VERSION "HNNBNNNYNNNNNNNNNNNNNNNNNNNNNNNNNNNNNNNNNN/4/%%%/4/'%**4NNN///"

NS_ :

BS_:

BU_: BAP_Tester BCM1 Gateway Klima_MSB Lift_VA VAS_L VAS_R

BO_ 1432 BCM_Taster_02: 8 BCM1
 SG_ BCM_BFS_Fernsteuerung_aktiv : 28|1@1+ (1.0,0.0) [0.0|1] ""  Gateway
 SG_ BCM_Soundklappe_Taster : 29|1@1+ (1.0,0.0) [0.0|1] ""  Gateway
 SG_ E_Sound_LED_Status : 30|2@1+ (1.0,0.0) [0.0|3] ""  Gateway
 SG_ Pilot_Taster : 32|2@1+ (1.0,0.0) [0.0|3] ""  Gateway
 SG_ BCM1_eSound_Taster : 34|2@1+ (1.0,0.0) [0.0|3] ""  Gateway
 SG_ BCM_FS_Programmwippe : 37|1@1+ (1.0,0.0) [0.0|1] ""  Gateway
 SG_ BCM_BFS_Programmwippe : 38|1@1+ (1.0,0.0) [0.0|1] ""  Gateway
 SG_ BCM_FS_Multif_Taster : 39|1@1+ (1.0,0.0) [0.0|1] ""  Gateway
 SG_ BCM_BFS_Multif_Taster : 40|1@1+ (1.0,0.0) [0.0|1] ""  Gateway
 SG_ BCM_FS_Massage_Taster : 41|1@1+ (1.0,0.0) [0.0|1] ""  Gateway
 SG_ BCM_BFS_Massage_Taster : 42|1@1+ (1.0,0.0) [0.0|1] ""  Gateway
 SG_ BCM_FS_Pneumatik_Verstellung : 43|1@1+ (1.0,0.0) [0.0|1] ""  Gateway
 SG_ BCM_BFS_Pneumatik_Verstellung : 44|1@1+ (1.0,0.0) [0.0|1] ""  Gateway
 SG_ LIM_Rear_Mode : 45|1@1+ (1.0,0.0) [0.0|1] ""  Gateway
 SG_ BCM1_NR_Ride_Height_Up_Taster : 46|2@1+ (1.0,0.0) [0.0|3] ""  Gateway
 SG_ BCM1_NR_Ride_Height_Down_Taster : 48|2@1+ (1.0,0.0) [0.0|3] ""  Gateway
 SG_ LIM_S_Rollo_vo : 50|3@1+ (1.0,0.0) [0.0|7] ""  Gateway
 SG_ LIM_S_Rollo_hi : 53|3@1+ (1.0,0.0) [0.0|7] ""  Gateway
 SG_ LIM_S_SAD_Vo : 56|4@1+ (1.0,0.0) [0.0|15] ""  Gateway
 SG_ LIM_S_SAD_hi : 60|4@1+ (1.0,0.0) [0.0|15] ""  Gateway

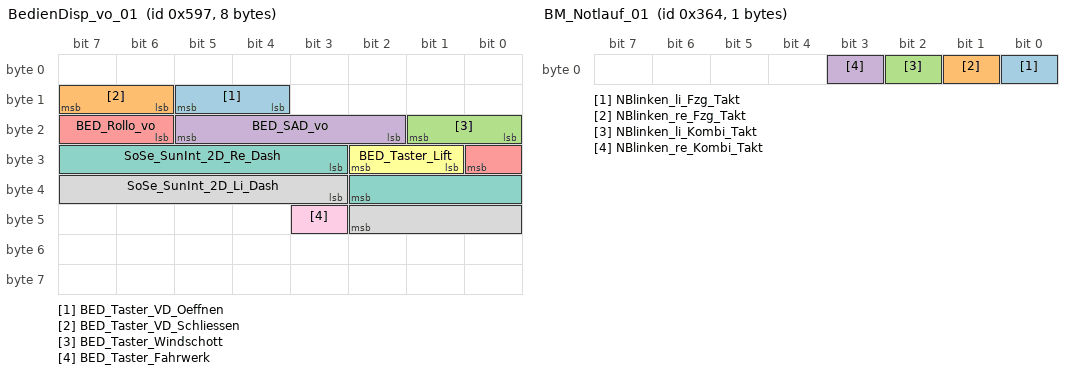
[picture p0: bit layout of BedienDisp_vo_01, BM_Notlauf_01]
BO_ 1431 BedienDisp_vo_01: 8 Gateway
 SG_ BED_Taster_VD_Oeffnen : 12|2@1+ (1.0,0.0) [0.0|3] ""  Vector__XXX
 SG_ BED_Taster_VD_Schliessen : 14|2@1+ (1.0,0.0) [0.0|3] ""  Vector__XXX
 SG_ BED_Taster_Windschott : 16|2@1+ (1.0,0.0) [0.0|3] ""  Vector__XXX
 SG_ BED_SAD_vo : 18|4@1+ (1.0,0.0) [0.0|15] ""  Vector__XXX
 SG_ BED_Rollo_vo : 22|3@1+ (1.0,0.0) [0.0|7] ""  Vector__XXX
 SG_ BED_Taster_Lift : 25|2@1+ (1.0,0.0) [0.0|3] ""  Lift_VA
 SG_ SoSe_SunInt_2D_Re_Dash : 27|8@1+ (5,0) [0|1200] "Unit_WattPerMeterSquar"  BCM1
 SG_ SoSe_SunInt_2D_Li_Dash : 35|8@1+ (5,0) [0|1200] "Unit_WattPerMeterSquar"  BCM1
 SG_ BED_Taster_Fahrwerk : 43|1@1+ (1.0,0.0) [0.0|1] ""  Vector__XXX

BO_ 870 Blinkmodi_02: 8 Gateway
 SG_ BM_ZV_auf : 12|1@1+ (1.0,0.0) [0.0|1] ""  BCM1
 SG_ BM_ZV_zu : 13|1@1+ (1.0,0.0) [0.0|1] ""  BCM1
 SG_ BM_DWA_ein : 14|1@1+ (1.0,0.0) [0.0|1] ""  BCM1
 SG_ BM_DWA_Alarm : 15|1@1+ (1.0,0.0) [0.0|1] ""  BCM1
 SG_ BM_Crash : 16|1@1+ (1.0,0.0) [0.0|1] ""  BCM1
 SG_ BM_Panik : 17|1@1+ (1.0,0.0) [0.0|1] ""  BCM1
 SG_ BM_Not_Bremsung : 18|1@1+ (1.0,0.0) [0.0|1] ""  BCM1
 SG_ BM_GDO : 19|1@1+ (1.0,0.0) [0.0|1] ""  BCM1
 SG_ BM_Warnblinken : 20|1@1+ (1.0,0.0) [0.0|1] ""  BCM1
 SG_ BM_Taxi_Notalarm : 21|1@1+ (1.0,0.0) [0.0|1] ""  BCM1
 SG_ BM_Telematik : 22|1@1+ (1.0,0.0) [0.0|1] ""  BCM1
 SG_ BM_links : 23|1@1+ (1.0,0.0) [0.0|1] ""  BCM1
 SG_ BM_rechts : 24|1@1+ (1.0,0.0) [0.0|1] ""  BCM1
 SG_ Blinken_li_Fzg_Takt : 25|1@1+ (1.0,0.0) [0.0|1] ""  BCM1,VAS_L
 SG_ Blinken_re_Fzg_Takt : 26|1@1+ (1.0,0.0) [0.0|1] ""  BCM1,VAS_R
 SG_ Blinken_li_Kombi_Takt : 27|1@1+ (1.0,0.0) [0.0|1] ""  Vector__XXX
 SG_ Blinken_re_Kombi_Takt : 28|1@1+ (1.0,0.0) [0.0|1] ""  Vector__XXX
 SG_ BM_NBA_n_codiert_n_aktiv : 29|1@1+ (1.0,0.0) [0.0|1] ""  Vector__XXX
 SG_ BM_NBA_Status : 30|2@1+ (1.0,0.0) [0.0|3] ""  Vector__XXX
 SG_ BM_WBT_Beleuchtung : 32|1@1+ (1.0,0.0) [0.0|1] ""  BCM1
 SG_ BM_HD_Oeffnung_angelernt : 33|1@1+ (1.0,0.0) [0.0|1] ""  BCM1
 SG_ BM_Autobahn : 34|1@1+ (1.0,0.0) [0.0|1] ""  BCM1
 SG_ BM_Rollenmodus_Blinken : 35|1@1+ (1.0,0.0) [0.0|1] ""  BCM1
 SG_ BM_Recas : 36|1@1+ (1.0,0.0) [0.0|1] ""  BCM1
 SG_ BM_Wischblinken : 37|1@1+ (1.0,0.0) [0.0|1] ""  BCM1
 SG_ BM_Telematik_Abbruchgrund : 38|6@1+ (1.0,0.0) [0.0|63] ""  Vector__XXX
 SG_ BM_PiloPa : 44|1@1+ (1.0,0.0) [0.0|1] ""  BCM1
 SG_ DWA_Alarmquelle : 59|5@1+ (1.0,0.0) [0.0|31] ""  Vector__XXX

BO_ 868 BM_Notlauf_01: 1 BCM1
 SG_ NBlinken_li_Fzg_Takt : 0|1@1+ (1.0,0.0) [0.0|1] ""  Gateway
 SG_ NBlinken_re_Fzg_Takt : 1|1@1+ (1.0,0.0) [0.0|1] ""  Gateway
 SG_ NBlinken_li_Kombi_Takt : 2|1@1+ (1.0,0.0) [0.0|1] ""  Gateway
 SG_ NBlinken_re_Kombi_Takt : 3|1@1+ (1.0,0.0) [0.0|1] ""  Gateway

BO_ 2617128448 CCP_Klima_CRO_01: 8 Vector__XXX
 SG_ CCP_Klima_CRO_01_Data : 0|64@1+ (1,0) [0|1] ""  BCM1,Klima_MSB

BO_ 2617128449 CCP_Klima_DTO_01: 8 BCM1
 SG_ CCP_Klima_DTO_01_Data : 0|64@1+ (1,0) [0|1] ""  Vector__XXX

BO_ 2617167360 CCP_Lift_VA_CRO_01: 8 Vector__XXX
 SG_ CCP_Lift_VA_CRO_01_Data : 0|64@1+ (1.0,0.0) [0.0|18446744073709551615] ""  Lift_VA

BO_ 2617167361 CCP_Lift_VA_DTO_01: 8 Lift_VA
 SG_ CCP_Lift_VA_DTO_01_Data : 0|64@1+ (1.0,0.0) [0.0|18446744073709551615] ""  Vector__XXX

BO_ 901 Charisma_01: 8 Gateway
 SG_ CHA_Ziel_FahrPr_AGA : 0|4@1+ (1.0,0.0) [0.0|15] ""  Vector__XXX
 SG_ CHA_Ziel_FahrPr_ESP : 4|4@1+ (1.0,0.0) [0.0|15] ""  Vector__XXX
 SG_ CHA_Ziel_FahrPr_Freilauf : 8|4@1+ (1.0,0.0) [0.0|15] ""  Vector__XXX
 SG_ CHA_Fahrer_Umschaltung : 14|1@1+ (1.0,0.0) [0.0|1] ""  Vector__XXX
 SG_ CHA_Fahrer_Umschaltung_BMA : 15|1@1+ (1.0,0.0) [0.0|1] ""  Vector__XXX
 SG_ CHA_Ziel_FahrPr_MO : 16|4@1+ (1.0,0.0) [0.0|15] ""  Vector__XXX
 SG_ CHA_Ziel_FahrPr_GE : 20|4@1+ (1.0,0.0) [0.0|15] ""  Vector__XXX
 SG_ CHA_Ziel_FahrPr_ALR : 24|4@1+ (1.0,0.0) [0.0|15] ""  Vector__XXX
 SG_ CHA_Ziel_FahrPr_MO_BZS : 28|4@1+ (1.0,0.0) [0.0|15] ""  BCM1
 SG_ CHA_Ziel_FahrPr_DR : 32|4@1+ (1.0,0.0) [0.0|15] ""  Vector__XXX
 SG_ CHA_Ziel_FahrPr_VAQ : 36|4@1+ (1.0,0.0) [0.0|15] ""  Vector__XXX
 SG_ CHA_Ziel_FahrPr_AFS : 40|4@1+ (1.0,0.0) [0.0|15] ""  BCM1
 SG_ CHA_Ziel_FahrPr_PreCrash : 44|4@1+ (1.0,0.0) [0.0|15] ""  Vector__XXX
 SG_ CHA_Ziel_FahrPr_EPS : 48|4@1+ (1.0,0.0) [0.0|15] ""  Vector__XXX
 SG_ CHA_Ziel_FahrPr_ACC : 52|4@1+ (1.0,0.0) [0.0|15] ""  Vector__XXX
 SG_ CHA_Ziel_FahrPr_SAK : 56|4@1+ (1.0,0.0) [0.0|15] ""  Vector__XXX
 SG_ CHA_Ziel_FahrPr_MO_StSt : 60|4@1+ (1.0,0.0) [0.0|15] ""  Vector__XXX

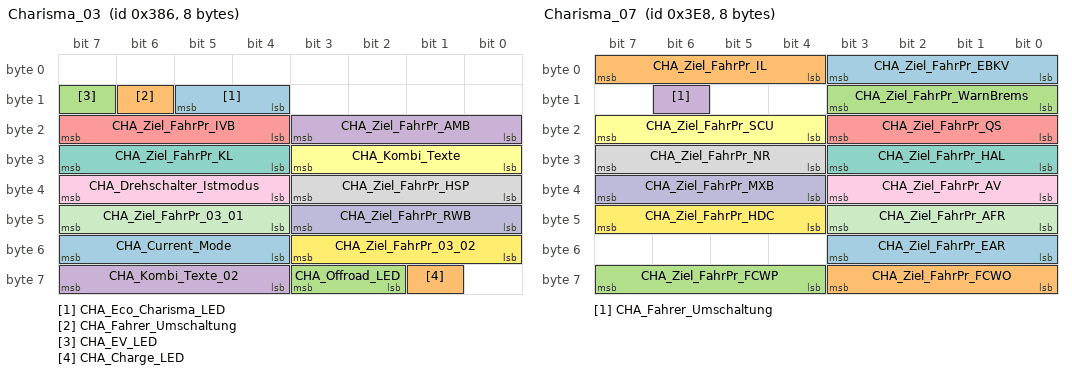
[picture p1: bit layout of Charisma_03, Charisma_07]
BO_ 902 Charisma_03: 8 Gateway
 SG_ CHA_Eco_Charisma_LED : 12|2@1+ (1.0,0.0) [0.0|3] ""  BCM1
 SG_ CHA_Fahrer_Umschaltung : 14|1@1+ (1.0,0.0) [0.0|1] ""  BCM1,Klima_MSB
 SG_ CHA_EV_LED : 15|1@1+ (1.0,0.0) [0.0|1] ""  BCM1
 SG_ CHA_Ziel_FahrPr_AMB : 16|4@1+ (1.0,0.0) [0.0|15] ""  BCM1
 SG_ CHA_Ziel_FahrPr_IVB : 20|4@1+ (1.0,0.0) [0.0|15] ""  Vector__XXX
 SG_ CHA_Kombi_Texte : 24|4@1+ (1.0,0.0) [0.0|15] ""  Vector__XXX
 SG_ CHA_Ziel_FahrPr_KL : 28|4@1+ (1.0,0.0) [0.0|15] ""  BCM1,Klima_MSB
 SG_ CHA_Ziel_FahrPr_HSP : 32|4@1+ (1.0,0.0) [0.0|15] ""  Vector__XXX
 SG_ CHA_Drehschalter_Istmodus : 36|4@1+ (1.0,0.0) [0.0|15] ""  BCM1
 SG_ CHA_Ziel_FahrPr_RWB : 40|4@1+ (1.0,0.0) [0.0|15] ""  Vector__XXX
 SG_ CHA_Ziel_FahrPr_03_01 : 44|4@1+ (1.0,0.0) [0.0|15] ""  Vector__XXX
 SG_ CHA_Ziel_FahrPr_03_02 : 48|4@1+ (1.0,0.0) [0.0|15] ""  Vector__XXX
 SG_ CHA_Current_Mode : 52|4@1+ (1.0,0.0) [0.0|15] ""  Vector__XXX
 SG_ CHA_Charge_LED : 57|1@1+ (1.0,0.0) [0.0|1] ""  Vector__XXX
 SG_ CHA_Offroad_LED : 58|2@1+ (1.0,0.0) [0.0|3] ""  Vector__XXX
 SG_ CHA_Kombi_Texte_02 : 60|4@1+ (1.0,0.0) [0.0|15] ""  Vector__XXX

BO_ 1000 Charisma_07: 8 Gateway
 SG_ CHA_Ziel_FahrPr_EBKV : 0|4@1+ (1.0,0.0) [0.0|15] ""  Vector__XXX
 SG_ CHA_Ziel_FahrPr_IL : 4|4@1+ (1.0,0.0) [0.0|15] ""  Vector__XXX
 SG_ CHA_Ziel_FahrPr_WarnBrems : 8|4@1+ (1.0,0.0) [0.0|15] ""  Vector__XXX
 SG_ CHA_Fahrer_Umschaltung : 14|1@1+ (1.0,0.0) [0.0|1] ""  Vector__XXX
 SG_ CHA_Ziel_FahrPr_QS : 16|4@1+ (1.0,0.0) [0.0|15] ""  Vector__XXX
 SG_ CHA_Ziel_FahrPr_SCU : 20|4@1+ (1.0,0.0) [0.0|15] ""  Vector__XXX
 SG_ CHA_Ziel_FahrPr_HAL : 24|4@1+ (1.0,0.0) [0.0|15] ""  Vector__XXX
 SG_ CHA_Ziel_FahrPr_NR : 28|4@1+ (1.0,0.0) [0.0|15] ""  Vector__XXX
 SG_ CHA_Ziel_FahrPr_AV : 32|4@1+ (1.0,0.0) [0.0|15] ""  BCM1
 SG_ CHA_Ziel_FahrPr_MXB : 36|4@1+ (1.0,0.0) [0.0|15] ""  Vector__XXX
 SG_ CHA_Ziel_FahrPr_AFR : 40|4@1+ (1.0,0.0) [0.0|15] ""  Vector__XXX
 SG_ CHA_Ziel_FahrPr_HDC : 44|4@1+ (1.0,0.0) [0.0|15] ""  Vector__XXX
 SG_ CHA_Ziel_FahrPr_EAR : 48|4@1+ (1.0,0.0) [0.0|15] ""  Vector__XXX
 SG_ CHA_Ziel_FahrPr_FCWO : 56|4@1+ (1.0,0.0) [0.0|15] ""  Vector__XXX
 SG_ CHA_Ziel_FahrPr_FCWP : 60|4@1+ (1.0,0.0) [0.0|15] ""  Vector__XXX

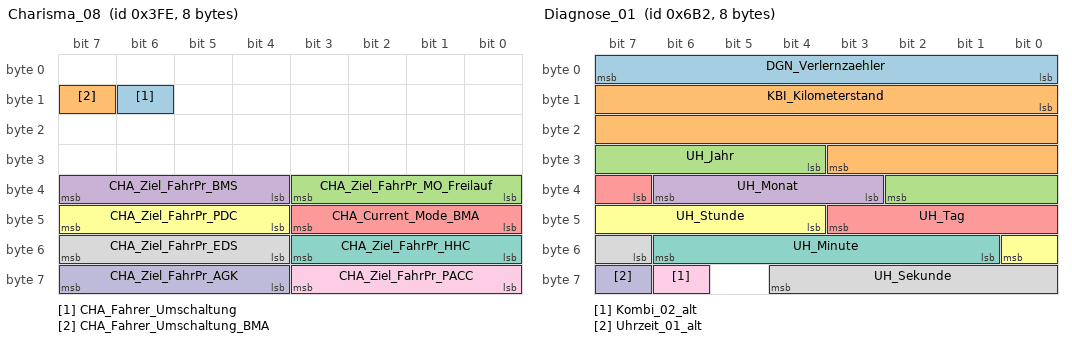
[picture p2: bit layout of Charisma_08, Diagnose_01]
BO_ 1022 Charisma_08: 8 Gateway
 SG_ CHA_Fahrer_Umschaltung : 14|1@1+ (1.0,0.0) [0.0|1] ""  Vector__XXX
 SG_ CHA_Fahrer_Umschaltung_BMA : 15|1@1+ (1.0,0.0) [0.0|1] ""  Vector__XXX
 SG_ CHA_Ziel_FahrPr_MO_Freilauf : 32|4@1+ (1.0,0.0) [0.0|15] ""  Vector__XXX
 SG_ CHA_Ziel_FahrPr_BMS : 36|4@1+ (1.0,0.0) [0.0|15] ""  Vector__XXX
 SG_ CHA_Current_Mode_BMA : 40|4@1+ (1.0,0.0) [0.0|15] ""  Vector__XXX
 SG_ CHA_Ziel_FahrPr_PDC : 44|4@1+ (1.0,0.0) [0.0|15] ""  BCM1
 SG_ CHA_Ziel_FahrPr_HHC : 48|4@1+ (1.0,0.0) [0.0|15] ""  Vector__XXX
 SG_ CHA_Ziel_FahrPr_EDS : 52|4@1+ (1.0,0.0) [0.0|15] ""  Vector__XXX
 SG_ CHA_Ziel_FahrPr_PACC : 56|4@1+ (1.0,0.0) [0.0|15] ""  Vector__XXX
 SG_ CHA_Ziel_FahrPr_AGK : 60|4@1+ (1.0,0.0) [0.0|15] ""  Vector__XXX

BO_ 2617012736 DEV_BCM1_Resp_00: 8 BCM1
 SG_ DEV_BCM1_Resp_00_Data : 0|64@1+ (1.0,0.0) [0.0|18446744073709551615] ""  Vector__XXX

BO_ 2617012991 DEV_BCM1_Resp_FF: 8 BCM1
 SG_ DEV_BCM1_Resp_FF_Data : 0|64@1+ (1.0,0.0) [0.0|18446744073709551615] ""  Vector__XXX

BO_ 2617037312 DEV_Klima_Fond_Tx_00: 8 BCM1
 SG_ DEV_Klima_Fond_Tx_00_Data : 0|64@1+ (1.0,0.0) [0.0|18446744073709551615] ""  Vector__XXX

BO_ 2617037567 DEV_Klima_Fond_Tx_FF: 8 BCM1
 SG_ DEV_Klima_Fond_Tx_FF_Data : 0|64@1+ (1.0,0.0) [0.0|18446744073709551615] ""  Vector__XXX

BO_ 2617127424 DEV_Klima_Tx_00: 8 BCM1
 SG_ DEV_Klima_Tx_00_Data : 0|64@1+ (1.0,0.0) [0.0|18446744073709551615] ""  Vector__XXX

BO_ 2617127679 DEV_Klima_Tx_FF: 8 BCM1
 SG_ DEV_Klima_Tx_FF_Data : 0|64@1+ (1.0,0.0) [0.0|18446744073709551615] ""  Vector__XXX

BO_ 2617166336 DEV_Lift_VA_Req_01: 8 Vector__XXX
 SG_ DEV_Lift_VA_Req_01_Data : 0|64@1+ (1.0,0.0) [0.0|18446744073709551615] ""  Lift_VA

BO_ 2617166337 DEV_Lift_VA_Resp_01: 8 Lift_VA
 SG_ DEV_Lift_VA_Resp_01_Data : 0|64@1+ (1.0,0.0) [0.0|18446744073709551615] ""  Vector__XXX

BO_ 2617166591 DEV_Lift_VA_Resp_FF: 8 Lift_VA
 SG_ DEV_Lift_VA_Resp_FF_Data : 0|64@1+ (1.0,0.0) [0.0|18446744073709551615] ""  Vector__XXX

BO_ 2617123584 DEV_VAS_L_Resp_00: 8 VAS_L
 SG_ DEV_VAS_L_Resp_00_Data : 0|64@1+ (1.0,0.0) [0.0|18446744073709551615] ""  Vector__XXX

BO_ 2617123839 DEV_VAS_L_Resp_FF: 8 VAS_L
 SG_ DEV_VAS_L_Resp_FF_Data : 0|64@1+ (1.0,0.0) [0.0|18446744073709551615] ""  Vector__XXX

BO_ 2617125632 DEV_VAS_R_Resp_00: 8 VAS_R
 SG_ DEV_VAS_R_Resp_00_Data : 0|64@1+ (1.0,0.0) [0.0|18446744073709551615] ""  Vector__XXX

BO_ 2617125887 DEV_VAS_R_Resp_FF: 8 VAS_R
 SG_ DEV_VAS_R_Resp_FF_Data : 0|64@1+ (1.0,0.0) [0.0|18446744073709551615] ""  Vector__XXX

BO_ 2549880614 DIA_AAU_Req: 8 Gateway
 SG_ DIA_AAU_Req_Data : 0|64@1+ (1.0,0.0) [0.0|18446744073709551615] ""  BCM1,Klima_MSB

BO_ 2550011686 DIA_AAU_Resp: 8 BCM1
 SG_ DIA_AAU_Resp_Data : 0|64@1+ (1.0,0.0) [0.0|18446744073709551615] ""  Gateway

BO_ 2549880393 DIA_EVLS_Req: 8 Gateway
 SG_ DIA_EVLS_Req_Data : 0|64@1+ (1.0,0.0) [0.0|18446744073709551615] ""  BCM1

BO_ 2550011465 DIA_EVLS_Resp: 8 BCM1
 SG_ DIA_EVLS_Resp_Data : 0|64@1+ (1.0,0.0) [0.0|18446744073709551615] ""  Gateway

BO_ 2549880347 DIA_Geblaese_Req: 8 Gateway
 SG_ DIA_Geblaese_Req_Data : 0|64@1+ (1.0,0.0) [0.0|18446744073709551615] ""  BCM1,Klima_MSB

BO_ 2550011419 DIA_Geblaese_Resp: 8 BCM1
 SG_ DIA_Geblaese_Resp_Data : 0|64@1+ (1.0,0.0) [0.0|18446744073709551615] ""  Gateway

BO_ 2549880340 DIA_gLW_LM_L_Req: 8 Gateway
 SG_ DIA_gLW_LM_L_Req_Data : 0|64@1+ (1.0,0.0) [0.0|18446744073709551615] ""  BCM1

BO_ 2550011412 DIA_gLW_LM_L_Resp: 8 BCM1
 SG_ DIA_gLW_LM_L_Resp_Data : 0|64@1+ (1.0,0.0) [0.0|18446744073709551615] ""  Gateway

BO_ 2549880341 DIA_gLW_LM_R_Req: 8 Gateway
 SG_ DIA_gLW_LM_R_Req_Data : 0|64@1+ (1.0,0.0) [0.0|18446744073709551615] ""  BCM1

BO_ 2550011413 DIA_gLW_LM_R_Resp: 8 BCM1
 SG_ DIA_gLW_LM_R_Resp_Data : 0|64@1+ (1.0,0.0) [0.0|18446744073709551615] ""  Gateway

BO_ 2549880577 DIA_KBF_Req: 8 Gateway
 SG_ DIA_KBF_Req_Data : 0|64@1+ (1.0,0.0) [0.0|18446744073709551615] ""  BCM1,Klima_MSB

BO_ 2550011649 DIA_KBF_Resp: 8 BCM1
 SG_ DIA_KBF_Resp_Data : 0|64@1+ (1.0,0.0) [0.0|18446744073709551615] ""  Gateway

BO_ 2549880639 DIA_KPV_Req: 8 Gateway
 SG_ DIA_KPV_Req_Data : 0|64@1+ (1.0,0.0) [0.0|18446744073709551615] ""  BCM1

BO_ 2550011711 DIA_KPV_Resp: 8 BCM1
 SG_ DIA_KPV_Resp_Data : 0|64@1+ (1.0,0.0) [0.0|18446744073709551615] ""  Gateway

BO_ 2549880330 DIA_LED_LM_L_Req: 8 Gateway
 SG_ DIA_LED_LM_L_Req_Data : 0|64@1+ (1.0,0.0) [0.0|18446744073709551615] ""  BCM1

BO_ 2550011402 DIA_LED_LM_L_Resp: 8 BCM1
 SG_ DIA_LED_LM_L_Resp_Data : 0|64@1+ (1.0,0.0) [0.0|18446744073709551615] ""  Gateway

BO_ 2549880331 DIA_LED_LM_R_Req: 8 Gateway
 SG_ DIA_LED_LM_R_Req_Data : 0|64@1+ (1.0,0.0) [0.0|18446744073709551615] ""  BCM1

BO_ 2550011403 DIA_LED_LM_R_Resp: 8 BCM1
 SG_ DIA_LED_LM_R_Resp_Data : 0|64@1+ (1.0,0.0) [0.0|18446744073709551615] ""  Gateway

BO_ 2549880633 DIA_LIM2_Req: 8 Gateway
 SG_ DIA_LIM2_Req_Data : 0|64@1+ (1.0,0.0) [0.0|18446744073709551615] ""  BCM1

BO_ 2550011705 DIA_LIM2_Resp: 8 BCM1
 SG_ DIA_LIM2_Resp_Data : 0|64@1+ (1.0,0.0) [0.0|18446744073709551615] ""  Gateway

BO_ 2549880350 DIA_LIM_Req: 8 Gateway
 SG_ DIA_LIM_Req_Data : 0|64@1+ (1.0,0.0) [0.0|18446744073709551615] ""  BCM1

BO_ 2550011422 DIA_LIM_Resp: 8 BCM1
 SG_ DIA_LIM_Resp_Data : 0|64@1+ (1.0,0.0) [0.0|18446744073709551615] ""  Gateway

BO_ 2549880427 DIA_MXB_LM_L_Req: 8 Gateway
 SG_ DIA_MXB_LM_L_Req_Data : 0|64@1+ (1.0,0.0) [0.0|18446744073709551615] ""  BCM1

BO_ 2550011499 DIA_MXB_LM_L_Resp: 8 BCM1
 SG_ DIA_MXB_LM_L_Resp_Data : 0|64@1+ (1.0,0.0) [0.0|18446744073709551615] ""  Gateway

BO_ 2549880428 DIA_MXB_LM_R_Req: 8 Gateway
 SG_ DIA_MXB_LM_R_Req_Data : 0|64@1+ (1.0,0.0) [0.0|18446744073709551615] ""  BCM1

BO_ 2550011500 DIA_MXB_LM_R_Resp: 8 BCM1
 SG_ DIA_MXB_LM_R_Resp_Data : 0|64@1+ (1.0,0.0) [0.0|18446744073709551615] ""  Gateway

BO_ 2549880612 DIA_SWP_Req: 8 Gateway
 SG_ DIA_SWP_Req_Data : 0|64@1+ (1.0,0.0) [0.0|18446744073709551615] ""  BCM1

BO_ 2550011684 DIA_SWP_Resp: 8 BCM1
 SG_ DIA_SWP_Resp_Data : 0|64@1+ (1.0,0.0) [0.0|18446744073709551615] ""  Gateway

BO_ 2549880324 DIA_UGDO_S_Req: 8 Gateway
 SG_ DIA_UGDO_S_Req_Data : 0|64@1+ (1.0,0.0) [0.0|18446744073709551615] ""  BCM1

BO_ 2550011396 DIA_UGDO_S_Resp: 8 BCM1
 SG_ DIA_UGDO_S_Resp_Data : 0|64@1+ (1.0,0.0) [0.0|18446744073709551615] ""  Gateway

BO_ 2549880321 DIA_WWS_Req: 8 Gateway
 SG_ DIA_WWS_Req_Data : 0|64@1+ (1.0,0.0) [0.0|18446744073709551615] ""  BCM1

BO_ 2550011393 DIA_WWS_Resp: 8 BCM1
 SG_ DIA_WWS_Resp_Data : 0|64@1+ (1.0,0.0) [0.0|18446744073709551615] ""  Gateway

BO_ 1714 Diagnose_01: 8 Gateway
 SG_ DGN_Verlernzaehler : 0|8@1+ (1,0) [0|254] ""  BCM1,Klima_MSB,Lift_VA,VAS_L,VAS_R
 SG_ KBI_Kilometerstand : 8|20@1+ (1,0) [0|1048573] "Unit_KiloMeter"  BCM1,Klima_MSB,Lift_VA,VAS_L
 SG_ UH_Jahr : 28|7@1+ (1,2000) [2000|2127] "Unit_Year"  BCM1,Klima_MSB,Lift_VA,VAS_L,VAS_R
 SG_ UH_Monat : 35|4@1+ (1,0) [1|12] "Unit_Month"  BCM1,Klima_MSB,Lift_VA,VAS_L,VAS_R
 SG_ UH_Tag : 39|5@1+ (1,0) [1|31] "Unit_Day"  BCM1,Klima_MSB,Lift_VA,VAS_L,VAS_R
 SG_ UH_Stunde : 44|5@1+ (1,0) [0|23] "Unit_Hours"  BCM1,Klima_MSB,Lift_VA,VAS_L,VAS_R
 SG_ UH_Minute : 49|6@1+ (1,0) [0|59] "Unit_Minut"  BCM1,Klima_MSB,Lift_VA,VAS_L,VAS_R
 SG_ UH_Sekunde : 55|6@1+ (1,0) [0|59] "Unit_Secon"  BCM1,Klima_MSB,Lift_VA,VAS_L,VAS_R
 SG_ Kombi_02_alt : 62|1@1+ (1.0,0.0) [0.0|1] ""  Vector__XXX
 SG_ Uhrzeit_01_alt : 63|1@1+ (1.0,0.0) [0.0|1] ""  BCM1,VAS_L,VAS_R

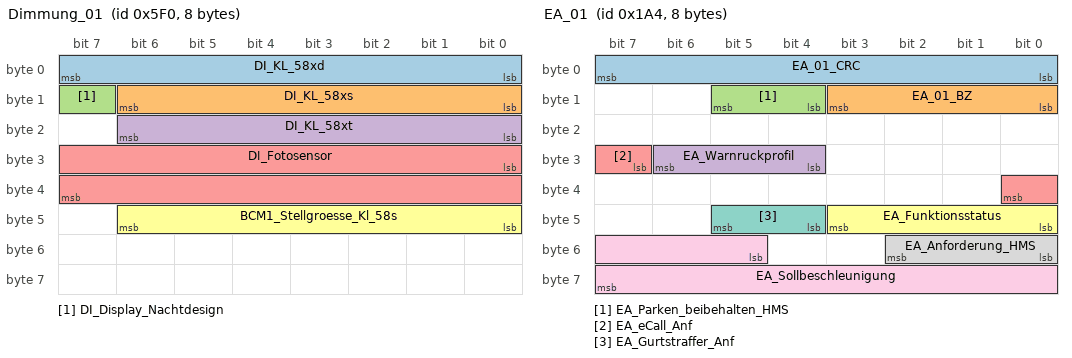
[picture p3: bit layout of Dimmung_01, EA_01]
BO_ 1520 Dimmung_01: 8 BCM1
 SG_ DI_KL_58xd : 0|8@1+ (1,0) [0|253] ""  Gateway,Klima_MSB,VAS_L,VAS_R
 SG_ DI_KL_58xs : 8|7@1+ (1,0) [0|100] "Unit_PerCent"  Gateway,Klima_MSB,VAS_L,VAS_R
 SG_ DI_Display_Nachtdesign : 15|1@1+ (1.0,0.0) [0.0|1] ""  Gateway,VAS_L,VAS_R
 SG_ DI_KL_58xt : 16|7@1+ (1,0) [0|100] "Unit_PerCent"  Gateway,VAS_L,VAS_R
 SG_ DI_Fotosensor : 24|16@1+ (1,0) [0|65535] ""  Gateway,VAS_L,VAS_R
 SG_ BCM1_Stellgroesse_Kl_58s : 40|7@1+ (1,0) [0|100] ""  Gateway

BO_ 420 EA_01: 8 Gateway
 SG_ EA_01_CRC : 0|8@1+ (1,0) [0|255] ""  Vector__XXX
 SG_ EA_01_BZ : 8|4@1+ (1,0) [0|15] ""  Vector__XXX
 SG_ EA_Parken_beibehalten_HMS : 12|2@1+ (1.0,0.0) [0.0|3] ""  Vector__XXX
 SG_ EA_Warnruckprofil : 28|3@1+ (1.0,0.0) [0.0|7] ""  Vector__XXX
 SG_ EA_eCall_Anf : 31|2@1+ (1.0,0.0) [0.0|3] ""  Vector__XXX
 SG_ EA_Funktionsstatus : 40|4@1+ (1.0,0.0) [0.0|15] ""  BCM1
 SG_ EA_Gurtstraffer_Anf : 44|2@1+ (1.0,0.0) [0.0|3] ""  Vector__XXX
 SG_ EA_Anforderung_HMS : 48|3@1+ (1.0,0.0) [0.0|7] ""  Vector__XXX
 SG_ EA_Sollbeschleunigung : 53|11@1+ (0.005,-7.22) [-7.220|3.005] "Unit_MeterPerSeconSquar"  Vector__XXX

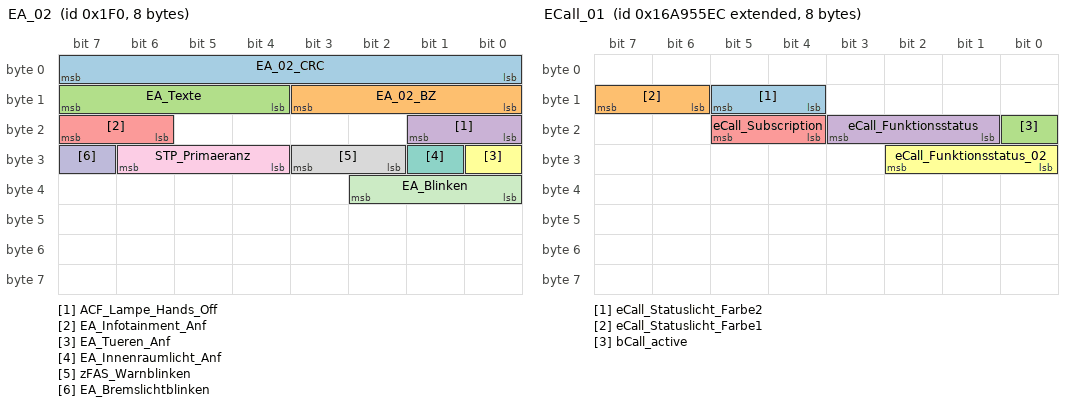
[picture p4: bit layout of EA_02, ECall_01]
BO_ 496 EA_02: 8 Gateway
 SG_ EA_02_CRC : 0|8@1+ (1,0) [0|255] ""  Vector__XXX
 SG_ EA_02_BZ : 8|4@1+ (1,0) [0|15] ""  Vector__XXX
 SG_ EA_Texte : 12|4@1+ (1.0,0.0) [0.0|15] ""  Vector__XXX
 SG_ ACF_Lampe_Hands_Off : 16|2@1+ (1.0,0.0) [0.0|3] ""  Vector__XXX
 SG_ EA_Infotainment_Anf : 22|2@1+ (1.0,0.0) [0.0|3] ""  Vector__XXX
 SG_ EA_Tueren_Anf : 24|1@1+ (1.0,0.0) [0.0|1] ""  Vector__XXX
 SG_ EA_Innenraumlicht_Anf : 25|1@1+ (1.0,0.0) [0.0|1] ""  BCM1
 SG_ zFAS_Warnblinken : 26|2@1+ (1.0,0.0) [0.0|3] ""  Vector__XXX
 SG_ STP_Primaeranz : 28|3@1+ (1.0,0.0) [0.0|7] ""  Vector__XXX
 SG_ EA_Bremslichtblinken : 31|1@1+ (1.0,0.0) [0.0|1] ""  Vector__XXX
 SG_ EA_Blinken : 32|3@1+ (1.0,0.0) [0.0|7] ""  Vector__XXX

BO_ 2527679980 ECall_01: 8 Gateway
 SG_ eCall_Statuslicht_Farbe2 : 12|2@1+ (1.0,0.0) [0.0|3] ""  BCM1
 SG_ eCall_Statuslicht_Farbe1 : 14|2@1+ (1.0,0.0) [0.0|3] ""  BCM1
 SG_ bCall_active : 16|1@1+ (1.0,0.0) [0.0|1] ""  BCM1
 SG_ eCall_Funktionsstatus : 17|3@1+ (1.0,0.0) [0.0|7] ""  Vector__XXX
 SG_ eCall_Subscription : 20|2@1+ (1.0,0.0) [0.0|3] ""  Vector__XXX
 SG_ eCall_Funktionsstatus_02 : 24|3@1+ (1.0,0.0) [0.0|7] ""  Vector__XXX

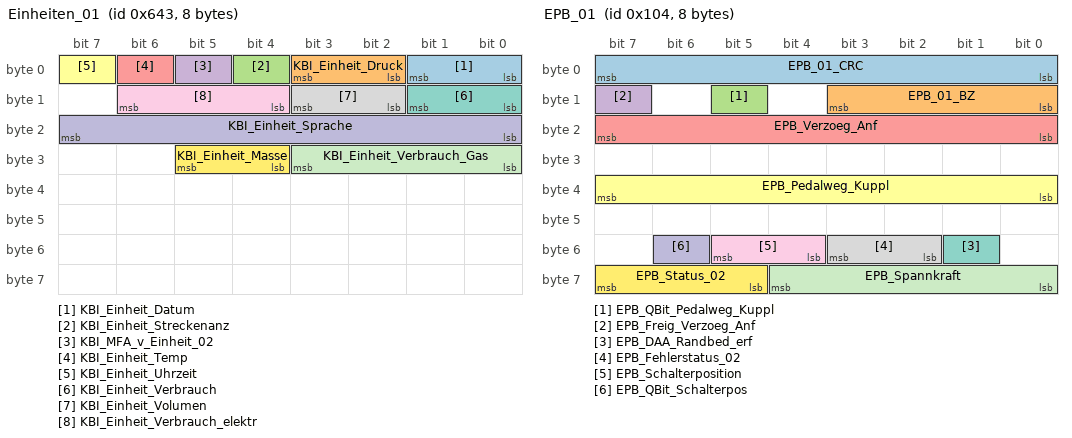
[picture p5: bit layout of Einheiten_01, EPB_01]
BO_ 1603 Einheiten_01: 8 Gateway
 SG_ KBI_Einheit_Datum : 0|2@1+ (1.0,0.0) [0.0|3] ""  Vector__XXX
 SG_ KBI_Einheit_Druck : 2|2@1+ (1.0,0.0) [0.0|3] ""  Vector__XXX
 SG_ KBI_Einheit_Streckenanz : 4|1@1+ (1.0,0.0) [0.0|1] ""  Vector__XXX
 SG_ KBI_MFA_v_Einheit_02 : 5|1@1+ (1.0,0.0) [0.0|1] ""  Vector__XXX
 SG_ KBI_Einheit_Temp : 6|1@1+ (1.0,0.0) [0.0|1] ""  BCM1,Klima_MSB
 SG_ KBI_Einheit_Uhrzeit : 7|1@1+ (1.0,0.0) [0.0|1] ""  Vector__XXX
 SG_ KBI_Einheit_Verbrauch : 8|2@1+ (1.0,0.0) [0.0|3] ""  Vector__XXX
 SG_ KBI_Einheit_Volumen : 10|2@1+ (1.0,0.0) [0.0|3] ""  Vector__XXX
 SG_ KBI_Einheit_Verbrauch_elektr : 12|3@1+ (1.0,0.0) [0.0|7] ""  Vector__XXX
 SG_ KBI_Einheit_Sprache : 16|8@1+ (1,0) [0|255] ""  Vector__XXX
 SG_ KBI_Einheit_Verbrauch_Gas : 24|4@1+ (1.0,0.0) [0.0|15] ""  Vector__XXX
 SG_ KBI_Einheit_Masse : 28|2@1+ (1.0,0.0) [0.0|3] ""  Vector__XXX

BO_ 260 EPB_01: 8 Gateway
 SG_ EPB_01_CRC : 0|8@1+ (1,0) [0|255] ""  Vector__XXX
 SG_ EPB_01_BZ : 8|4@1+ (1,0) [0|15] ""  Vector__XXX
 SG_ EPB_QBit_Pedalweg_Kuppl : 13|1@1+ (1.0,0.0) [0.0|1] ""  Vector__XXX
 SG_ EPB_Freig_Verzoeg_Anf : 15|1@1+ (1.0,0.0) [0.0|1] ""  Vector__XXX
 SG_ EPB_Verzoeg_Anf : 16|8@1+ (0.048,-7.968) [-7.968|4.224] "Unit_MeterPerSeconSquar"  Vector__XXX
 SG_ EPB_Pedalweg_Kuppl : 32|8@1+ (0.4,0) [8.0|92.0] "Unit_PerCent"  Vector__XXX
 SG_ EPB_DAA_Randbed_erf : 49|1@1+ (1.0,0.0) [0.0|1] ""  Vector__XXX
 SG_ EPB_Fehlerstatus_02 : 50|2@1+ (1.0,0.0) [0.0|3] ""  BCM1
 SG_ EPB_Schalterposition : 52|2@1+ (1.0,0.0) [0.0|3] ""  Vector__XXX
 SG_ EPB_QBit_Schalterpos : 54|1@1+ (1.0,0.0) [0.0|1] ""  Vector__XXX
 SG_ EPB_Spannkraft : 56|5@1+ (1,0) [0|29] "Unit_KiloNewto"  Vector__XXX
 SG_ EPB_Status_02 : 61|3@1+ (1.0,0.0) [0.0|7] ""  BCM1

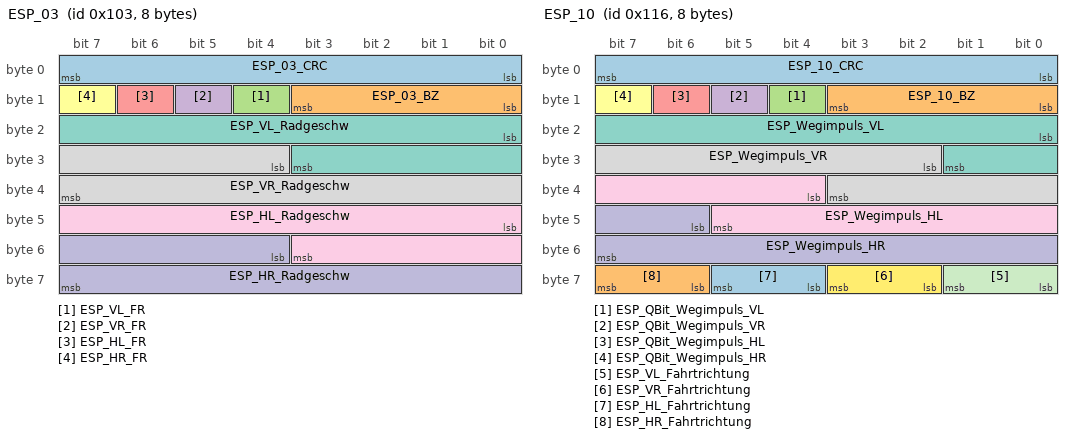
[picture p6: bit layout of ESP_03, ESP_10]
BO_ 259 ESP_03: 8 Gateway
 SG_ ESP_03_CRC : 0|8@1+ (1,0) [0|255] ""  Vector__XXX
 SG_ ESP_03_BZ : 8|4@1+ (1,0) [0|15] ""  Vector__XXX
 SG_ ESP_VL_FR : 12|1@1+ (1.0,0.0) [0.0|1] ""  BCM1,VAS_L,VAS_R
 SG_ ESP_VR_FR : 13|1@1+ (1.0,0.0) [0.0|1] ""  BCM1,VAS_L,VAS_R
 SG_ ESP_HL_FR : 14|1@1+ (1.0,0.0) [0.0|1] ""  BCM1,VAS_L,VAS_R
 SG_ ESP_HR_FR : 15|1@1+ (1.0,0.0) [0.0|1] ""  BCM1,VAS_L,VAS_R
 SG_ ESP_VL_Radgeschw : 16|12@1+ (0.1,0) [0.0|409.2] "Unit_KiloMeterPerHour"  BCM1,VAS_L,VAS_R
 SG_ ESP_VR_Radgeschw : 28|12@1+ (0.1,0) [0.0|409.2] "Unit_KiloMeterPerHour"  BCM1,VAS_L,VAS_R
 SG_ ESP_HL_Radgeschw : 40|12@1+ (0.1,0) [0.0|409.2] "Unit_KiloMeterPerHour"  BCM1,VAS_L,VAS_R
 SG_ ESP_HR_Radgeschw : 52|12@1+ (0.1,0) [0.0|409.2] "Unit_KiloMeterPerHour"  BCM1,VAS_L,VAS_R

BO_ 914 ESP_07: 8 Gateway
 SG_ ESP_07_CRC : 0|8@1+ (1,0) [0|255] ""  Vector__XXX
 SG_ ESP_07_BZ : 8|4@1+ (1,0) [0|15] ""  Vector__XXX
 SG_ ESP_Allrad_Antrieb : 13|1@1+ (1.0,0.0) [0.0|1] ""  Vector__XXX
 SG_ ESP_Codierung_ADS : 14|2@1+ (1.0,0.0) [0.0|3] ""  BCM1
 SG_ ESP_RTA_HL : 16|8@1+ (0.048828125,-6.20117) [-6.201170000|6.152345625] "Unit_PerCent"  Vector__XXX
 SG_ ESP_RTA_HR : 24|8@1+ (0.048828125,-6.20117) [-6.201170000|6.152345625] "Unit_PerCent"  Vector__XXX
 SG_ ESP_RTA_VR : 32|8@1+ (0.048828125,-6.20117) [-6.201170000|6.152345625] "Unit_PerCent"  Vector__XXX
 SG_ OBD_Fehler_Radsensor_HL : 40|4@1+ (1.0,0.0) [0.0|15] ""  Vector__XXX
 SG_ OBD_Fehler_Radsensor_HR : 44|4@1+ (1.0,0.0) [0.0|15] ""  Vector__XXX
 SG_ OBD_Fehler_Radsensor_VL : 48|4@1+ (1.0,0.0) [0.0|15] ""  Vector__XXX
 SG_ OBD_Fehler_Radsensor_VR : 52|4@1+ (1.0,0.0) [0.0|15] ""  Vector__XXX
 SG_ ESP_Qualifizierung_Antriebsart : 56|1@1+ (1.0,0.0) [0.0|1] ""  Vector__XXX
 SG_ ESP_Offroad_Modus : 57|1@1+ (1.0,0.0) [0.0|1] ""  Vector__XXX
 SG_ ESP_MKB_ausloesbar : 58|1@1+ (1.0,0.0) [0.0|1] ""  Vector__XXX
 SG_ ESP_Stat_FallBack_eBKV : 59|1@1+ (1.0,0.0) [0.0|1] ""  Vector__XXX
 SG_ ESC_cAQP_Trigger : 60|1@1+ (1.0,0.0) [0.0|1] ""  Vector__XXX
 SG_ ESP_OBD_Status : 61|1@1+ (1.0,0.0) [0.0|1] ""  Vector__XXX
 SG_ ESP_Rollenmodus_Deaktivieren : 62|1@1+ (1.0,0.0) [0.0|1] ""  BCM1,Klima_MSB
 SG_ ESP_nachtr_Stopp_Anf : 63|1@1+ (1.0,0.0) [0.0|1] ""  Vector__XXX

BO_ 278 ESP_10: 8 Gateway
 SG_ ESP_10_CRC : 0|8@1+ (1,0) [0|255] ""  BCM1
 SG_ ESP_10_BZ : 8|4@1+ (1,0) [0|15] ""  BCM1
 SG_ ESP_QBit_Wegimpuls_VL : 12|1@1+ (1.0,0.0) [0.0|1] ""  BCM1
 SG_ ESP_QBit_Wegimpuls_VR : 13|1@1+ (1.0,0.0) [0.0|1] ""  BCM1
 SG_ ESP_QBit_Wegimpuls_HL : 14|1@1+ (1.0,0.0) [0.0|1] ""  BCM1
 SG_ ESP_QBit_Wegimpuls_HR : 15|1@1+ (1.0,0.0) [0.0|1] ""  BCM1
 SG_ ESP_Wegimpuls_VL : 16|10@1+ (1,0) [0|1000] ""  BCM1
 SG_ ESP_Wegimpuls_VR : 26|10@1+ (1,0) [0|1000] ""  BCM1
 SG_ ESP_Wegimpuls_HL : 36|10@1+ (1,0) [0|1000] ""  BCM1
 SG_ ESP_Wegimpuls_HR : 46|10@1+ (1,0) [0|1000] ""  BCM1
 SG_ ESP_VL_Fahrtrichtung : 56|2@1+ (1.0,0.0) [0.0|3] ""  BCM1
 SG_ ESP_VR_Fahrtrichtung : 58|2@1+ (1.0,0.0) [0.0|3] ""  BCM1
 SG_ ESP_HL_Fahrtrichtung : 60|2@1+ (1.0,0.0) [0.0|3] ""  BCM1
 SG_ ESP_HR_Fahrtrichtung : 62|2@1+ (1.0,0.0) [0.0|3] ""  BCM1

BO_ 418 ESP_15: 8 Gateway
 SG_ ESP_15_CRC : 0|8@1+ (1,0) [0|255] ""  Vector__XXX
 SG_ ESP_15_BZ : 8|4@1+ (1,0) [0|15] ""  Vector__XXX
 SG_ HMS_P_beibehalten_GE : 12|2@1+ (1.0,0.0) [0.0|3] ""  Vector__XXX
 SG_ HMS_Konsistenz_GE : 14|1@1+ (1.0,0.0) [0.0|1] ""  Vector__XXX
 SG_ HMS_Konsistenz_IPA : 15|1@1+ (1.0,0.0) [0.0|1] ""  BCM1
 SG_ HMS_Konsistenz_STA : 18|1@1+ (1.0,0.0) [0.0|1] ""  Vector__XXX
 SG_ HMS_Konsistenz_MO : 19|1@1+ (1.0,0.0) [0.0|1] ""  Vector__XXX
 SG_ HMS_halten_nicht_verfuegbar : 20|1@1+ (1.0,0.0) [0.0|1] ""  Vector__XXX
 SG_ NL_PRIM_STP_01_Status : 21|3@1+ (1.0,0.0) [0.0|7] ""  Vector__XXX
 SG_ VMM_Warnblinken : 24|1@1+ (1.0,0.0) [0.0|1] ""  Vector__XXX
 SG_ VZM_Status : 26|3@1+ (1.0,0.0) [0.0|7] ""  BCM1
 SG_ HMS_Notstopp_Status : 29|3@1+ (1.0,0.0) [0.0|7] ""  Vector__XXX
 SG_ HMS_parken_nicht_verfuegbar : 32|1@1+ (1.0,0.0) [0.0|1] ""  Vector__XXX
 SG_ HMS_Anforderung_GE : 33|3@1+ (1.0,0.0) [0.0|7] ""  Vector__XXX
 SG_ HMS_Systemstatus : 36|4@1+ (1.0,0.0) [0.0|15] ""  BCM1
 SG_ HMS_Stillstand : 40|3@1+ (1.0,0.0) [0.0|7] ""  BCM1
 SG_ HMS_aktives_System : 43|5@1+ (1.0,0.0) [0.0|31] ""  BCM1
 SG_ HMS_Konsistenz_HVLM : 48|1@1+ (1.0,0.0) [0.0|1] ""  Vector__XXX
 SG_ HMS_Konsistenz_ACC : 49|1@1+ (1.0,0.0) [0.0|1] ""  Vector__XXX
 SG_ HMS_Fehlerstatus : 50|3@1+ (1.0,0.0) [0.0|7] ""  BCM1
 SG_ ESP_Index_Haltemoment : 53|1@1+ (1.0,0.0) [0.0|1] ""  Vector__XXX
 SG_ ESP_Haltemoment : 54|10@1+ (10,0) [0|10210] "Unit_NewtoMeter"  Vector__XXX

BO_ 253 ESP_21: 8 Gateway
 SG_ ESP_21_CRC : 0|8@1+ (1,0) [0|255] ""  BCM1
 SG_ ESP_21_BZ : 8|4@1+ (1,0) [0|15] ""  BCM1
 SG_ BR_Eingriffsmoment : 12|10@1+ (1,-509) [-509|509] ""  BCM1
 SG_ ESP_Diagnose : 23|1@1+ (1.0,0.0) [0.0|1] ""  BCM1
 SG_ ESC_v_Signal_Qualifier_High_Low : 24|3@1+ (1.0,0.0) [0.0|7] ""  BCM1
 SG_ ESP_Vorsteuerung : 28|1@1+ (1.0,0.0) [0.0|1] ""  BCM1
 SG_ OBD_Schlechtweg : 30|1@1+ (1.0,0.0) [0.0|1] ""  BCM1
 SG_ OBD_QBit_Schlechtweg : 31|1@1+ (1.0,0.0) [0.0|1] ""  BCM1
 SG_ ESP_v_Signal : 32|16@1+ (0.01,0) [0.00|655.32] "Unit_KiloMeterPerHour"  BCM1,Klima_MSB,Lift_VA,VAS_L,VAS_R
 SG_ ASR_Tastung_passiv : 48|1@1+ (1.0,0.0) [0.0|1] ""  BCM1
 SG_ ESP_Tastung_passiv : 49|1@1+ (1.0,0.0) [0.0|1] ""  BCM1
 SG_ ESP_Systemstatus : 50|1@1+ (1.0,0.0) [0.0|1] ""  BCM1
 SG_ ASR_Schalteingriff : 51|2@1+ (1.0,0.0) [0.0|3] ""  BCM1
 SG_ ESP_QBit_v_Signal : 55|1@1+ (1.0,0.0) [0.0|1] ""  BCM1,Klima_MSB,VAS_L,VAS_R
 SG_ ABS_Bremsung : 56|1@1+ (1.0,0.0) [0.0|1] ""  BCM1
 SG_ ASR_Anf : 57|1@1+ (1.0,0.0) [0.0|1] ""  BCM1
 SG_ MSR_Anf : 58|1@1+ (1.0,0.0) [0.0|1] ""  BCM1
 SG_ EBV_Eingriff : 59|1@1+ (1.0,0.0) [0.0|1] ""  BCM1
 SG_ EDS_Eingriff : 60|1@1+ (1.0,0.0) [0.0|1] ""  BCM1
 SG_ ESP_Eingriff : 61|1@1+ (1.0,0.0) [0.0|1] ""  BCM1
 SG_ ESP_ASP : 62|1@1+ (1.0,0.0) [0.0|1] ""  BCM1
 SG_ ESC_Neutralschaltung : 63|1@1+ (1.0,0.0) [0.0|1] ""  Vector__XXX

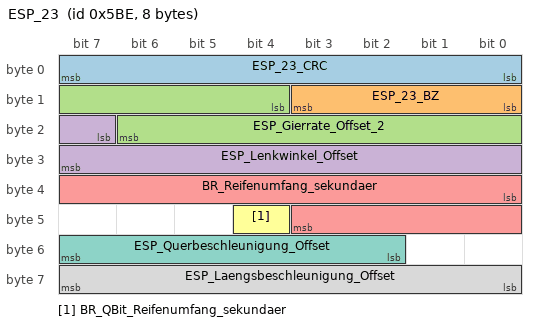
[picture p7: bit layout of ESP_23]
BO_ 1470 ESP_23: 8 Gateway
 SG_ ESP_23_CRC : 0|8@1+ (1,0) [0|255] ""  Vector__XXX
 SG_ ESP_23_BZ : 8|4@1+ (1,0) [0|15] ""  Vector__XXX
 SG_ ESP_Gierrate_Offset_2 : 12|11@1+ (0.01,-10.23) [-10.23|10.22] "Unit_DegreOfArcPerSecon"  VAS_L,VAS_R
 SG_ ESP_Lenkwinkel_Offset : 23|9@1+ (0.1,-25.5) [-25.5|25.4] "Unit_DegreOfArc"  Vector__XXX
 SG_ BR_Reifenumfang_sekundaer : 32|12@1+ (1,0) [0|4095] "Unit_MilliMeter"  Vector__XXX
 SG_ BR_QBit_Reifenumfang_sekundaer : 44|1@1+ (1.0,0.0) [0.0|1] ""  Vector__XXX
 SG_ ESP_Querbeschleunigung_Offset : 50|6@1+ (0.01,-0.3) [-0.30|0.31] "Unit_ForceOfGravi"  Vector__XXX
 SG_ ESP_Laengsbeschleunigung_Offset : 56|8@1+ (0.03125,-3.9375) [-3.93750|3.93750] "Unit_MeterPerSeconSquar"  Vector__XXX

BO_ 508 ESP_32: 8 Gateway
 SG_ ESP_32_CRC : 0|8@1+ (1,0) [0|255] ""  Vector__XXX
 SG_ ESP_32_BZ : 8|4@1+ (1,0) [0|15] ""  Vector__XXX
 SG_ ESP_Status_Bremsentemp_02 : 12|2@1+ (1.0,0.0) [0.0|3] ""  Vector__XXX
 SG_ ESP_Aggregataktivitaet : 14|1@1+ (1.0,0.0) [0.0|1] ""  Vector__XXX
 SG_ ESP_Stillstandsflag : 15|1@1+ (1.0,0.0) [0.0|1] ""  BCM1
 SG_ ESC_MBK_Meldungen : 16|2@1+ (1.0,0.0) [0.0|3] ""  Vector__XXX
 SG_ ESP_EDS_Anzeige : 32|3@1+ (1.0,0.0) [0.0|7] ""  Vector__XXX
 SG_ RLE_Anzeigen : 35|3@1+ (1.0,0.0) [0.0|7] ""  Vector__XXX
 SG_ ESP_Wiederstart_Anz_Std : 38|1@1+ (1.0,0.0) [0.0|1] ""  Vector__XXX
 SG_ ESC_Anforderung_Airbrake : 39|1@1+ (1.0,0.0) [0.0|1] ""  Vector__XXX
 SG_ ESC_FBA_Meldungen : 40|2@1+ (1.0,0.0) [0.0|3] ""  Vector__XXX
 SG_ ESP_Rollover_Status_dyn : 42|2@1+ (1.0,0.0) [0.0|3] ""  Vector__XXX
 SG_ ESP_Rollover_Status_stat : 44|2@1+ (1.0,0.0) [0.0|3] ""  Vector__XXX
 SG_ ESP_AVH_LED : 46|3@1+ (1.0,0.0) [0.0|7] ""  BCM1
 SG_ ESP_HDC_LED : 49|3@1+ (1.0,0.0) [0.0|7] ""  BCM1
 SG_ ESP_Off_LED : 52|3@1+ (1.0,0.0) [0.0|7] ""  BCM1
 SG_ ESP_Notbremsanzeige : 55|1@1+ (1.0,0.0) [0.0|1] ""  Vector__XXX
 SG_ ESC_Motorstartverzoegerung : 56|1@1+ (1.0,0.0) [0.0|1] ""  Vector__XXX
 SG_ ESP_Offroad_Lampe : 57|1@1+ (1.0,0.0) [0.0|1] ""  Vector__XXX
 SG_ ESP_HDC_Textanzeigen : 58|5@1+ (1.0,0.0) [0.0|31] ""  Vector__XXX
 SG_ ESP_HOLD_verf : 63|1@1+ (1.0,0.0) [0.0|1] ""  Vector__XXX

BO_TX_BU_ 2617128449 :BCM1,Klima_MSB;
BO_TX_BU_ 2617127424 :BCM1,Klima_MSB;
BO_TX_BU_ 2617127679 :BCM1,Klima_MSB;
BO_TX_BU_ 2550011686 :BCM1,Klima_MSB;
BO_TX_BU_ 2550011419 :BCM1,Klima_MSB;
BO_TX_BU_ 2550011649 :BCM1,Klima_MSB;
CM_ BO_ 870 "Nur die Kombination des statischen und toggelnden Signals ergibt den Blinktakt für die Hell & Dunkelphase";
CM_ BO_ 868 "Botschaft wird vom BCM1 gesendet, wenn BCM2 ausfällt (Fail-Safe) und die Funktion 'Blinken' aktiv ist
";
CM_ BO_ 901 "ab MQB ohne CHK und mit geänderter Sendeart";
CM_ BO_ 902 "ab MQB 7.2.1";
CM_ BO_ 2549880614 "LIN Flashen AAU (DK2F)";
CM_ BO_ 2550011686 "LIN Flashen AAU (DK2F)";
CM_ BO_ 2549880393 "LIN Flashen EVLS (DK2F)";
CM_ BO_ 2550011465 "LIN Flashen EVLS (DK2F)";
CM_ BO_ 2549880347 "LIN Flashen Blower (DK2F)";
CM_ BO_ 2550011419 "LIN Flashen Blower (DK2F)";
CM_ BO_ 2549880340 "Diagnosezugriff & Flashen Leistungsmodul gleitende Leuchtweite";
CM_ BO_ 2549880341 "Diagnosezugriff Leistungsmodul gleitende Leuchtweite";
CM_ BO_ 2549880577 "LIN Flashen KBF (DK2F)";
CM_ BO_ 2550011649 "LIN Flashen KBF (DK2F)";
CM_ BO_ 2549880639 "LIN Flashen KPV (DK2F)";
CM_ BO_ 2550011711 "LIN Flashen KBF (DK2F)";
CM_ BO_ 2549880330 "Diagnosezugriff Leistungsmodul LED";
CM_ BO_ 2549880331 "Diagnosezugriff Leistungsmodul LED";
CM_ BO_ 2549880633 "LIN Flashen LIM2 (DK2F)";
CM_ BO_ 2550011705 "LIN Flashen LIM2 (DK2F)";
CM_ BO_ 2549880350 "LIN Flashen LIM (DK2F)";
CM_ BO_ 2550011422 "LIN Flashen LIM (DK2F)";
CM_ BO_ 2549880427 "Diagnosezugriff Leistungsmodul Matrix Beam";
CM_ BO_ 2549880428 "Diagnosezugriff Leistungsmodul Matrix Beam";
CM_ BO_ 2549880321 "LIN Flashen WWS (DK2F)";
CM_ BO_ 2550011393 "LIN Flashen WWS (DK2F)";
CM_ BO_ 1520 "ab MQB nach abgestimmten FLH Dimmung";
CM_ BO_ 1603 "ab MQB mit 8 Byte";
CM_ BO_ 260 "ab MQB mit CRC-8";
CM_ BO_ 259 "MLBevo - CRC-Absicherung";
CM_ BO_ 418 "MLBevo verlangsamte 100ms-Botschaft";
CM_ BO_ 253 "Neue Momente im MQB
Struktur ab MQB mit CRC8 entstanden aus ESP_01";
CM_ BO_ 1470 "MSS (AU724/5, LBxxx) Botschaft zur Offsetkompentation";
CM_ BO_ 508 "CAN-Botschaft";

CM_ SG_ 1432 BCM1_eSound_Taster "Das Signal beschreibt den Zustand der eSound Taste, die im MLBevo vom BCM1 eingelesen wird
0 = Taste nicht betätigt
1 = Taste entprellt betätigt
2 = Init oder Taste nicht verbaut
3 = Fehler";
CM_ SG_ 1432 BCM1_NR_Ride_Height_Down_Taster "Tastersignal zum Absenken des Fahrzeugs bei höhenverstellbaren Fahrzeugen (Taster/Bedieneinheit an Schalterleiste 2  BCM1)
";
CM_ SG_ 1432 BCM1_NR_Ride_Height_Up_Taster "Tastersignal zum Anheben des Fahrzeugs bei höhenverstellbaren Fahrzeugen (Taster/Bedieneinheit an Schalterleiste 2  BCM1";
CM_ SG_ 1432 BCM_BFS_Fernsteuerung_aktiv "Fernsteuerung BFS aktiv";
CM_ SG_ 1432 BCM_BFS_Massage_Taster "Ansteuerungs-Signalisierung der Pneumatik-Funktionen";
CM_ SG_ 1432 BCM_BFS_Multif_Taster "Ansteuerungs-Signalisierung der Pneumatik-Funktionen";
CM_ SG_ 1432 BCM_BFS_Pneumatik_Verstellung "Ansteuerungs-Signalisierung der Pneumatik-Funktionen";
CM_ SG_ 1432 BCM_BFS_Programmwippe "Ansteuerungs-Signalisierung der Pneumatik-Funktionen";
CM_ SG_ 1432 BCM_FS_Massage_Taster "Ansteuerungs-Signalisierung der Pneumatik-Funktionen";
CM_ SG_ 1432 BCM_FS_Multif_Taster "Ansteuerungs-Signalisierung der Pneumatik-Funktionen";
CM_ SG_ 1432 BCM_FS_Pneumatik_Verstellung "Ansteuerungs-Signalisierung der Pneumatik-Funktionen";
CM_ SG_ 1432 BCM_FS_Programmwippe "Ansteuerungs-Signalisierung der Pneumatik-Funktionen";
CM_ SG_ 1432 BCM_Soundklappe_Taster "Status Soundklappe Taste";
CM_ SG_ 1432 E_Sound_LED_Status "Das Signal beschreibt den Zustand der eSound LED, die im MLBevo vom BCM1 oder LIN Schalterleiste (BCM1 Slave) angesteuert wird.";
CM_ SG_ 1432 LIM_S_Rollo_hi "Schalterfeld LIM für Sonnenrolle Schiebedach hinten";
CM_ SG_ 1432 LIM_S_Rollo_vo "Schalterfeld LIM für Sonnenrolle Schiebedach vorne";
CM_ SG_ 1432 LIM_S_SAD_hi "Schalterfeld LIM für SAD hinten";
CM_ SG_ 1432 LIM_S_SAD_Vo "Schalterfeld LIM für SAD vorne";
CM_ SG_ 1432 Pilot_Taster "Das Signal beschreibt den Zustand der Pilot Taste, die im MLBevo vom BCM1 eingelesen wird
0 = Taste nicht betätigt
1 = Taste entprellt betätigt
2 = Init oder Taste nicht verbaut
3 = Fehler";

CM_ SG_ 1431 BED_Rollo_vo "Schalterfeld MIKO für Sonnenrollo Schiebedach vorne";
CM_ SG_ 1431 BED_SAD_vo "Bedienschalter für Schiebe / Ausstelldach vorne";
CM_ SG_ 1431 BED_Taster_Fahrwerk "Beschreibt den Fahrwerkstaster";
CM_ SG_ 1431 BED_Taster_Lift "Betätigungsstatus der Lift - Taste";
CM_ SG_ 1431 BED_Taster_VD_Oeffnen "Signal des Verdecktasters zum Oeffnen des Verdecks";
CM_ SG_ 1431 BED_Taster_VD_Schliessen "Signal des Verdecktasters zum Schliessen des Verdecks";
CM_ SG_ 1431 BED_Taster_Windschott "Bedientaster zum Aufstellen und Ablegen des Windschott";
CM_ SG_ 1431 SoSe_SunInt_2D_Li_Dash "Sonnenintensität links (2D Sensor) Dashboard";
CM_ SG_ 1431 SoSe_SunInt_2D_Re_Dash "Sonnenintensität rechts (2D Sensor) Dashboard";

CM_ SG_ 870 Blinken_li_Fzg_Takt "Fzg-Takt Blinker links

";
CM_ SG_ 870 Blinken_li_Kombi_Takt "Kombi-Takt Blinker links

";
CM_ SG_ 870 Blinken_re_Fzg_Takt "Fzg-Takt Blinker rechts

";
CM_ SG_ 870 Blinken_re_Kombi_Takt "Kombi-Takt Blinker rechts

";
CM_ SG_ 870 BM_Autobahn "Status Autobahnblinken
";
CM_ SG_ 870 BM_Crash "Status Crashblinken
";
CM_ SG_ 870 BM_DWA_Alarm "Status DWA-Alarmblinken
";
CM_ SG_ 870 BM_DWA_ein "Status Quittierungsblinken DWA";
CM_ SG_ 870 BM_GDO "Blinken bei UGDO anlernen

";
CM_ SG_ 870 BM_HD_Oeffnung_angelernt "Das HDSG fordert über das CAN Signal HDSG_01.HD_Rueckmeld_prog eine Blinkerquittierung beim BCM2 an.
Wenn die Geschwindigkeit kleiner einer vorgegebenen Schwelle (default 2km/h) ist wird das Signal BM_HD_Öffnung_angelernt versendet und die Blinkerquittie";
CM_ SG_ 870 BM_links "Richtungsblinken links

";
CM_ SG_ 870 BM_NBA_n_codiert_n_aktiv "Notbremsanzeige nicht codiert/nicht aktiv (Fehler)";
CM_ SG_ 870 BM_NBA_Status "Notbremsanzeige Status nicht aktiv / BRL Dunkelphase / BRL Hellphase";
CM_ SG_ 870 BM_Not_Bremsung "Notbremsblinken

";
CM_ SG_ 870 BM_Panik "Panikblinken
";
CM_ SG_ 870 BM_PiloPa "Quittierungsblinken bei pilotierten Parkvorgängen";
CM_ SG_ 870 BM_Recas "Blinkermodus RECAS  (RearEndCollisionAlertSignal)";
CM_ SG_ 870 BM_rechts "Richtungsblinken rechts

";
CM_ SG_ 870 BM_Rollenmodus_Blinken "Das Signal wird statisch gesetzt, wenn die Blinkerart Rollenmodus_Blinken aktiv ist.";
CM_ SG_ 870 BM_Taxi_Notalarm "Blinken bei Taxi-Not-Alarm

";
CM_ SG_ 870 BM_Telematik "Telematikblinken
";
CM_ SG_ 870 BM_Telematik_Abbruchgrund "Gibt bei erwaretem aber ausbleibendem Flankenanstieg der BM_Telematik an wieso die Ausführung verhindert wurde. Bei Flankenabfall der BM_Telematik wird angegeben wieso die Ausführung beendet wurde.

Bei nicht bereitem Sender soll 'init' gesendet werden,";
CM_ SG_ 870 BM_Warnblinken "Warnblinken

";
CM_ SG_ 870 BM_WBT_Beleuchtung "Aktivierung Warnblinktasterfunktionsbeleuchtung
Warnblinktasterfunktionsbeleuchtung soll aktiviert werden (statisch auf 1)";
CM_ SG_ 870 BM_Wischblinken "Blinkermodus Wisch_Blinken";
CM_ SG_ 870 BM_ZV_auf "Blinken bei ZV auf

";
CM_ SG_ 870 BM_ZV_zu "Blinken bei ZV zu

";
CM_ SG_ 870 DWA_Alarmquelle "Signalisiert den Auslösegrund der DWA";

CM_ SG_ 868 NBlinken_li_Fzg_Takt "Notlaufblinken, Fhzg-Takt links

";
CM_ SG_ 868 NBlinken_li_Kombi_Takt "Notlaufblinken, Blinkerkontrolllampe links

";
CM_ SG_ 868 NBlinken_re_Fzg_Takt "Notlaufblinken, Fhzg-Takt rechts
";
CM_ SG_ 868 NBlinken_re_Kombi_Takt "Notlaufblinken, Blinkerkontrolllampe rechts

";

CM_ SG_ 901 CHA_Fahrer_Umschaltung "Die manuelle Umschaltung durch den Fahrer soll signalisiert werden, um zu automatischen Umschaltungen (z.B. Retries) differenzieren zu können.";
CM_ SG_ 901 CHA_Fahrer_Umschaltung_BMA "Die manuelle Umschaltung der Betriebsmodusauswahl durch den Fahrer soll signalisiert werden, um zu automatischen Umschaltungen (z.B. Retries) differenzieren zu können.";
CM_ SG_ 901 CHA_Ziel_FahrPr_ACC "MQB
Anforderung Ziel-Fahrprogramm ACC";
CM_ SG_ 901 CHA_Ziel_FahrPr_AFS "Anforderung Ziel-Fahrprogramm AFS";
CM_ SG_ 901 CHA_Ziel_FahrPr_AGA "Anforderung Ziel-Fahrprogramm AGA/SAK2 (Aussensound)";
CM_ SG_ 901 CHA_Ziel_FahrPr_ALR "Anforderung Ziel-Fahrprogramm Allrad";
CM_ SG_ 901 CHA_Ziel_FahrPr_DR "Anforderung Ziel-Fahrprogramm Dämpfer";
CM_ SG_ 901 CHA_Ziel_FahrPr_EPS "Anforderung Ziel-Fahrprogramm Elektrische Lenkhilfe";
CM_ SG_ 901 CHA_Ziel_FahrPr_ESP "Anforderung Ziel-Fahrprogramm ESP";
CM_ SG_ 901 CHA_Ziel_FahrPr_Freilauf "Anforderung Ziel-Fahrprogramm Funktion Freilauf";
CM_ SG_ 901 CHA_Ziel_FahrPr_GE "Anforderung Ziel-Fahrprogramm Getriebe";
CM_ SG_ 901 CHA_Ziel_FahrPr_MO "Anforderung Ziel-Fahrprogramm Motor";
CM_ SG_ 901 CHA_Ziel_FahrPr_MO_BZS "Anforderung Zielfahrprogramm Motor-Betriebszusände";
CM_ SG_ 901 CHA_Ziel_FahrPr_MO_StSt "Anforderung Ziel-Fahrprogramm Funktion Motor Start-Stopp";
CM_ SG_ 901 CHA_Ziel_FahrPr_PreCrash "Anforderung Ziel-Fahrprogramm VAQ";
CM_ SG_ 901 CHA_Ziel_FahrPr_SAK "Anforderung Ziel-Fahrprogramm Soundaktuator";
CM_ SG_ 901 CHA_Ziel_FahrPr_VAQ "Anforderung Ziel-Fahrprogramm VAQ";

CM_ SG_ 902 CHA_Charge_LED "Ansteuerung der LED am Charge-Taster durch Charisma im PHEV";
CM_ SG_ 902 CHA_Current_Mode "Aktuell eingestelltes Charisma Fahrprogramm";
CM_ SG_ 902 CHA_Drehschalter_Istmodus "Aktuell eingestellte Vorgabe für Schalterposition des CHA-Drehschalters";
CM_ SG_ 902 CHA_Eco_Charisma_LED "Ansteuerung der Funktions-LED der ECO alias Bluekey Taste bzw. Charisma-Taste.
Der Master der Fahrmodus-Funktion soll die Funktionsleuchte ansteuern, in der MQB Architektur ist der Master im Gateway untergebracht.";
CM_ SG_ 902 CHA_EV_LED "Ansteuerung der LED am EV-Taster durch Charisma im PHEV";
CM_ SG_ 902 CHA_Fahrer_Umschaltung "Die manuelle Umschaltung durch den Fahrer soll signalisiert werden, um zu automatischen Umschaltungen (z.B. Retries) differenzieren zu können.";
CM_ SG_ 902 CHA_Kombi_Texte "Anzeige des aktuellen Charisma-Fahrprofiles im Kombi.
Die Texte werden HUT-Spezifisch in einem Schnittstellen-LAH definiert.";
CM_ SG_ 902 CHA_Kombi_Texte_02 "Anzeige von Hinweistexten bzgl. Charismaumschaltungen im Kombi.
Die Texte werden HUT-Spezifisch in einem Schnittstellen-LAH definiert.";
CM_ SG_ 902 CHA_Offroad_LED "Ansteuerung der Offroad-LED";
CM_ SG_ 902 CHA_Ziel_FahrPr_03_01 "reserviert für Anforderung Ziel-Fahrprogramm";
CM_ SG_ 902 CHA_Ziel_FahrPr_03_02 "reserviert für Anforderung Ziel-Fahrprogramm";
CM_ SG_ 902 CHA_Ziel_FahrPr_AMB "Anforderung Ziel-Fahrprogramm Ambientelichtmodul";
CM_ SG_ 902 CHA_Ziel_FahrPr_HSP "Anforderung Ziel-Fahrprogramm Heckspoiler";
CM_ SG_ 902 CHA_Ziel_FahrPr_IVB "Anforderung Ziel-Fahrprogramm IVB";
CM_ SG_ 902 CHA_Ziel_FahrPr_KL "Anforderung Ziel-Fahrprogramm Klima";
CM_ SG_ 902 CHA_Ziel_FahrPr_RWB "Anforderung Zielfahrprogramm Reichweitenberechnung (RWB)";

CM_ SG_ 1000 CHA_Fahrer_Umschaltung "Die manuelle Umschaltung durch den Fahrer soll signalisiert werden, um zu automatischen Umschaltungen (z.B. Retries) differenzieren zu können.";
CM_ SG_ 1000 CHA_Ziel_FahrPr_AFR "Anforderung Ziel-Fahrprogramm Aktive Fahrwerk Regelung (eAWS und eABC)";
CM_ SG_ 1000 CHA_Ziel_FahrPr_AV "Anforderung Ziel-Fahrprogramm AreaView2";
CM_ SG_ 1000 CHA_Ziel_FahrPr_EAR "Anforderung Zielfahrprogramm EAR (EFP Allrad Regelsysteme)";
CM_ SG_ 1000 CHA_Ziel_FahrPr_EBKV "Signal zur Ansteuerung des EBKV durch den Charisma-Koordinator";
CM_ SG_ 1000 CHA_Ziel_FahrPr_FCWO "Anforderung Ziel-Fahrprogramm FCWO (Objektwarnung)";
CM_ SG_ 1000 CHA_Ziel_FahrPr_FCWP "Anforderung Ziel-Fahrprogramm FCWP (Personenwarnung)";
CM_ SG_ 1000 CHA_Ziel_FahrPr_HAL "Anforderung Zielfahrprogramm Hinterachslenkung (HAL)";
CM_ SG_ 1000 CHA_Ziel_FahrPr_HDC "Anforderung Ziel-Fahrprogramm Hill Descent Control";
CM_ SG_ 1000 CHA_Ziel_FahrPr_IL "Anforderung Ziel-Fahrprogramm Integrallenkung";
CM_ SG_ 1000 CHA_Ziel_FahrPr_MXB "Anforderung Ziel-Fahrprogramm MXB";
CM_ SG_ 1000 CHA_Ziel_FahrPr_NR "Anforderung Ziel-Fahrprogramm Niveaureglierung";
CM_ SG_ 1000 CHA_Ziel_FahrPr_QS "Anforderung Ziel-Fahrprogramm geregelte Hinterachsquersperre";
CM_ SG_ 1000 CHA_Ziel_FahrPr_SCU "Anforderung Ziel-Fahrprogramm SCU";
CM_ SG_ 1000 CHA_Ziel_FahrPr_WarnBrems "Anforderung Ziel-Fahrprogramm für Funktion Warn- und/oder Notbremsfunktion";

CM_ SG_ 1022 CHA_Current_Mode_BMA "Aktuell eingestellter Charisma Betriebsmodus";
CM_ SG_ 1022 CHA_Fahrer_Umschaltung "Die manuelle Umschaltung durch den Fahrer soll signalisiert werden, um zu automatischen Umschaltungen (z.B. Retries) differenzieren zu können.";
CM_ SG_ 1022 CHA_Fahrer_Umschaltung_BMA "Die manuelle Umschaltung der Betriebsmodusauswahl durch den Fahrer soll signalisiert werden, um zu automatischen Umschaltungen (z.B. Retries) differenzieren zu können.";
CM_ SG_ 1022 CHA_Ziel_FahrPr_AGK "Signal zur Ansteuerung des Teilnehmers Abgasklappen durch den Charisma-Koordinator über das Motor-SG";
CM_ SG_ 1022 CHA_Ziel_FahrPr_BMS "Anforderung Ziel-Fahrprogramm BMS (nähere Spezifikation siehe Charisma-LH PAG)";
CM_ SG_ 1022 CHA_Ziel_FahrPr_EDS "Anforderung Ziel-Fahrprogramm Elektronische Differentialsperre";
CM_ SG_ 1022 CHA_Ziel_FahrPr_HHC "Anforderung Ziel-Fahrprogramm Hill Hold Control";
CM_ SG_ 1022 CHA_Ziel_FahrPr_MO_Freilauf "Anforderung Ziel-Fahrprogramm Funktion Freilauf Motor aus";
CM_ SG_ 1022 CHA_Ziel_FahrPr_PACC "Anforderung Ziel-Fahrprogramm InnoDrive (PACCh)";
CM_ SG_ 1022 CHA_Ziel_FahrPr_PDC "Signal zur Ansteuerung des PDC/PLA durch den Charisma-Koordinator";

CM_ SG_ 2549880614 DIA_AAU_Req_Data "Diagnosezugriff & Flashen ActiveAromaUnit AAU";

CM_ SG_ 2550011686 DIA_AAU_Resp_Data "Diagnosezugriff & Flashen ActiveAromaUnit AAU";

CM_ SG_ 2549880393 DIA_EVLS_Req_Data "Diagnosezugriff & Flashen Elektronische Verstellung Lenksäule";

CM_ SG_ 2550011465 DIA_EVLS_Resp_Data "Diagnosezugriff & Flashen Elektronische Verstellung Lenksäule";

CM_ SG_ 2549880347 DIA_Geblaese_Req_Data "Diagnosezugriff & Flashen Gebläseregler";

CM_ SG_ 2550011419 DIA_Geblaese_Resp_Data "Diagnosezugriff & Flashen Gebläseregler";

CM_ SG_ 2549880340 DIA_gLW_LM_L_Req_Data "Diagnosezugriff & Flashen Leistungsmodule für gleitende Leuchtweite ";

CM_ SG_ 2550011412 DIA_gLW_LM_L_Resp_Data "Diagnosezugriff & Flashen Leistungsmodule für gleitende Leuchtweite ";

CM_ SG_ 2549880341 DIA_gLW_LM_R_Req_Data "Diagnosezugriff & Flashen Leistungsmodule für gleitende Leuchtweite ";

CM_ SG_ 2550011413 DIA_gLW_LM_R_Resp_Data "Diagnosezugriff & Flashen Leistungsmodule für gleitende Leuchtweite ";

CM_ SG_ 2549880577 DIA_KBF_Req_Data "Diagnosezugriff & Flashen Klimabedienung Fond";

CM_ SG_ 2550011649 DIA_KBF_Resp_Data "Diagnosezugriff & Flashen Klimabedienung Fond";

CM_ SG_ 2549880639 DIA_KPV_Req_Data "Diagnosezugriff & Flashen Klimapanel vorne";

CM_ SG_ 2550011711 DIA_KPV_Resp_Data "Diagnosezugriff & Flashen Klimabedienteil vorne";

CM_ SG_ 2549880330 DIA_LED_LM_L_Req_Data "Diagnosezugriff & Flashen LED Leistungsmodule";

CM_ SG_ 2550011402 DIA_LED_LM_L_Resp_Data "Diagnosezugriff & Flashen LED Leistungsmodule";

CM_ SG_ 2549880331 DIA_LED_LM_R_Req_Data "Diagnosezugriff & Flashen LED Leistungsmodule";

CM_ SG_ 2550011403 DIA_LED_LM_R_Resp_Data "Diagnosezugriff & Flashen LED Leistungsmodule";

CM_ SG_ 2549880633 DIA_LIM2_Req_Data "Diagnosezugriff & Flashen LIM2";

CM_ SG_ 2550011705 DIA_LIM2_Resp_Data "Diagnosezugriff & Flashen LIM2";

CM_ SG_ 2549880350 DIA_LIM_Req_Data "Diagnosezugriff & Flashen LIM";

CM_ SG_ 2550011422 DIA_LIM_Resp_Data "Diagnosezugriff & Flashen LIM";

CM_ SG_ 2549880427 DIA_MXB_LM_L_Req_Data "Diagnosezugriff & Flashen Matrixbeam Leistungsmodule";

CM_ SG_ 2550011499 DIA_MXB_LM_L_Resp_Data "Diagnosezugriff & Flashen Matrixbeam Leistungsmodule";

CM_ SG_ 2549880428 DIA_MXB_LM_R_Req_Data "Diagnosezugriff & Flashen Matrixbeam Leistungsmodule";

CM_ SG_ 2550011500 DIA_MXB_LM_R_Resp_Data "Diagnosezugriff & Flashen Matrixbeam Leistungsmodule";

CM_ SG_ 2549880612 DIA_SWP_Req_Data "Diagnosezugriff & Flashen Automatic Transmission Fluid-Pumpe";

CM_ SG_ 2550011684 DIA_SWP_Resp_Data "Diagnosezugriff & Flashen Automatic Transmission Fluid-Pumpe";

CM_ SG_ 2549880324 DIA_UGDO_S_Req_Data "Diagnosezugriff & Flashen Garagentoröffner (Sender)";

CM_ SG_ 2550011396 DIA_UGDO_S_Resp_Data "Diagnosezugriff & Flashen Garagentoröffner (Sender)";

CM_ SG_ 2549880321 DIA_WWS_Req_Data "Diagnosezugriff & Flashen Wischwinkelsteuerung";

CM_ SG_ 2550011393 DIA_WWS_Resp_Data "Diagnosezugriff & Flashen Wischwinkelsteuerung";

CM_ SG_ 1714 DGN_Verlernzaehler "wrap around 254 --> 0";
CM_ SG_ 1714 KBI_Kilometerstand "Fehler wird ausgegeben, falls Kilometerstand nicht restaurierbar
";
CM_ SG_ 1714 UH_Minute "0x3C- 0x3f = Werte ungültig";
CM_ SG_ 1714 UH_Monat "0x0D, 0xF =  Werte ungültig
0x0E = reserviert (nur VW)";
CM_ SG_ 1714 UH_Sekunde "0x3C- 0x3f = Werte ungültig";
CM_ SG_ 1714 UH_Stunde "0x18 - 0x1F = Werte ungültig";
CM_ SG_ 1714 UH_Tag "0x0: reserviert bei VW";
CM_ SG_ 1714 Uhrzeit_01_alt "
";

CM_ SG_ 1520 BCM1_Stellgroesse_Kl_58s "Rohwert Dimmpoti";
CM_ SG_ 1520 DI_Display_Nachtdesign "Für Displays sind oft  automatische Umschaltungen von Tag-/Nachtdesign vorgesehen.
Es gibt jedoch Zustände, an denen auch tagsüber das Abblendlicht eingeschaltet ist.
z.B. Dauerfahrlicht, Geschwindigkeitsabhängiges 'Licht-An-Bei-Autobahn', 'Regenlicht',";
CM_ SG_ 1520 DI_Fotosensor "Helligkeitswert Fotosensor
Für die Dimmung relevanter Wert zur Sensierung der Umgebungshelligkeit
Im Detail beschrieben im 'Funktionslastenheft Dimmung MQB'.";
CM_ SG_ 1520 DI_KL_58xd "Klemme 58xd Display- und Funktionsbeleuchtung
Mit der Klemme 58xd wird die Helligkeit der Display- und der Funktionsbeleuchtungen der Schalter gesteuert.
Im Detail beschrieben im 'Funktionslastenheft Dimmung MQB'.";
CM_ SG_ 1520 DI_KL_58xs "Suchbeleuchtung Schalter
EIN-AUS-Schaltalgorithmus der allgemeinen Schaltersuchbeleuchtung. 
Im Detail beschrieben im 'Funktionslastenheft Dimmung MQB'.
";
CM_ SG_ 1520 DI_KL_58xt "Timergesteuerte Suchbeleuchtung
Der EIN-AUS-Schaltalgorithmus für die vor- und nachlaufende Schaltersuchbeleuchtungen beim Ein- & Aussteigen; z.B.: Start/Stop-Taster.
Im Detail beschrieben im 'Funktionslastenheft Dimmung MQB'.";

CM_ SG_ 420 EA_01_BZ "EA Botschaftszähler
Botschaft asynchron geroutet. Zählerwert kann springen.";
CM_ SG_ 420 EA_01_CRC "Ab MQB und MLBevo:
'Berechnung siehe Lastenheft 'End-to-End Kommunikationsabsicherung''";
CM_ SG_ 420 EA_Anforderung_HMS "Emergency Assist Anforderung an HMS";
CM_ SG_ 420 EA_eCall_Anf "Emergency Assist Anforderung eCall";
CM_ SG_ 420 EA_Funktionsstatus "Emergency Assist Funktionsstatus";
CM_ SG_ 420 EA_Gurtstraffer_Anf "Emergency Assist Anforderung reversibler Gurtstraffer";
CM_ SG_ 420 EA_Parken_beibehalten_HMS "Anforderung um automatisches lösen der Parkbremse zu verhindern";
CM_ SG_ 420 EA_Sollbeschleunigung "Emergency Assist Beschleunigungsanforderung";
CM_ SG_ 420 EA_Warnruckprofil "Emergency Assist Anforderung an ESP, welcher Ruck verwendet werden soll.";

CM_ SG_ 496 ACF_Lampe_Hands_Off "Anzeige, ob der Fahrer die Hände am Lenkrad hat.";
CM_ SG_ 496 EA_02_BZ "Botschaftszähler
Botschaft asynchron geroutet. Zählerwert kann springen.";
CM_ SG_ 496 EA_02_CRC "Für MLB:
'Berechnung siehe Lastenheft 'Kommunikationsabsicherung für Flexray und CAN''

Ab MQB und MLBevo:
'Berechnung siehe Lastenheft 'End-to-End Kommunikationsabsicherung'

Endwerte siehe Begleitdokument 'S-PDU Kennungsfolge'";
CM_ SG_ 496 EA_Blinken "Zusammenfassung des Signals EA_Richtungsblinken und EA_Warnblinken";
CM_ SG_ 496 EA_Bremslichtblinken "Die Funktion Emergency Alert fordert ein Blinken der Bremsleuchten an.";
CM_ SG_ 496 EA_Infotainment_Anf "Emergency Assist Anforderung Absenkung Infotainment-Funktionen";
CM_ SG_ 496 EA_Innenraumlicht_Anf "Anforderung Innenraumbeleuchtung durch den Emergency Assist";
CM_ SG_ 496 EA_Texte "Anzeige der EA Texte";
CM_ SG_ 496 EA_Tueren_Anf "Emergency Assist Anforderung Türen entriegeln";
CM_ SG_ 496 STP_Primaeranz "Primäranzeige des Staupiloten";
CM_ SG_ 496 zFAS_Warnblinken "Anforderung Warnblinken durch zFAS Funktionen.";

CM_ SG_ 2527679980 bCall_active "1: Breakdown call is active
0: BreakdownCall is inactive";
CM_ SG_ 2527679980 eCall_Funktionsstatus "HMI-Aufruf im Kombi (Broadcast)
Fehlerfälle die im Kombi angezeigt werden können";
CM_ SG_ 2527679980 eCall_Funktionsstatus_02 "Erweiterung des Funktionsstatus für andere Funktionen
ACN aktiv, MEC aktiv
MEC = manual emergency call = maueller Notruf
ACN = automatic emergency call = automatischer Notruf";
CM_ SG_ 2527679980 eCall_Statuslicht_Farbe1 "Steuerung Statuslicht (Farbe1) für Funktionsrückmeldungen Emergency Call / SOS Hilferuf,
z.B. LED-Anzeige im Dachmodul.";
CM_ SG_ 2527679980 eCall_Statuslicht_Farbe2 "Steuerung Statuslicht (Farbe2) für Funktionsrückmeldungen Emergency Call / SOS Hilferuf,
z.B. LED-Anzeige im Dachmodul.";
CM_ SG_ 2527679980 eCall_Subscription "Anzeige 'Service Unsubscribed' im Kombi - Aktualisierte Namensgebung";

CM_ SG_ 1603 KBI_Einheit_Datum "Anzeigevariante des Datums";
CM_ SG_ 1603 KBI_Einheit_Druck "Einheit des Druckes";
CM_ SG_ 1603 KBI_Einheit_Masse "Einheit der Masse (Verwendung z.B. ASTA)";
CM_ SG_ 1603 KBI_Einheit_Sprache "Siehe BAP-Datenfestlegung UnitMaster";
CM_ SG_ 1603 KBI_Einheit_Streckenanz "Einheit der Streckenanzeige";
CM_ SG_ 1603 KBI_Einheit_Temp "Einheit der Temperatur";
CM_ SG_ 1603 KBI_Einheit_Uhrzeit "Anzeigevariante der Uhrzeit";
CM_ SG_ 1603 KBI_Einheit_Verbrauch "Einheit der Verbrauchs";
CM_ SG_ 1603 KBI_Einheit_Verbrauch_elektr "Einheit elektrischer Verbrauch";
CM_ SG_ 1603 KBI_Einheit_Verbrauch_Gas "Unterscheidung zwischen M3/h und kg/h für Komfortverbrauchsberechnung.";
CM_ SG_ 1603 KBI_Einheit_Volumen "Einheit des Volumens";
CM_ SG_ 1603 KBI_MFA_v_Einheit_02 "Einheit der Geschwindigkeit, die vom Fahrer im Car-Menü gewählt wurde. Veränderliche Grösse, im Gegensatz zur Einheit des Tachokranzes.

Redundant in der Einheiten_01 Botschaft definiert, um Konsistenz zur BAP-Festlegung zu haben.";

CM_ SG_ 260 EPB_01_BZ "Botschaft asynchron geroutet. Zählerwert kann springen.";
CM_ SG_ 260 EPB_01_CRC "Für MLB:
'Berechnung siehe Lastenheft 'Kommunikationsabsicherung für FlexRay und CAN''

Ab MQB und MLBevo:
'Berechnung siehe Lastenheft 'End-to-End Kommunikationsabsicherung''

Endwerte siehe Begleitdokument 'S-PDU Kennungsfolgen'";
CM_ SG_ 260 EPB_DAA_Randbed_erf "Die Randbedingungen zum automatischen Öffnen der EPB (Funktion DAA) sind erfüllt und ein Betätigen des Fahrpedals führt zum Öffnen der EPB.";
CM_ SG_ 260 EPB_Fehlerstatus_02 "Anpassung der Texte an die  aktuellen Zustände für weitergehende Funktionen (Stillstandsmanager)";
CM_ SG_ 260 EPB_Freig_Verzoeg_Anf "Verzögerungsanforderung	";
CM_ SG_ 260 EPB_Pedalweg_Kuppl "Signal entspricht Tastverhältnis des PWM. Gesamtweg Kupplungspedal 10% bis 90%, damit zu erwartende Werte 25 bis 225. 25 bei Kupplungspedal nicht getreten, 225 bei Kupplungspedal voll durchgetreten.
2% Toleranz wird im Wertebereich ermöglicht (8%-92%).
";
CM_ SG_ 260 EPB_Schalterposition "Spiegelt die Schalterstellung wieder.

0x3 = Schalterfehler ";
CM_ SG_ 260 EPB_Spannkraft "Erzeugte Spannkraft. Bezieht sich auf die Aktuatoren.

MQB: Spannkraftwerte entsprechen nicht den tatsächlichen Spannkräften. Genauere Informationen bitte in der Fachabteilung erfragen! ";
CM_ SG_ 260 EPB_Status_02 "Erweiterung der Zustände um ein genaueres Bild des aktuellen Zustandes zu erhalten für weitergehende Funktionen ( Stillstandsmanager)
";
CM_ SG_ 260 EPB_Verzoeg_Anf "Steuerungsanforderung an andere Systeme (z.B. ESP), um während der Fahrt, durch den Handbremsschalter ausgelöst, zu bremsen (ECD-Funktion)";

CM_ SG_ 259 ESP_03_CRC "Ab MQB und MLBevo:
'Berechnung siehe Lastenheft 'End-to-End Kommunikationsabsicherung''

Endwerte siehe Begleitdokument 'S-PDU Kennungsfolgen'";
CM_ SG_ 259 ESP_HL_FR "Fahrtrichtungserkennung Rad Hinten Links
";
CM_ SG_ 259 ESP_HL_Radgeschw "Radgeschwindigkeit hinten links";
CM_ SG_ 259 ESP_HR_FR "Fahrtrichtungserkennung Rad Hinten Rechts
";
CM_ SG_ 259 ESP_HR_Radgeschw "Radgeschwindigkeit hinten rechts";
CM_ SG_ 259 ESP_VL_FR "Fahrtrichtungserkennung Rad Vorne Links
";
CM_ SG_ 259 ESP_VL_Radgeschw "Radgeschwindigkeit vorne links";
CM_ SG_ 259 ESP_VR_FR "Fahrtrichtungserkennung Rad Vorne Rechts

";
CM_ SG_ 259 ESP_VR_Radgeschw "Radgeschwindigkeit vorne rechts";

CM_ SG_ 914 ESC_cAQP_Trigger "Trigger zur statistischen Auswertung durch die Connected Car Funktion Aquaplaning Praediktion (AQP).

Ansprechpartner: Timo Maise (PAG- EEC2)";
CM_ SG_ 914 ESP_07_CRC "Für MLB:
'Berechnung siehe Lastenheft 'Kommunikationsabsicherung für FlexRay und CAN''

Ab MQB und MLBevo:
'Berechnung siehe Lastenheft 'End-to-End Kommunikationsabsicherung''

Endwerte siehe Begleitdokument 'S-PDU Kennungsfolgen'";
CM_ SG_ 914 ESP_Allrad_Antrieb "Im MQB wird das Signal nicht unterstützt!";
CM_ SG_ 914 ESP_Codierung_ADS "ESP gibt für Empfänger im Fahrzeug aus, ob ADS verbaut/nicht verbaut ist.

Im MQB wird das Signal nicht unterstützt!
";
CM_ SG_ 914 ESP_MKB_ausloesbar "ESP hat Funktion Multi-Kollisions-Bremsung freigeschaltet";
CM_ SG_ 914 ESP_nachtr_Stopp_Anf "Dieses Signal dient dem Motor als Trigger, dass ein nachträglicher Motorstopp eingeleitet werden kann, wenn es die Bedingungen des StSt Koordinators dies zulassen. ";
CM_ SG_ 914 ESP_OBD_Status "Dieses Bit steuert die MIL-Lampe an (Motorsteuergerät reicht diese Info an Kombi weiter).";
CM_ SG_ 914 ESP_Offroad_Modus "Nur VW526: Bei Offroad-Fahrzeugen kann über einen Schalter ein Offroadmodus gewählt werden, dieser wird hier angezeigt. Bei Offroad Plus- Fahrzeugen wird hier der Offroadmodus indirekt durch das Verteilergetriebe vorgegeben (ALR_Offroad = 1) und eingespie";
CM_ SG_ 914 ESP_Qualifizierung_Antriebsart "Signal for Bentley BY83x: ESP_wheel_drive_selector

Bit qualifiziert für neue Projekte (ab D4 ff.) das Signal 'ESP_Quattro_Antrieb', d.h. ist 'ESP_Qualifizierung_Antriebsart'
auf 0x1 gesetzt, ändert sich die bisherige Bedeutung des Signals 'ESP_Quattro";
CM_ SG_ 914 ESP_Rollenmodus_Deaktivieren "Zwang zum Abbruch des Rollenmodus mit anschließender ESP-Vollfunktion.
MQB: Zwang zum Abbruch des Rollenmodus in allen Funktionsteilnehmern (Empfänger) mit anschließender ESP-Vollfunktion (Sender).
Signal wird vom ESP dauerhaft mit gültigen Werten bedat";
CM_ SG_ 914 ESP_RTA_HL "Physikalischer Wertebereich +/-5%. Der Reifentoleranzabgleich bezieht sich auf das linke Vorderrad.

physikalischer Wert = ( (Hex-Wert - 0x7F) / 2048 )*100%

Im MQB wird das Signal nicht unterstützt!";
CM_ SG_ 914 ESP_RTA_HR "Physikalischer Wertebereich +/-5%. Der Reifentoleranzabgleich bezieht sich auf das linke Vorderrad.

physikalischer Wert = ( (Hex-Wert - 0x7F) / 2048 )*100%

Im MQB wird das Signal nicht unterstützt!";
CM_ SG_ 914 ESP_RTA_VR "Physikalischer Wertebereich +/-5%. Der Reifentoleranzabgleich bezieht sich auf das linke Vorderrad.

physikalischer Wert = ( (Hex-Wert - 0x7F) / 2048 )*100%

Im MQB wird das Signal nicht unterstützt!";
CM_ SG_ 914 ESP_Stat_FallBack_eBKV "Das Signal zeigt dem eBKV an, ob seine Rückfallebene im ESP verfügbar ist.";
CM_ SG_ 914 OBD_Fehler_Radsensor_HL "Für Motor-SG (gesetzliche Vorgabe)";
CM_ SG_ 914 OBD_Fehler_Radsensor_HR "Für Motor-SG (gesetzliche Vorgabe)";
CM_ SG_ 914 OBD_Fehler_Radsensor_VL "Für Motor-SG (gesetzliche Vorgabe)";
CM_ SG_ 914 OBD_Fehler_Radsensor_VR "Für Motor-SG (gesetzliche Vorgabe)";

CM_ SG_ 278 ESP_10_BZ "Botschaftszähler

Wird im Projekt D4 und D4Hybrid nicht verwendet!  Wird im D4 PA verwendet";
CM_ SG_ 278 ESP_10_CRC "Für MLB:
'Berechnung siehe Lastenheft 'Kommunikationsabsicherung für FlexRay und CAN''

Ab MQB und MLBevo:
'Berechnung siehe Lastenheft 'End-to-End Kommunikationsabsicherung''

Endwerte siehe Begleitdokument 'S-PDU Kennungsfolgen'

Wird im Projekt";
CM_ SG_ 278 ESP_HL_Fahrtrichtung "Drehrichtung Rad HL

Weiterführende Informationen im Lastenheft spezifiziert und in der entsprechenden Fachabteilung zu erfragen.

Wird im Projekt D4 und D4Hybrid nicht verwendet!  Wird im D4 PA verwendet";
CM_ SG_ 278 ESP_HR_Fahrtrichtung "Drehrichtung Rad HR

Weiterführende Informationen im Lastenheft spezifiziert und in der entsprechenden Fachabteilung zu erfragen.

Wird im Projekt D4 und D4Hybrid nicht verwendet!  Wird im D4 PA verwendet";
CM_ SG_ 278 ESP_QBit_Wegimpuls_HL "Qualifizierungsbit Wegimpulszähler HL

Wird im Projekt D4 und D4Hybrid nicht verwendet!  Wird im D4 PA verwendet";
CM_ SG_ 278 ESP_QBit_Wegimpuls_HR "Qualifizierungsbit Wegimpulszähler HR

Wird im Projekt D4 und D4Hybrid nicht verwendet!  Wird im D4 PA verwendet";
CM_ SG_ 278 ESP_QBit_Wegimpuls_VL "Qualifizierungsbit Wegimpulszähler VL

Wird im Projekt D4 und D4Hybrid nicht verwendet!  Wird im D4 PA verwendet";
CM_ SG_ 278 ESP_QBit_Wegimpuls_VR "Qualifizierungsbit Wegimpulszähler VR

Wird im Projekt D4 und D4Hybrid nicht verwendet!  Wird im D4 PA verwendet";
CM_ SG_ 278 ESP_VL_Fahrtrichtung "Drehrichtung Rad VL

Weiterführende Informationen im Lastenheft spezifiziert und in der entsprechenden Fachabteilung zu erfragen.

Wird im Projekt D4 und D4Hybrid nicht verwendet!  Wird im D4 PA verwendet";
CM_ SG_ 278 ESP_VR_Fahrtrichtung "Drehrichtung Rad VR

Weiterführende Informationen im Lastenheft spezifiziert und in der entsprechenden Fachabteilung zu erfragen.

Wird im Projekt D4 und D4Hybrid nicht verwendet!  Wird im D4 PA verwendet";
CM_ SG_ 278 ESP_Wegimpuls_HL "Wegimpulszähler HL.
Anzahl der Wegimpulse Hinterrad links (steigende und fallende Flanke)
Zähler läuft grundsätzlich vorwärts, auch bei Rückwärtsfahrt.
Nach SG-Reset ist immer, ohne Ausnahme, 1mal der Init Wert 1021 zu senden.

Wird im Projekt D4 und";
CM_ SG_ 278 ESP_Wegimpuls_HR "Wegimpulszähler HR.
Anzahl der Wegimpulse Hinterrad rechts (steigende und fallende Flanke)
Zähler läuft grundsätzlich vorwärts, auch bei Rückwärtsfahrt.
Nach SG-Reset ist immer, ohne Ausnahme, 1mal der Init Wert 1021 zu senden.

Wird im Projekt D4 un";
CM_ SG_ 278 ESP_Wegimpuls_VL "Wegimpulszähler VL.
Anzahl der Wegimpulse Vorderrad links (steigende und fallende Flanke)
Zähler läuft grundsätzlich vorwärts, auch bei Rückwärtsfahrt.
Nach SG-Reset ist immer, ohne Ausnahme, 1mal der Init Wert 1021 zu senden.

Wird im Projekt D4 und";
CM_ SG_ 278 ESP_Wegimpuls_VR "Wegimpulszähler VR.
Anzahl der Wegimpulse Vorderrad rechts (steigende und fallende Flanke)
Zähler läuft grundsätzlich vorwärts, auch bei Rückwärtsfahrt.
Nach SG-Reset ist immer, ohne Ausnahme, 1mal der Init Wert 1021 zu senden.

Wird im Projekt D4 un";

CM_ SG_ 418 ESP_15_BZ "Botschaftszähler
Botschaft asynchron geroutet. Zählerwert kann springen.";
CM_ SG_ 418 ESP_15_CRC "Für MLB:
'Berechnung siehe Lastenheft 'Kommunikationsabsicherung für FlexRay und CAN''

Ab MQB und MLBevo:
'Berechnung siehe Lastenheft 'End-to-End Kommunikationsabsicherung''

Endwerte siehe Begleitdokument 'S-PDU Kennungsfolgen'

Wird im Projekt";
CM_ SG_ 418 ESP_Haltemoment "Zeigt in Abhängigkeit von ESP_Index_Haltemoment das notwendige Summen-Radmoment an (bergab: Bremsmoment; bergauf: Antriebsmoment), das mindestens notwendig ist um das Fahrzeug an der aktuellen Neigung zu halten.";
CM_ SG_ 418 ESP_Index_Haltemoment "Zeigt an, ob das Summen-Radmoment von ESP_Haltemoment ein Bremsmoment (bergab) oder ein Antriebsmoment (bergauf) darstellt.";
CM_ SG_ 418 HMS_aktives_System "Zeigt an, von welchem System die Anforderung gerade umgesetzt wird.";
CM_ SG_ 418 HMS_Anforderung_GE "Fordert vom Getriebe bestimmte Schaltstellungen an.";
CM_ SG_ 418 HMS_Fehlerstatus "Zeigt den Fehlerstatus des Haltemanagementsystems HMS an.
Details zu den Werten 3/4:
3=Systemeinschränkung, Parken EPB oder GSG nicht möglich
4=Systemstörung bzw. Parken EPB und GSG nicht möglich  ";
CM_ SG_ 418 HMS_halten_nicht_verfuegbar "Rueckmeldung HMS-Teilfunktion 'Halten' nicht verfuegbar.";
CM_ SG_ 418 HMS_Konsistenz_ACC "Zeigt an, ob die Kommunikation und die Anforderungen plausibel sind.";
CM_ SG_ 418 HMS_Konsistenz_GE "Zeigt an, ob die Kommunikation und die Anforderungen plausibel sind.";
CM_ SG_ 418 HMS_Konsistenz_HVLM "Zeigt an, ob die Kommunikation und die Anforderungen plausibel sind.";
CM_ SG_ 418 HMS_Konsistenz_IPA "Zeigt an, ob die Kommunikation und die Anforderungen plausibel sind.
";
CM_ SG_ 418 HMS_Konsistenz_MO "Zeigt an, ob die Kommunikation und die Anforderungen plausibel sind.";
CM_ SG_ 418 HMS_Konsistenz_STA "Zeigt an, ob die Kommunikation und die Anforderungen plausibel sind.";
CM_ SG_ 418 HMS_Notstopp_Status "Statusinformation des Notstoppsystems an die beteiligten Systeme.";
CM_ SG_ 418 HMS_P_beibehalten_GE "Fordert das Getriebe auf in Stellung 'P' zu bleiben.";
CM_ SG_ 418 HMS_parken_nicht_verfuegbar "Rueckmeldung HMS-Teilfunktionen 'Parken' nicht verfuegbar.";
CM_ SG_ 418 HMS_Stillstand "Das Signal zeigt, basierend auf den vier ESP-Raddrehzahlinformatioen, gefiltert und/oder entprellt mehrstufig den Fahrzeuggeschwindigkeitszustand an.";
CM_ SG_ 418 HMS_Systemstatus "Zeigt den aktuellen Systemstatus des HMS an.";
CM_ SG_ 418 NL_PRIM_STP_01_Status "Das Primär- Bremsregelsystem übermittelt seinen Systemstatus an zFAS und Sekundär- Bremsregelsystem. 

Der Staupilot ermittelt sich über den Status des Primär-und des Sekundärbremsregelsystems den Gesamtzustand des Notlaufreglers.";
CM_ SG_ 418 VMM_Warnblinken "Über dieses Signal wird ein Warnblinken von Funktionen des VMM (VehicleMotionManagers) angefordert.";
CM_ SG_ 418 VZM_Status "Zeigt die Verfuegbarkeit und den Zustand der VZM Funktionen im ESC an";

CM_ SG_ 253 ABS_Bremsung "Antiblockiersystem, Bit zeigt auch Druckabbau an (z.B. ESP hat zuviel Druck aufgebaut oder ungebremste Regelung auf Bahnübergang)
Weiterführende Informationen im Lastenheft spezifiziert und in der entsprechenden Fachabteilung zu erfragen.";
CM_ SG_ 253 ASR_Anf "MLB: Die Momentenanforderung 'ASR_MSR_Moment_schnell' und 'ASR_Moment_langsam' sind auszuführen
MQB: Die Momentenanforderung 'BR_Eingriffsmoment' ist auszuführen";
CM_ SG_ 253 ASR_Schalteingriff "Wunsch an das Getriebe während einer ASR Regelung

MLB: Es wird nur 0x0 und 0x1 genutzt

";
CM_ SG_ 253 ASR_Tastung_passiv "ASR deaktiviert oder Schwellen geändert (projektabhängig)
Weiterführende Informationen im Lastenheft spezifiziert und in der entsprechenden Fachabteilung zu erfragen.
";
CM_ SG_ 253 BR_Eingriffsmoment "Einheitenloser Wert! Faktor in MO_Faktor_Momente_02 in Motor_Code_01 beachten!
Schnelle reduzierende (ASR) oder erhöhende (MSR) Momentanforderung an den Motor.";
CM_ SG_ 253 EBV_Eingriff "Elektronische Bremskraftverteilung, aktueller Eingriff (Druckhalten, Druckabbau)

Im MLB: kein ABS / ESP-Eingriff ???";
CM_ SG_ 253 EDS_Eingriff "Elektronische Differentialsperre";
CM_ SG_ 253 ESC_Neutralschaltung "Aufforderung seitens ABS an das Getriebe die Momentenübertragung zu unterbrechen";
CM_ SG_ 253 ESC_v_Signal_Qualifier_High_Low "Das Qualifizerungssignal ESC_v_Signal_Qualifier_High_Low gibt eine Information über die Güte der vom Bremsregelsystem ausgegebenen Geschwindigkeitsinformation 'mittlere Geschwindigkeit', wobei Vertrauensbereiche für das ausgegebene Geschwindigkeitssignal ";
CM_ SG_ 253 ESP_21_CRC "Für MLB:
'Berechnung siehe Lastenheft 'Kommunikationsabsicherung für FlexRay und CAN''

Ab MQB und MLBevo:
'Berechnung siehe Lastenheft 'End-to-End Kommunikationsabsicherung''

Endwerte siehe Begleitdokument 'S-PDU Kennungsfolgen'";
CM_ SG_ 253 ESP_ASP "MLB: Anhaenger-Stabilisierungs-Programm
MQB: Gespannstabilisierung";
CM_ SG_ 253 ESP_Diagnose "MLB: Nach Diagnoseende wird ein SW-Reset ausgelöst welcher einen Kommunikatiosausfall für max. 150ms verursacht. Dies ist bei SG mit verschärfter Timeoutüberwachung (nicht nach Konzern-LH) zu beachten.

MQB: Weiterführende Informationen im Lastenheft sp";
CM_ SG_ 253 ESP_Eingriff "Eingriff des Fahrdynamikreglers";
CM_ SG_ 253 ESP_QBit_v_Signal "Geschwindigkeit wird vom ABS/ASR oder ESP aus Ersatzwerten errechnet, wenn Bit gesetzt ist. Güte des Signals ist verändert.";
CM_ SG_ 253 ESP_Systemstatus "Fehler steht für Stillegung ESP mit Fehlereintrag.

MLB: Flag wird bei Unterspannung im Stand bis einmalig 6km/h (AU48x) oder 10 km/h (AU641, AU57x) überschritten nicht gesetzt (Ausblendung Startvorgang)
Im AU64x, AU57x gilt ESP D4 Funktionsanforderung";
CM_ SG_ 253 ESP_Tastung_passiv "ESP deaktiviert oder Schwellen geändert (projektabhängig)
Weiterführende Informationen im Lastenheft spezifiziert und in der entsprechenden Fachabteilung zu erfragen.";
CM_ SG_ 253 ESP_v_Signal "Geschwindigkeitssignal vom ABS/ASR oder ESP. Mittelwert der angetriebenen Räder.
Bei MSR oder ABS Eingriffen wird die ABS-Referenzgeschwindigkeit für >= 200ms eingespiegelt (Zeit wird mit Aktiv-Flanke der Funktionsbits getriggert)

MQB: Bei Frontantrie";
CM_ SG_ 253 ESP_Vorsteuerung "zur Unterscheidung zwischen ESP-Vorsteuermaßnahmen und ESP-Regeleingriffen";
CM_ SG_ 253 MSR_Anf "MLB: Die Momentenanforderung 'ASR_MSR_Moment_schnell' ist auszuführen.
MQB: Die Momentenanforderung 'BR_Eingriffsmoment' ist auszuführen";
CM_ SG_ 253 OBD_Schlechtweg "Für Ausblendung der Zündaussetzererkennung im Motorsteuergerät (Otto). Bit wird gesetzt, wenn Rad-Drehbeschleunigung im ESP > Grenzwert ist. Vorteil gegenüber Radgeschwindigkeiten, dass ESP alle 2 ms dynamisch die Rad-Drehbeschleunigung errechnet und dem ";

CM_ SG_ 1470 BR_QBit_Reifenumfang_sekundaer "QBit des Signals BR_Reifenumfang_sekundaer. 
Gesetzt bei Ersatzwert, Init oder Fehler.";
CM_ SG_ 1470 BR_Reifenumfang_sekundaer "Radumfang der Sekundärchse gerechnet in Millimeter.
Von der Bremse plausibilisierter Wert (Kopie von KBI_Reifenumfang_sekundaer wenn dieser plausibel) 
oder Ersatzwert aus Bremse wenn KBI_Reifenumfang_sekundaer unplausibel. Bitte das QBit beachten!
";
CM_ SG_ 1470 ESP_23_CRC "Für MLB:
'Berechnung siehe Lastenheft 'Kommunikationsabsicherung für FlexRay und CAN''

Ab MQB und MLBevo:
'Berechnung siehe Lastenheft 'End-to-End Kommunikationsabsicherung''

Endwerte siehe Begleitdokument 'S-PDU Kennungsfolgen'";
CM_ SG_ 1470 ESP_Gierrate_Offset_2 "Gierratenoffset berechnet durch ESP-Modell. 

nur für MLBevo gilt:
Der Offsetwert entspricht der Abweichung nach Anti-DIN-Vorzeichenlogik.
Gierrate_korrigiert = Gierrate_Rohwert + Gierratenoffset";
CM_ SG_ 1470 ESP_Laengsbeschleunigung_Offset "Offset der Längsbeschleunigung
Längsbeschleunigung = Rohwert - Offset

nur für MLBevo gilt:
Laengsbeschleunigungsoffset berechnet durch ESP-Modell. 
Laengsbeschleunigung_korrigiert = Laengsbeschleunigung_Rohwert - Laengsbeschleunigungsoffset";
CM_ SG_ 1470 ESP_Lenkwinkel_Offset "Lenkwinkelsoffset berechnet durch ESP-Modell!

nur für MLBevo gilt:
Der Offsetwert entspricht der Abweichung nach Anti-DIN-Vorzeichenlogik.
Lenkwinkel_korrigiert = Lenkwinkel_Rohwert + Lenkwinkeloffset";
CM_ SG_ 1470 ESP_Querbeschleunigung_Offset "Offset der Querbeschleunigung
Querbeschleunigung = Rohwert - Offset

nur für MLBevo gilt:
Querbeschleunigungsoffset berechnet durch ESP-Modell. 
Der Offsetwert entspricht der Abweichung nach Anti-DIN-Vorzeichenlogik.
Querbeschleunigung_korrigiert = ";

CM_ SG_ 508 ESC_Anforderung_Airbrake "ESC fordert die Bremsperformancestellung der aktiven Aerodynamik";
CM_ SG_ 508 ESC_FBA_Meldungen "Hinweis an den Fahrer über das Kombi, bei dauerhafter Bergabfahrt einen Gang einzulegen um die Motorbremse zu nutzen.
Unterscheidung zwischen: 
Handschalterfahrzeugen (FBA_Warnung_aktiv_MT)
Automatikfahrzeugen (FBA_Warnung_aktiv_AT)";
CM_ SG_ 508 ESC_MBK_Meldungen "Das Signal steuert die Schaltempfehlung im Kombi, die bei Bergabfahrt den Fahrer darauf hinweist in eine geeignete Fahrstufe zu schalten um eine Rekuperation zu ermöglichen.";
CM_ SG_ 508 ESC_Motorstartverzoegerung "Mit dem Signal 'Motorstartverzögerung' wird den aktiven Teilnehmern ermöglicht, einen Motorstart durch die Start-Stop-Funktion zu verzögern.";
CM_ SG_ 508 ESP_32_BZ "Botschaft asynchron geroutet. Zählerwert kann springen.";
CM_ SG_ 508 ESP_32_CRC "Für MLB:
'Berechnung siehe Lastenheft 'Kommunikationsabsicherung für FlexRay und CAN''

Ab MQB und MLBevo:
'Berechnung siehe Lastenheft 'End-to-End Kommunikationsabsicherung''

Endwerte siehe Begleitdokument 'S-PDU Kennungsfolgen'";
CM_ SG_ 508 ESP_Aggregataktivitaet "Info über die Aktivität des ESP Aggregats bei aktivem Druckaufbau oder Ventilaktivität";
CM_ SG_ 508 ESP_AVH_LED "Ansteuerung der AVH Funktions-LED durch das BCM.
0 = LED aus
1 = LED ein
2 = LED blinken
3 = Funktion gesperrt, LED aus
4 = frei
5 = frei
6 = Init
7 = frei";
CM_ SG_ 508 ESP_EDS_Anzeige "Grafische Anzeige der EDS-Funktion im Kombiinstrument und MMI für Bentley";
CM_ SG_ 508 ESP_HDC_LED "Ansteuerung der HDC LED in der Schalterleiste durch BCM
0 = LED aus
1 = LED ein
2 = LED blinken
3 = Funktion gesperrt, LED aus
4 = frei
5 = frei
6 = Init
7 = frei";
CM_ SG_ 508 ESP_HDC_Textanzeigen "Textanzeigen der HDC im Kombiinstrument
Zustände 16,17,18 nur für Porsche";
CM_ SG_ 508 ESP_HOLD_verf "Das Signal ESP_HOLD_verf = 1 signalisiert dem Empfänger, dass die Aktivierungsbedingungen für die autonome HOLD-Funktion erfüllt sind (Steigung > parametrierbare Grenzsteigung mit Wunschfahrtrichtung bergauf) und die autonome HOLD-Funktion aktivierbar ist";
CM_ SG_ 508 ESP_Notbremsanzeige "ABS/ASR oder ESP hat Notbremssituation erkannt.
Weiterführende Informationen im Lastenheft spezifiziert und in der entsprechenden Fachabteilung zu erfragen.

";
CM_ SG_ 508 ESP_Off_LED "Ansteuerung der ESP-Off LED in der Schalterleiste durch BCM
0 = LED aus
1 = LED ein
2 = LED blinken
3 = Funktion gesperrt, LED aus
4 = frei
5 = frei
6 = Init
7 = frei";
CM_ SG_ 508 ESP_Offroad_Lampe "Anzeige der ESC-Offroad-Lampe im Kombiinstrument für Bentley";
CM_ SG_ 508 ESP_Rollover_Status_dyn "Information vom ESP an die Dämpferregelung über den dynamischen Rolloverstatus";
CM_ SG_ 508 ESP_Rollover_Status_stat "Information vom ESP an die Dämpferregelung über den statischen Rolloverstatus";
CM_ SG_ 508 ESP_Status_Bremsentemp_02 "Bremsscheibentemperaturmodell. Rückmeldung für Sender einer Verzögerungsanforderung";
CM_ SG_ 508 ESP_Stillstandsflag "Bei RB-Projekten wird das Stillstandsflag gesetzt, wenn der absolute Stillstand der Raddrehzahlsensoren erkannt wurde, d.h. kein Zahn bewegt sich mehr. Dieses Bit wird bspw. im MOST für TV-Tuner-Abschaltung Australien verwendet, d.h. leichte Erschütterung";
CM_ SG_ 508 ESP_Wiederstart_Anz_Std "Dieses Signal gibt die detaillierte Begründung für einen Wiederstart vom Bremsensteuergerät ausgelöst durch die HBC Funktion an.";
CM_ SG_ 508 RLE_Anzeigen "Anzeigen für die Radlöseerkennung";
BA_DEF_REL_ BU_SG_REL_  "GenSigTimeoutTime" INT 0 65535;
BA_DEF_ BO_  "DiagRequest" ENUM "No", "Yes";
BA_DEF_ BO_  "DiagResponse" ENUM "No", "Yes";
BA_DEF_ BO_  "DiagState" ENUM "No", "Yes";
BA_DEF_ BO_  "GenMsgChkConstant" HEX 0 4095;
BA_DEF_ BO_  "GenMsgCycleTime" INT 0 65535;
BA_DEF_ BO_  "GenMsgCycleTimeFast" INT 0 65535;
BA_DEF_ BO_  "GenMsgDelayTime" INT 0 100000;
BA_DEF_ BO_  "GenMsgILSupport" ENUM "No", "Yes";
BA_DEF_ BO_  "GenMsgNrOfRepetition" INT 0 100;
BA_DEF_ BO_  "GenMsgPDUConstants" STRING;
BA_DEF_ BO_  "GenMsgSendType" ENUM "Cyclic", "not_used", "not_used", "not_used", "not_used", "not_used", "not_used", "IfActive", "NoMsgSendType";
BA_DEF_ BO_  "GenMsgStartDelayTime" INT 0 100000;
BA_DEF_ BO_  "NmMessage" ENUM "No", "Yes";
BA_DEF_ BO_  "NmhMessage" ENUM "No", "Yes";
BA_DEF_ BO_  "MsgType" ENUM "Application", "NM ", "NMH", "TP2.0", "ISO-TP ", "BAP", "EID", "KS";
BA_DEF_ BO_  "VAGTP20_API" HEX 0 255;
BA_DEF_ BO_  "VAGTP20_DynConnection" ENUM "No", "Yes";
BA_DEF_ BO_  "VAGTP20_DynSetup" ENUM "No", "Yes";
BA_DEF_ BO_  "VAGTP20_StatConnection" ENUM "No", "Yes";
BA_DEF_ SG_  "GenSigActiveRepetitions" INT -2147483648 2147483647;
BA_DEF_ SG_  "GenSigInactiveValue" INT -2147483648 2147483647;
BA_DEF_ SG_  "GenSigSendType" ENUM "Cyclic", "OnWrite", "OnWriteWithRepetition", "OnChange", "OnChangeWithRepetition", "IfActive", "IfActiveWithRepetition", "NoSigSendType", "OnChangeAndIfActive", "OnChangeAndIfActiveWithRepetition";
BA_DEF_ SG_  "GenSigStartValue" INT -2147483648 2147483647;
BA_DEF_ SG_  "NWM-WakeupAllowed" ENUM "No", "Yes";
BA_DEF_ SG_  "GenSigFuncType" ENUM "NoFunction", "MsgCounter", "CRC-8", "XOR", "XOR-2", "DatedBit", "SW-Kl15", "CHK", "Constant", "Protocol", "CRC-8-SAE_J1850";
BA_DEF_ SG_  "GenSigSwitchedByIgnition" ENUM "No", "Yes";
BA_DEF_ SG_  "Fehlerwert" HEX 0 2147483647;
BA_DEF_ SG_  "GenSigMissingSourceValue" HEX 0 2147483647;
BA_DEF_DEF_REL_  "GenSigTimeoutTime" 0;
BA_DEF_DEF_  "DiagRequest" "No";
BA_DEF_DEF_  "DiagResponse" "No";
BA_DEF_DEF_  "DiagState" "No";
BA_DEF_DEF_  "GenMsgChkConstant" 0;
BA_DEF_DEF_  "GenMsgCycleTime" 0;
BA_DEF_DEF_  "GenMsgCycleTimeFast" 0;
BA_DEF_DEF_  "GenMsgDelayTime" 0;
BA_DEF_DEF_  "GenMsgILSupport" "No";
BA_DEF_DEF_  "GenMsgNrOfRepetition" 0;
BA_DEF_DEF_  "GenMsgPDUConstants" "";
BA_DEF_DEF_  "GenMsgSendType" "NoMsgSendType";
BA_DEF_DEF_  "GenMsgStartDelayTime" 0;
BA_DEF_DEF_  "NmMessage" "No";
BA_DEF_DEF_  "NmhMessage" "No";
BA_DEF_DEF_  "MsgType" "Application";
BA_DEF_DEF_  "VAGTP20_API" 0;
BA_DEF_DEF_  "VAGTP20_DynConnection" "No";
BA_DEF_DEF_  "VAGTP20_DynSetup" "No";
BA_DEF_DEF_  "VAGTP20_StatConnection" "No";
BA_DEF_DEF_  "GenSigActiveRepetitions" 0;
BA_DEF_DEF_  "GenSigInactiveValue" 0;
BA_DEF_DEF_  "GenSigSendType" "NoSigSendType";
BA_DEF_DEF_  "GenSigStartValue" 0;
BA_DEF_DEF_  "NWM-WakeupAllowed" "No";
BA_DEF_DEF_  "GenSigFuncType" "NoFunction";
BA_DEF_DEF_  "GenSigSwitchedByIgnition" "Yes";
BA_DEF_DEF_  "Fehlerwert" 0;
BA_DEF_DEF_  "GenSigMissingSourceValue" 0;
BA_ "GenMsgCycleTime" BO_ 1432 1000;
BA_ "GenMsgCycleTimeFast" BO_ 1432 100;
BA_ "GenMsgDelayTime" BO_ 1432 50;
BA_ "GenMsgILSupport" BO_ 1432 1;
BA_ "GenMsgNrOfRepetition" BO_ 1432 5;
BA_ "GenMsgSendType" BO_ 1432 0;
BA_ "GenMsgCycleTime" BO_ 1431 500;
BA_ "GenMsgCycleTimeFast" BO_ 1431 50;
BA_ "GenMsgDelayTime" BO_ 1431 20;
BA_ "GenMsgILSupport" BO_ 1431 1;
BA_ "GenMsgNrOfRepetition" BO_ 1431 3;
BA_ "GenMsgSendType" BO_ 1431 0;
BA_ "GenMsgCycleTime" BO_ 870 1000;
BA_ "GenMsgCycleTimeFast" BO_ 870 50;
BA_ "GenMsgDelayTime" BO_ 870 10;
BA_ "GenMsgILSupport" BO_ 870 1;
BA_ "GenMsgNrOfRepetition" BO_ 870 5;
BA_ "GenMsgSendType" BO_ 870 0;
BA_ "GenMsgCycleTimeFast" BO_ 868 50;
BA_ "GenMsgDelayTime" BO_ 868 5;
BA_ "GenMsgILSupport" BO_ 868 1;
BA_ "GenMsgNrOfRepetition" BO_ 868 5;
BA_ "GenMsgSendType" BO_ 868 7;
BA_ "MsgType" BO_ 2617128448 6;
BA_ "MsgType" BO_ 2617128449 6;
BA_ "MsgType" BO_ 2617167360 6;
BA_ "MsgType" BO_ 2617167361 6;
BA_ "GenMsgCycleTime" BO_ 901 1000;
BA_ "GenMsgDelayTime" BO_ 901 50;
BA_ "GenMsgILSupport" BO_ 901 1;
BA_ "GenMsgSendType" BO_ 901 0;
BA_ "GenMsgStartDelayTime" BO_ 901 50;
BA_ "GenMsgCycleTime" BO_ 902 1000;
BA_ "GenMsgDelayTime" BO_ 902 50;
BA_ "GenMsgILSupport" BO_ 902 1;
BA_ "GenMsgSendType" BO_ 902 0;
BA_ "GenMsgStartDelayTime" BO_ 902 50;
BA_ "GenMsgCycleTime" BO_ 1000 1000;
BA_ "GenMsgDelayTime" BO_ 1000 50;
BA_ "GenMsgILSupport" BO_ 1000 1;
BA_ "GenMsgSendType" BO_ 1000 0;
BA_ "GenMsgStartDelayTime" BO_ 1000 55;
BA_ "GenMsgCycleTime" BO_ 1022 1000;
BA_ "GenMsgDelayTime" BO_ 1022 50;
BA_ "GenMsgILSupport" BO_ 1022 1;
BA_ "GenMsgSendType" BO_ 1022 0;
BA_ "MsgType" BO_ 2617012736 6;
BA_ "MsgType" BO_ 2617012991 6;
BA_ "MsgType" BO_ 2617037312 6;
BA_ "MsgType" BO_ 2617037567 6;
BA_ "MsgType" BO_ 2617127424 6;
BA_ "MsgType" BO_ 2617127679 6;
BA_ "MsgType" BO_ 2617166336 6;
BA_ "MsgType" BO_ 2617166337 6;
BA_ "MsgType" BO_ 2617166591 6;
BA_ "MsgType" BO_ 2617123584 6;
BA_ "MsgType" BO_ 2617123839 6;
BA_ "MsgType" BO_ 2617125632 6;
BA_ "MsgType" BO_ 2617125887 6;
BA_ "MsgType" BO_ 2549880614 4;
BA_ "MsgType" BO_ 2550011686 4;
BA_ "MsgType" BO_ 2549880393 4;
BA_ "MsgType" BO_ 2550011465 4;
BA_ "MsgType" BO_ 2549880347 4;
BA_ "MsgType" BO_ 2550011419 4;
BA_ "MsgType" BO_ 2549880340 4;
BA_ "MsgType" BO_ 2550011412 4;
BA_ "MsgType" BO_ 2549880341 4;
BA_ "MsgType" BO_ 2550011413 4;
BA_ "MsgType" BO_ 2549880577 4;
BA_ "MsgType" BO_ 2550011649 4;
BA_ "MsgType" BO_ 2549880639 4;
BA_ "MsgType" BO_ 2550011711 4;
BA_ "MsgType" BO_ 2549880330 4;
BA_ "MsgType" BO_ 2550011402 4;
BA_ "MsgType" BO_ 2549880331 4;
BA_ "MsgType" BO_ 2550011403 4;
BA_ "MsgType" BO_ 2549880633 4;
BA_ "MsgType" BO_ 2550011705 4;
BA_ "MsgType" BO_ 2549880350 4;
BA_ "MsgType" BO_ 2550011422 4;
BA_ "MsgType" BO_ 2549880427 4;
BA_ "MsgType" BO_ 2550011499 4;
BA_ "MsgType" BO_ 2549880428 4;
BA_ "MsgType" BO_ 2550011500 4;
BA_ "MsgType" BO_ 2549880612 4;
BA_ "MsgType" BO_ 2550011684 4;
BA_ "MsgType" BO_ 2549880324 4;
BA_ "MsgType" BO_ 2550011396 4;
BA_ "MsgType" BO_ 2549880321 4;
BA_ "MsgType" BO_ 2550011393 4;
BA_ "GenMsgCycleTime" BO_ 1714 1000;
BA_ "GenMsgILSupport" BO_ 1714 1;
BA_ "GenMsgSendType" BO_ 1714 0;
BA_ "GenMsgStartDelayTime" BO_ 1714 55;
BA_ "GenMsgCycleTime" BO_ 1520 200;
BA_ "GenMsgDelayTime" BO_ 1520 50;
BA_ "GenMsgILSupport" BO_ 1520 1;
BA_ "GenMsgSendType" BO_ 1520 0;
BA_ "GenMsgCycleTime" BO_ 420 500;
BA_ "GenMsgILSupport" BO_ 420 1;
BA_ "GenMsgPDUConstants" BO_ 420 "0x69,0xbb,0x54,0xe6,0x4e,0x46,0x8d,0x7b,0xea,0x87,0xe9,0xb3,0x63,0xce,0xf8,0xbf";
BA_ "GenMsgSendType" BO_ 420 0;
BA_ "GenMsgCycleTime" BO_ 496 50;
BA_ "GenMsgDelayTime" BO_ 496 20;
BA_ "GenMsgILSupport" BO_ 496 1;
BA_ "GenMsgPDUConstants" BO_ 496 "0x2f,0x3c,0x22,0x60,0x18,0xeb,0x63,0x76,0xc5,0x91,0x0f,0x27,0x34,0x04,0x7f,0x02";
BA_ "GenMsgSendType" BO_ 496 0;
BA_ "GenMsgCycleTime" BO_ 2527679980 500;
BA_ "GenMsgDelayTime" BO_ 2527679980 50;
BA_ "GenMsgILSupport" BO_ 2527679980 1;
BA_ "GenMsgSendType" BO_ 2527679980 0;
BA_ "GenMsgCycleTime" BO_ 1603 1000;
BA_ "GenMsgDelayTime" BO_ 1603 100;
BA_ "GenMsgILSupport" BO_ 1603 1;
BA_ "GenMsgSendType" BO_ 1603 0;
BA_ "GenMsgChkConstant" BO_ 260 5;
BA_ "GenMsgCycleTime" BO_ 260 500;
BA_ "GenMsgDelayTime" BO_ 260 40;
BA_ "GenMsgILSupport" BO_ 260 1;
BA_ "GenMsgPDUConstants" BO_ 260 "0x05,0x05,0x05,0x05,0x05,0x05,0x05,0x05,0x05,0x05,0x05,0x05,0x05,0x05,0x05,0x05";
BA_ "GenMsgSendType" BO_ 260 0;
BA_ "GenMsgChkConstant" BO_ 259 2;
BA_ "GenMsgCycleTime" BO_ 259 20;
BA_ "GenMsgILSupport" BO_ 259 1;
BA_ "GenMsgPDUConstants" BO_ 259 "0x02,0x02,0x02,0x02,0x02,0x02,0x02,0x02,0x02,0x02,0x02,0x02,0x02,0x02,0x02,0x02";
BA_ "GenMsgSendType" BO_ 259 0;
BA_ "GenMsgChkConstant" BO_ 914 145;
BA_ "GenMsgCycleTime" BO_ 914 80;
BA_ "GenMsgILSupport" BO_ 914 1;
BA_ "GenMsgPDUConstants" BO_ 914 "0x91,0x91,0x91,0x91,0x91,0x91,0x91,0x91,0x91,0x91,0x91,0x91,0x91,0x91,0x91,0x91";
BA_ "GenMsgSendType" BO_ 914 0;
BA_ "GenMsgChkConstant" BO_ 278 172;
BA_ "GenMsgCycleTime" BO_ 278 20;
BA_ "GenMsgILSupport" BO_ 278 1;
BA_ "GenMsgPDUConstants" BO_ 278 "0xac,0xac,0xac,0xac,0xac,0xac,0xac,0xac,0xac,0xac,0xac,0xac,0xac,0xac,0xac,0xac";
BA_ "GenMsgSendType" BO_ 278 0;
BA_ "GenMsgCycleTime" BO_ 418 200;
BA_ "GenMsgDelayTime" BO_ 418 20;
BA_ "GenMsgILSupport" BO_ 418 1;
BA_ "GenMsgPDUConstants" BO_ 418 "0xcb,0x47,0xd7,0xd2,0x56,0x3e,0x20,0xea,0x6e,0x6d,0x8c,0x1b,0xdf,0x49,0xaa,0xab";
BA_ "GenMsgSendType" BO_ 418 0;
BA_ "GenMsgCycleTime" BO_ 253 20;
BA_ "GenMsgILSupport" BO_ 253 1;
BA_ "GenMsgPDUConstants" BO_ 253 "0xb4,0xef,0xf8,0x49,0x1e,0xe5,0xc2,0xc0,0x97,0x19,0x3c,0xc9,0xf1,0x98,0xd6,0x61";
BA_ "GenMsgSendType" BO_ 253 0;
BA_ "GenMsgCycleTime" BO_ 1470 320;
BA_ "GenMsgILSupport" BO_ 1470 1;
BA_ "GenMsgPDUConstants" BO_ 1470 "0xc9,0x21,0x6f,0x63,0xd2,0x42,0x6a,0x77,0x4a,0x3d,0xb0,0x62,0x9f,0x38,0xcd,0x5c";
BA_ "GenMsgSendType" BO_ 1470 0;
BA_ "GenMsgCycleTime" BO_ 508 100;
BA_ "GenMsgILSupport" BO_ 508 1;
BA_ "GenMsgPDUConstants" BO_ 508 "0x01,0x10,0x05,0xde,0xe0,0xdc,0x34,0xc4,0x8a,0xb1,0x6d,0x7b,0x62,0xef,0x1f,0x95";
BA_ "GenMsgSendType" BO_ 508 0;
BA_ "GenSigSendType" SG_ 1432 BCM1_eSound_Taster 3;
BA_ "GenSigStartValue" SG_ 1432 BCM1_eSound_Taster 2;
BA_ "GenSigSwitchedByIgnition" SG_ 1432 BCM1_eSound_Taster 0;
BA_ "Fehlerwert" SG_ 1432 BCM1_eSound_Taster 3;
BA_ "GenSigActiveRepetitions" SG_ 1432 BCM1_NR_Ride_Height_Down_Taster 5;
BA_ "GenSigSendType" SG_ 1432 BCM1_NR_Ride_Height_Down_Taster 4;
BA_ "GenSigStartValue" SG_ 1432 BCM1_NR_Ride_Height_Down_Taster 2;
BA_ "GenSigSwitchedByIgnition" SG_ 1432 BCM1_NR_Ride_Height_Down_Taster 0;
BA_ "Fehlerwert" SG_ 1432 BCM1_NR_Ride_Height_Down_Taster 3;
BA_ "GenSigActiveRepetitions" SG_ 1432 BCM1_NR_Ride_Height_Up_Taster 5;
BA_ "GenSigSendType" SG_ 1432 BCM1_NR_Ride_Height_Up_Taster 4;
BA_ "GenSigStartValue" SG_ 1432 BCM1_NR_Ride_Height_Up_Taster 2;
BA_ "GenSigSwitchedByIgnition" SG_ 1432 BCM1_NR_Ride_Height_Up_Taster 0;
BA_ "Fehlerwert" SG_ 1432 BCM1_NR_Ride_Height_Up_Taster 3;
BA_ "GenSigSendType" SG_ 1432 BCM_BFS_Fernsteuerung_aktiv 3;
BA_ "GenSigSwitchedByIgnition" SG_ 1432 BCM_BFS_Fernsteuerung_aktiv 0;
BA_ "GenSigSendType" SG_ 1432 BCM_BFS_Massage_Taster 3;
BA_ "GenSigSwitchedByIgnition" SG_ 1432 BCM_BFS_Massage_Taster 0;
BA_ "GenSigSendType" SG_ 1432 BCM_BFS_Multif_Taster 3;
BA_ "GenSigSwitchedByIgnition" SG_ 1432 BCM_BFS_Multif_Taster 0;
BA_ "GenSigSendType" SG_ 1432 BCM_BFS_Pneumatik_Verstellung 3;
BA_ "GenSigSwitchedByIgnition" SG_ 1432 BCM_BFS_Pneumatik_Verstellung 0;
BA_ "GenSigSendType" SG_ 1432 BCM_BFS_Programmwippe 3;
BA_ "GenSigSwitchedByIgnition" SG_ 1432 BCM_BFS_Programmwippe 0;
BA_ "GenSigSendType" SG_ 1432 BCM_FS_Massage_Taster 3;
BA_ "GenSigSwitchedByIgnition" SG_ 1432 BCM_FS_Massage_Taster 0;
BA_ "GenSigSendType" SG_ 1432 BCM_FS_Multif_Taster 3;
BA_ "GenSigSwitchedByIgnition" SG_ 1432 BCM_FS_Multif_Taster 0;
BA_ "GenSigSendType" SG_ 1432 BCM_FS_Pneumatik_Verstellung 3;
BA_ "GenSigSwitchedByIgnition" SG_ 1432 BCM_FS_Pneumatik_Verstellung 0;
BA_ "GenSigSendType" SG_ 1432 BCM_FS_Programmwippe 3;
BA_ "GenSigSwitchedByIgnition" SG_ 1432 BCM_FS_Programmwippe 0;
BA_ "GenSigActiveRepetitions" SG_ 1432 BCM_Soundklappe_Taster 5;
BA_ "GenSigSendType" SG_ 1432 BCM_Soundklappe_Taster 4;
BA_ "GenSigSwitchedByIgnition" SG_ 1432 BCM_Soundklappe_Taster 0;
BA_ "GenSigSendType" SG_ 1432 E_Sound_LED_Status 3;
BA_ "GenSigSwitchedByIgnition" SG_ 1432 E_Sound_LED_Status 0;
BA_ "Fehlerwert" SG_ 1432 E_Sound_LED_Status 3;
BA_ "GenSigActiveRepetitions" SG_ 1432 LIM_Rear_Mode 5;
BA_ "GenSigSendType" SG_ 1432 LIM_Rear_Mode 4;
BA_ "GenSigSwitchedByIgnition" SG_ 1432 LIM_Rear_Mode 0;
BA_ "GenSigActiveRepetitions" SG_ 1432 LIM_S_Rollo_hi 5;
BA_ "GenSigSendType" SG_ 1432 LIM_S_Rollo_hi 4;
BA_ "GenSigSwitchedByIgnition" SG_ 1432 LIM_S_Rollo_hi 0;
BA_ "GenSigActiveRepetitions" SG_ 1432 LIM_S_Rollo_vo 5;
BA_ "GenSigSendType" SG_ 1432 LIM_S_Rollo_vo 4;
BA_ "GenSigSwitchedByIgnition" SG_ 1432 LIM_S_Rollo_vo 0;
BA_ "GenSigActiveRepetitions" SG_ 1432 LIM_S_SAD_hi 5;
BA_ "GenSigSendType" SG_ 1432 LIM_S_SAD_hi 4;
BA_ "GenSigSwitchedByIgnition" SG_ 1432 LIM_S_SAD_hi 0;
BA_ "GenSigActiveRepetitions" SG_ 1432 LIM_S_SAD_Vo 5;
BA_ "GenSigSendType" SG_ 1432 LIM_S_SAD_Vo 4;
BA_ "GenSigSwitchedByIgnition" SG_ 1432 LIM_S_SAD_Vo 0;
BA_ "GenSigSendType" SG_ 1432 Pilot_Taster 3;
BA_ "GenSigStartValue" SG_ 1432 Pilot_Taster 2;
BA_ "GenSigSwitchedByIgnition" SG_ 1432 Pilot_Taster 0;
BA_ "Fehlerwert" SG_ 1432 Pilot_Taster 3;
BA_ "GenSigActiveRepetitions" SG_ 1431 BED_Rollo_vo 3;
BA_ "GenSigSendType" SG_ 1431 BED_Rollo_vo 4;
BA_ "GenSigSwitchedByIgnition" SG_ 1431 BED_Rollo_vo 0;
BA_ "GenSigActiveRepetitions" SG_ 1431 BED_SAD_vo 3;
BA_ "GenSigSendType" SG_ 1431 BED_SAD_vo 4;
BA_ "GenSigSwitchedByIgnition" SG_ 1431 BED_SAD_vo 0;
BA_ "GenSigActiveRepetitions" SG_ 1431 BED_Taster_Fahrwerk 3;
BA_ "GenSigSendType" SG_ 1431 BED_Taster_Fahrwerk 4;
BA_ "GenSigSwitchedByIgnition" SG_ 1431 BED_Taster_Fahrwerk 0;
BA_ "GenSigActiveRepetitions" SG_ 1431 BED_Taster_Lift 3;
BA_ "GenSigSendType" SG_ 1431 BED_Taster_Lift 4;
BA_ "GenSigStartValue" SG_ 1431 BED_Taster_Lift 2;
BA_ "GenSigSwitchedByIgnition" SG_ 1431 BED_Taster_Lift 0;
BA_ "Fehlerwert" SG_ 1431 BED_Taster_Lift 3;
BA_ "GenSigActiveRepetitions" SG_ 1431 BED_Taster_VD_Oeffnen 3;
BA_ "GenSigSendType" SG_ 1431 BED_Taster_VD_Oeffnen 4;
BA_ "GenSigStartValue" SG_ 1431 BED_Taster_VD_Oeffnen 2;
BA_ "GenSigSwitchedByIgnition" SG_ 1431 BED_Taster_VD_Oeffnen 0;
BA_ "Fehlerwert" SG_ 1431 BED_Taster_VD_Oeffnen 3;
BA_ "GenSigActiveRepetitions" SG_ 1431 BED_Taster_VD_Schliessen 3;
BA_ "GenSigSendType" SG_ 1431 BED_Taster_VD_Schliessen 4;
BA_ "GenSigStartValue" SG_ 1431 BED_Taster_VD_Schliessen 2;
BA_ "GenSigSwitchedByIgnition" SG_ 1431 BED_Taster_VD_Schliessen 0;
BA_ "Fehlerwert" SG_ 1431 BED_Taster_VD_Schliessen 3;
BA_ "GenSigActiveRepetitions" SG_ 1431 BED_Taster_Windschott 3;
BA_ "GenSigSendType" SG_ 1431 BED_Taster_Windschott 4;
BA_ "GenSigStartValue" SG_ 1431 BED_Taster_Windschott 2;
BA_ "GenSigSwitchedByIgnition" SG_ 1431 BED_Taster_Windschott 0;
BA_ "Fehlerwert" SG_ 1431 BED_Taster_Windschott 3;
BA_ "GenSigSendType" SG_ 1431 SoSe_SunInt_2D_Li_Dash 0;
BA_ "GenSigStartValue" SG_ 1431 SoSe_SunInt_2D_Li_Dash 254;
BA_ "GenSigSwitchedByIgnition" SG_ 1431 SoSe_SunInt_2D_Li_Dash 0;
BA_ "Fehlerwert" SG_ 1431 SoSe_SunInt_2D_Li_Dash 255;
BA_ "GenSigSendType" SG_ 1431 SoSe_SunInt_2D_Re_Dash 0;
BA_ "GenSigStartValue" SG_ 1431 SoSe_SunInt_2D_Re_Dash 254;
BA_ "GenSigSwitchedByIgnition" SG_ 1431 SoSe_SunInt_2D_Re_Dash 0;
BA_ "Fehlerwert" SG_ 1431 SoSe_SunInt_2D_Re_Dash 255;
BA_ "GenSigActiveRepetitions" SG_ 870 Blinken_li_Fzg_Takt 5;
BA_ "GenSigSendType" SG_ 870 Blinken_li_Fzg_Takt 4;
BA_ "GenSigSwitchedByIgnition" SG_ 870 Blinken_li_Fzg_Takt 0;
BA_ "GenSigActiveRepetitions" SG_ 870 Blinken_li_Kombi_Takt 5;
BA_ "GenSigSendType" SG_ 870 Blinken_li_Kombi_Takt 4;
BA_ "GenSigSwitchedByIgnition" SG_ 870 Blinken_li_Kombi_Takt 0;
BA_ "GenSigActiveRepetitions" SG_ 870 Blinken_re_Fzg_Takt 5;
BA_ "GenSigSendType" SG_ 870 Blinken_re_Fzg_Takt 4;
BA_ "GenSigSwitchedByIgnition" SG_ 870 Blinken_re_Fzg_Takt 0;
BA_ "GenSigActiveRepetitions" SG_ 870 Blinken_re_Kombi_Takt 5;
BA_ "GenSigSendType" SG_ 870 Blinken_re_Kombi_Takt 4;
BA_ "GenSigSwitchedByIgnition" SG_ 870 Blinken_re_Kombi_Takt 0;
BA_ "GenSigActiveRepetitions" SG_ 870 BM_Autobahn 5;
BA_ "GenSigSendType" SG_ 870 BM_Autobahn 4;
BA_ "GenSigSwitchedByIgnition" SG_ 870 BM_Autobahn 0;
BA_ "GenSigActiveRepetitions" SG_ 870 BM_Crash 5;
BA_ "GenSigSendType" SG_ 870 BM_Crash 4;
BA_ "GenSigSwitchedByIgnition" SG_ 870 BM_Crash 0;
BA_ "GenSigActiveRepetitions" SG_ 870 BM_DWA_Alarm 5;
BA_ "GenSigSendType" SG_ 870 BM_DWA_Alarm 4;
BA_ "GenSigSwitchedByIgnition" SG_ 870 BM_DWA_Alarm 0;
BA_ "GenSigActiveRepetitions" SG_ 870 BM_DWA_ein 5;
BA_ "GenSigSendType" SG_ 870 BM_DWA_ein 4;
BA_ "GenSigSwitchedByIgnition" SG_ 870 BM_DWA_ein 0;
BA_ "GenSigActiveRepetitions" SG_ 870 BM_GDO 5;
BA_ "GenSigSendType" SG_ 870 BM_GDO 4;
BA_ "GenSigSwitchedByIgnition" SG_ 870 BM_GDO 0;
BA_ "GenSigActiveRepetitions" SG_ 870 BM_HD_Oeffnung_angelernt 5;
BA_ "GenSigSendType" SG_ 870 BM_HD_Oeffnung_angelernt 4;
BA_ "GenSigSwitchedByIgnition" SG_ 870 BM_HD_Oeffnung_angelernt 0;
BA_ "GenSigActiveRepetitions" SG_ 870 BM_links 5;
BA_ "GenSigSendType" SG_ 870 BM_links 4;
BA_ "GenSigSwitchedByIgnition" SG_ 870 BM_links 0;
BA_ "GenSigActiveRepetitions" SG_ 870 BM_NBA_n_codiert_n_aktiv 5;
BA_ "GenSigSendType" SG_ 870 BM_NBA_n_codiert_n_aktiv 4;
BA_ "GenSigStartValue" SG_ 870 BM_NBA_n_codiert_n_aktiv 1;
BA_ "GenSigSwitchedByIgnition" SG_ 870 BM_NBA_n_codiert_n_aktiv 0;
BA_ "GenSigActiveRepetitions" SG_ 870 BM_NBA_Status 5;
BA_ "GenSigSendType" SG_ 870 BM_NBA_Status 4;
BA_ "GenSigSwitchedByIgnition" SG_ 870 BM_NBA_Status 0;
BA_ "GenSigActiveRepetitions" SG_ 870 BM_Not_Bremsung 5;
BA_ "GenSigSendType" SG_ 870 BM_Not_Bremsung 4;
BA_ "GenSigSwitchedByIgnition" SG_ 870 BM_Not_Bremsung 0;
BA_ "GenSigActiveRepetitions" SG_ 870 BM_Panik 5;
BA_ "GenSigSendType" SG_ 870 BM_Panik 4;
BA_ "GenSigSwitchedByIgnition" SG_ 870 BM_Panik 0;
BA_ "GenSigActiveRepetitions" SG_ 870 BM_PiloPa 5;
BA_ "GenSigSendType" SG_ 870 BM_PiloPa 4;
BA_ "GenSigSwitchedByIgnition" SG_ 870 BM_PiloPa 0;
BA_ "GenSigActiveRepetitions" SG_ 870 BM_Recas 5;
BA_ "GenSigSendType" SG_ 870 BM_Recas 4;
BA_ "GenSigSwitchedByIgnition" SG_ 870 BM_Recas 0;
BA_ "GenSigActiveRepetitions" SG_ 870 BM_rechts 5;
BA_ "GenSigSendType" SG_ 870 BM_rechts 4;
BA_ "GenSigSwitchedByIgnition" SG_ 870 BM_rechts 0;
BA_ "GenSigActiveRepetitions" SG_ 870 BM_Rollenmodus_Blinken 5;
BA_ "GenSigSendType" SG_ 870 BM_Rollenmodus_Blinken 4;
BA_ "GenSigSwitchedByIgnition" SG_ 870 BM_Rollenmodus_Blinken 0;
BA_ "GenSigActiveRepetitions" SG_ 870 BM_Taxi_Notalarm 5;
BA_ "GenSigSendType" SG_ 870 BM_Taxi_Notalarm 4;
BA_ "GenSigSwitchedByIgnition" SG_ 870 BM_Taxi_Notalarm 0;
BA_ "GenSigActiveRepetitions" SG_ 870 BM_Telematik 5;
BA_ "GenSigSendType" SG_ 870 BM_Telematik 4;
BA_ "GenSigSwitchedByIgnition" SG_ 870 BM_Telematik 0;
BA_ "GenSigActiveRepetitions" SG_ 870 BM_Telematik_Abbruchgrund 5;
BA_ "GenSigSendType" SG_ 870 BM_Telematik_Abbruchgrund 4;
BA_ "GenSigSwitchedByIgnition" SG_ 870 BM_Telematik_Abbruchgrund 0;
BA_ "GenSigActiveRepetitions" SG_ 870 BM_Warnblinken 5;
BA_ "GenSigSendType" SG_ 870 BM_Warnblinken 4;
BA_ "GenSigSwitchedByIgnition" SG_ 870 BM_Warnblinken 0;
BA_ "GenSigActiveRepetitions" SG_ 870 BM_WBT_Beleuchtung 5;
BA_ "GenSigSendType" SG_ 870 BM_WBT_Beleuchtung 4;
BA_ "GenSigSwitchedByIgnition" SG_ 870 BM_WBT_Beleuchtung 0;
BA_ "GenSigActiveRepetitions" SG_ 870 BM_Wischblinken 5;
BA_ "GenSigSendType" SG_ 870 BM_Wischblinken 4;
BA_ "GenSigSwitchedByIgnition" SG_ 870 BM_Wischblinken 0;
BA_ "GenSigActiveRepetitions" SG_ 870 BM_ZV_auf 5;
BA_ "GenSigSendType" SG_ 870 BM_ZV_auf 4;
BA_ "GenSigSwitchedByIgnition" SG_ 870 BM_ZV_auf 0;
BA_ "GenSigActiveRepetitions" SG_ 870 BM_ZV_zu 5;
BA_ "GenSigSendType" SG_ 870 BM_ZV_zu 4;
BA_ "GenSigSwitchedByIgnition" SG_ 870 BM_ZV_zu 0;
BA_ "GenSigSendType" SG_ 870 DWA_Alarmquelle 3;
BA_ "GenSigStartValue" SG_ 870 DWA_Alarmquelle 30;
BA_ "GenSigSwitchedByIgnition" SG_ 870 DWA_Alarmquelle 0;
BA_ "Fehlerwert" SG_ 870 DWA_Alarmquelle 31;
BA_ "GenSigActiveRepetitions" SG_ 868 NBlinken_li_Fzg_Takt 5;
BA_ "GenSigSendType" SG_ 868 NBlinken_li_Fzg_Takt 6;
BA_ "GenSigSwitchedByIgnition" SG_ 868 NBlinken_li_Fzg_Takt 0;
BA_ "GenSigActiveRepetitions" SG_ 868 NBlinken_li_Kombi_Takt 5;
BA_ "GenSigSendType" SG_ 868 NBlinken_li_Kombi_Takt 6;
BA_ "GenSigSwitchedByIgnition" SG_ 868 NBlinken_li_Kombi_Takt 0;
BA_ "GenSigActiveRepetitions" SG_ 868 NBlinken_re_Fzg_Takt 5;
BA_ "GenSigSendType" SG_ 868 NBlinken_re_Fzg_Takt 6;
BA_ "GenSigSwitchedByIgnition" SG_ 868 NBlinken_re_Fzg_Takt 0;
BA_ "GenSigActiveRepetitions" SG_ 868 NBlinken_re_Kombi_Takt 5;
BA_ "GenSigSendType" SG_ 868 NBlinken_re_Kombi_Takt 6;
BA_ "GenSigSwitchedByIgnition" SG_ 868 NBlinken_re_Kombi_Takt 0;
BA_ "GenSigFuncType" SG_ 2617128448 CCP_Klima_CRO_01_Data 9;
BA_ "GenSigSwitchedByIgnition" SG_ 2617128448 CCP_Klima_CRO_01_Data 0;
BA_ "GenSigFuncType" SG_ 2617128449 CCP_Klima_DTO_01_Data 9;
BA_ "GenSigSwitchedByIgnition" SG_ 2617128449 CCP_Klima_DTO_01_Data 0;
BA_ "GenSigFuncType" SG_ 2617167360 CCP_Lift_VA_CRO_01_Data 9;
BA_ "GenSigSwitchedByIgnition" SG_ 2617167360 CCP_Lift_VA_CRO_01_Data 0;
BA_ "GenSigFuncType" SG_ 2617167361 CCP_Lift_VA_DTO_01_Data 9;
BA_ "GenSigSwitchedByIgnition" SG_ 2617167361 CCP_Lift_VA_DTO_01_Data 0;
BA_ "GenSigSendType" SG_ 901 CHA_Fahrer_Umschaltung 3;
BA_ "GenSigSwitchedByIgnition" SG_ 901 CHA_Fahrer_Umschaltung 0;
BA_ "GenSigSendType" SG_ 901 CHA_Fahrer_Umschaltung_BMA 3;
BA_ "GenSigSwitchedByIgnition" SG_ 901 CHA_Fahrer_Umschaltung_BMA 0;
BA_ "GenSigSendType" SG_ 901 CHA_Ziel_FahrPr_ACC 3;
BA_ "GenSigSwitchedByIgnition" SG_ 901 CHA_Ziel_FahrPr_ACC 0;
BA_ "GenSigSendType" SG_ 901 CHA_Ziel_FahrPr_AFS 3;
BA_ "GenSigSwitchedByIgnition" SG_ 901 CHA_Ziel_FahrPr_AFS 0;
BA_ "GenSigSendType" SG_ 901 CHA_Ziel_FahrPr_AGA 3;
BA_ "GenSigSwitchedByIgnition" SG_ 901 CHA_Ziel_FahrPr_AGA 0;
BA_ "GenSigSendType" SG_ 901 CHA_Ziel_FahrPr_ALR 3;
BA_ "GenSigSwitchedByIgnition" SG_ 901 CHA_Ziel_FahrPr_ALR 0;
BA_ "GenSigSendType" SG_ 901 CHA_Ziel_FahrPr_DR 3;
BA_ "GenSigSwitchedByIgnition" SG_ 901 CHA_Ziel_FahrPr_DR 0;
BA_ "GenSigSendType" SG_ 901 CHA_Ziel_FahrPr_EPS 3;
BA_ "GenSigSwitchedByIgnition" SG_ 901 CHA_Ziel_FahrPr_EPS 0;
BA_ "GenSigSendType" SG_ 901 CHA_Ziel_FahrPr_ESP 3;
BA_ "GenSigSwitchedByIgnition" SG_ 901 CHA_Ziel_FahrPr_ESP 0;
BA_ "GenSigSendType" SG_ 901 CHA_Ziel_FahrPr_Freilauf 3;
BA_ "GenSigSwitchedByIgnition" SG_ 901 CHA_Ziel_FahrPr_Freilauf 0;
BA_ "GenSigSendType" SG_ 901 CHA_Ziel_FahrPr_GE 3;
BA_ "GenSigSwitchedByIgnition" SG_ 901 CHA_Ziel_FahrPr_GE 0;
BA_ "GenSigSendType" SG_ 901 CHA_Ziel_FahrPr_MO 3;
BA_ "GenSigSwitchedByIgnition" SG_ 901 CHA_Ziel_FahrPr_MO 0;
BA_ "GenSigSendType" SG_ 901 CHA_Ziel_FahrPr_MO_BZS 3;
BA_ "GenSigSwitchedByIgnition" SG_ 901 CHA_Ziel_FahrPr_MO_BZS 0;
BA_ "GenSigSendType" SG_ 901 CHA_Ziel_FahrPr_MO_StSt 3;
BA_ "GenSigSwitchedByIgnition" SG_ 901 CHA_Ziel_FahrPr_MO_StSt 0;
BA_ "GenSigSendType" SG_ 901 CHA_Ziel_FahrPr_PreCrash 3;
BA_ "GenSigSwitchedByIgnition" SG_ 901 CHA_Ziel_FahrPr_PreCrash 0;
BA_ "GenSigSendType" SG_ 901 CHA_Ziel_FahrPr_SAK 3;
BA_ "GenSigSwitchedByIgnition" SG_ 901 CHA_Ziel_FahrPr_SAK 0;
BA_ "GenSigSendType" SG_ 901 CHA_Ziel_FahrPr_VAQ 3;
BA_ "GenSigSwitchedByIgnition" SG_ 901 CHA_Ziel_FahrPr_VAQ 0;
BA_ "GenSigSendType" SG_ 902 CHA_Charge_LED 3;
BA_ "GenSigSwitchedByIgnition" SG_ 902 CHA_Charge_LED 0;
BA_ "GenSigSendType" SG_ 902 CHA_Current_Mode 3;
BA_ "GenSigSwitchedByIgnition" SG_ 902 CHA_Current_Mode 0;
BA_ "GenSigSendType" SG_ 902 CHA_Drehschalter_Istmodus 3;
BA_ "GenSigSwitchedByIgnition" SG_ 902 CHA_Drehschalter_Istmodus 0;
BA_ "GenSigSendType" SG_ 902 CHA_Eco_Charisma_LED 3;
BA_ "GenSigSwitchedByIgnition" SG_ 902 CHA_Eco_Charisma_LED 0;
BA_ "GenSigSendType" SG_ 902 CHA_EV_LED 3;
BA_ "GenSigSwitchedByIgnition" SG_ 902 CHA_EV_LED 0;
BA_ "GenSigSendType" SG_ 902 CHA_Fahrer_Umschaltung 3;
BA_ "GenSigSwitchedByIgnition" SG_ 902 CHA_Fahrer_Umschaltung 0;
BA_ "GenSigSendType" SG_ 902 CHA_Kombi_Texte 3;
BA_ "GenSigSwitchedByIgnition" SG_ 902 CHA_Kombi_Texte 0;
BA_ "GenSigSendType" SG_ 902 CHA_Kombi_Texte_02 3;
BA_ "GenSigSwitchedByIgnition" SG_ 902 CHA_Kombi_Texte_02 0;
BA_ "GenSigSendType" SG_ 902 CHA_Offroad_LED 3;
BA_ "GenSigSwitchedByIgnition" SG_ 902 CHA_Offroad_LED 0;
BA_ "Fehlerwert" SG_ 902 CHA_Offroad_LED 3;
BA_ "GenSigSendType" SG_ 902 CHA_Ziel_FahrPr_03_01 3;
BA_ "GenSigSwitchedByIgnition" SG_ 902 CHA_Ziel_FahrPr_03_01 0;
BA_ "GenSigSendType" SG_ 902 CHA_Ziel_FahrPr_03_02 3;
BA_ "GenSigSwitchedByIgnition" SG_ 902 CHA_Ziel_FahrPr_03_02 0;
BA_ "GenSigSendType" SG_ 902 CHA_Ziel_FahrPr_AMB 3;
BA_ "GenSigSwitchedByIgnition" SG_ 902 CHA_Ziel_FahrPr_AMB 0;
BA_ "GenSigSendType" SG_ 902 CHA_Ziel_FahrPr_HSP 3;
BA_ "GenSigSwitchedByIgnition" SG_ 902 CHA_Ziel_FahrPr_HSP 0;
BA_ "GenSigSendType" SG_ 902 CHA_Ziel_FahrPr_IVB 3;
BA_ "GenSigSwitchedByIgnition" SG_ 902 CHA_Ziel_FahrPr_IVB 0;
BA_ "GenSigSendType" SG_ 902 CHA_Ziel_FahrPr_KL 3;
BA_ "GenSigSwitchedByIgnition" SG_ 902 CHA_Ziel_FahrPr_KL 0;
BA_ "GenSigSendType" SG_ 902 CHA_Ziel_FahrPr_RWB 3;
BA_ "GenSigSwitchedByIgnition" SG_ 902 CHA_Ziel_FahrPr_RWB 0;
BA_ "GenSigSendType" SG_ 1000 CHA_Fahrer_Umschaltung 3;
BA_ "GenSigSwitchedByIgnition" SG_ 1000 CHA_Fahrer_Umschaltung 0;
BA_ "GenSigSendType" SG_ 1000 CHA_Ziel_FahrPr_AFR 3;
BA_ "GenSigSwitchedByIgnition" SG_ 1000 CHA_Ziel_FahrPr_AFR 0;
BA_ "GenSigSendType" SG_ 1000 CHA_Ziel_FahrPr_AV 3;
BA_ "GenSigSwitchedByIgnition" SG_ 1000 CHA_Ziel_FahrPr_AV 0;
BA_ "GenSigSendType" SG_ 1000 CHA_Ziel_FahrPr_EAR 3;
BA_ "GenSigSwitchedByIgnition" SG_ 1000 CHA_Ziel_FahrPr_EAR 0;
BA_ "GenSigSendType" SG_ 1000 CHA_Ziel_FahrPr_EBKV 3;
BA_ "GenSigSwitchedByIgnition" SG_ 1000 CHA_Ziel_FahrPr_EBKV 0;
BA_ "GenSigSendType" SG_ 1000 CHA_Ziel_FahrPr_FCWO 3;
BA_ "GenSigSwitchedByIgnition" SG_ 1000 CHA_Ziel_FahrPr_FCWO 0;
BA_ "GenSigSendType" SG_ 1000 CHA_Ziel_FahrPr_FCWP 3;
BA_ "GenSigSwitchedByIgnition" SG_ 1000 CHA_Ziel_FahrPr_FCWP 0;
BA_ "GenSigSendType" SG_ 1000 CHA_Ziel_FahrPr_HAL 3;
BA_ "GenSigSwitchedByIgnition" SG_ 1000 CHA_Ziel_FahrPr_HAL 0;
BA_ "GenSigSendType" SG_ 1000 CHA_Ziel_FahrPr_HDC 3;
BA_ "GenSigSwitchedByIgnition" SG_ 1000 CHA_Ziel_FahrPr_HDC 0;
BA_ "GenSigSendType" SG_ 1000 CHA_Ziel_FahrPr_IL 3;
BA_ "GenSigSwitchedByIgnition" SG_ 1000 CHA_Ziel_FahrPr_IL 0;
BA_ "GenSigSendType" SG_ 1000 CHA_Ziel_FahrPr_MXB 3;
BA_ "GenSigSwitchedByIgnition" SG_ 1000 CHA_Ziel_FahrPr_MXB 0;
BA_ "GenSigSendType" SG_ 1000 CHA_Ziel_FahrPr_NR 3;
BA_ "GenSigSwitchedByIgnition" SG_ 1000 CHA_Ziel_FahrPr_NR 0;
BA_ "GenSigSendType" SG_ 1000 CHA_Ziel_FahrPr_QS 3;
BA_ "GenSigSwitchedByIgnition" SG_ 1000 CHA_Ziel_FahrPr_QS 0;
BA_ "GenSigSendType" SG_ 1000 CHA_Ziel_FahrPr_SCU 3;
BA_ "GenSigSwitchedByIgnition" SG_ 1000 CHA_Ziel_FahrPr_SCU 0;
BA_ "GenSigSendType" SG_ 1000 CHA_Ziel_FahrPr_WarnBrems 3;
BA_ "GenSigSwitchedByIgnition" SG_ 1000 CHA_Ziel_FahrPr_WarnBrems 0;
BA_ "GenSigSendType" SG_ 1022 CHA_Current_Mode_BMA 3;
BA_ "GenSigSwitchedByIgnition" SG_ 1022 CHA_Current_Mode_BMA 0;
BA_ "GenSigSendType" SG_ 1022 CHA_Fahrer_Umschaltung 3;
BA_ "GenSigSwitchedByIgnition" SG_ 1022 CHA_Fahrer_Umschaltung 0;
BA_ "GenSigSendType" SG_ 1022 CHA_Fahrer_Umschaltung_BMA 3;
BA_ "GenSigSwitchedByIgnition" SG_ 1022 CHA_Fahrer_Umschaltung_BMA 0;
BA_ "GenSigSendType" SG_ 1022 CHA_Ziel_FahrPr_AGK 3;
BA_ "GenSigSwitchedByIgnition" SG_ 1022 CHA_Ziel_FahrPr_AGK 0;
BA_ "GenSigSendType" SG_ 1022 CHA_Ziel_FahrPr_BMS 3;
BA_ "GenSigSwitchedByIgnition" SG_ 1022 CHA_Ziel_FahrPr_BMS 0;
BA_ "GenSigSendType" SG_ 1022 CHA_Ziel_FahrPr_EDS 3;
BA_ "GenSigSwitchedByIgnition" SG_ 1022 CHA_Ziel_FahrPr_EDS 0;
BA_ "GenSigSendType" SG_ 1022 CHA_Ziel_FahrPr_HHC 3;
BA_ "GenSigSwitchedByIgnition" SG_ 1022 CHA_Ziel_FahrPr_HHC 0;
BA_ "GenSigSendType" SG_ 1022 CHA_Ziel_FahrPr_MO_Freilauf 3;
BA_ "GenSigSwitchedByIgnition" SG_ 1022 CHA_Ziel_FahrPr_MO_Freilauf 0;
BA_ "GenSigSendType" SG_ 1022 CHA_Ziel_FahrPr_PACC 3;
BA_ "GenSigSwitchedByIgnition" SG_ 1022 CHA_Ziel_FahrPr_PACC 0;
BA_ "GenSigSendType" SG_ 1022 CHA_Ziel_FahrPr_PDC 3;
BA_ "GenSigSwitchedByIgnition" SG_ 1022 CHA_Ziel_FahrPr_PDC 0;
BA_ "GenSigSwitchedByIgnition" SG_ 2617012736 DEV_BCM1_Resp_00_Data 0;
BA_ "GenSigSwitchedByIgnition" SG_ 2617012991 DEV_BCM1_Resp_FF_Data 0;
BA_ "GenSigSwitchedByIgnition" SG_ 2617037312 DEV_Klima_Fond_Tx_00_Data 0;
BA_ "GenSigSwitchedByIgnition" SG_ 2617037567 DEV_Klima_Fond_Tx_FF_Data 0;
BA_ "GenSigSwitchedByIgnition" SG_ 2617127424 DEV_Klima_Tx_00_Data 0;
BA_ "GenSigSwitchedByIgnition" SG_ 2617127679 DEV_Klima_Tx_FF_Data 0;
BA_ "GenSigFuncType" SG_ 2617166336 DEV_Lift_VA_Req_01_Data 9;
BA_ "GenSigSwitchedByIgnition" SG_ 2617166336 DEV_Lift_VA_Req_01_Data 0;
BA_ "GenSigFuncType" SG_ 2617166337 DEV_Lift_VA_Resp_01_Data 9;
BA_ "GenSigSwitchedByIgnition" SG_ 2617166337 DEV_Lift_VA_Resp_01_Data 0;
BA_ "GenSigFuncType" SG_ 2617166591 DEV_Lift_VA_Resp_FF_Data 9;
BA_ "GenSigSwitchedByIgnition" SG_ 2617166591 DEV_Lift_VA_Resp_FF_Data 0;
BA_ "GenSigSwitchedByIgnition" SG_ 2617123584 DEV_VAS_L_Resp_00_Data 0;
BA_ "GenSigSwitchedByIgnition" SG_ 2617123839 DEV_VAS_L_Resp_FF_Data 0;
BA_ "GenSigSwitchedByIgnition" SG_ 2617125632 DEV_VAS_R_Resp_00_Data 0;
BA_ "GenSigSwitchedByIgnition" SG_ 2617125887 DEV_VAS_R_Resp_FF_Data 0;
BA_ "GenSigSendType" SG_ 2549880614 DIA_AAU_Req_Data 3;
BA_ "GenSigFuncType" SG_ 2549880614 DIA_AAU_Req_Data 9;
BA_ "GenSigSwitchedByIgnition" SG_ 2549880614 DIA_AAU_Req_Data 0;
BA_ "GenSigSendType" SG_ 2550011686 DIA_AAU_Resp_Data 3;
BA_ "GenSigFuncType" SG_ 2550011686 DIA_AAU_Resp_Data 9;
BA_ "GenSigSwitchedByIgnition" SG_ 2550011686 DIA_AAU_Resp_Data 0;
BA_ "GenSigSendType" SG_ 2549880393 DIA_EVLS_Req_Data 3;
BA_ "GenSigFuncType" SG_ 2549880393 DIA_EVLS_Req_Data 9;
BA_ "GenSigSwitchedByIgnition" SG_ 2549880393 DIA_EVLS_Req_Data 0;
BA_ "GenSigSendType" SG_ 2550011465 DIA_EVLS_Resp_Data 3;
BA_ "GenSigFuncType" SG_ 2550011465 DIA_EVLS_Resp_Data 9;
BA_ "GenSigSwitchedByIgnition" SG_ 2550011465 DIA_EVLS_Resp_Data 0;
BA_ "GenSigSendType" SG_ 2549880347 DIA_Geblaese_Req_Data 3;
BA_ "GenSigFuncType" SG_ 2549880347 DIA_Geblaese_Req_Data 9;
BA_ "GenSigSwitchedByIgnition" SG_ 2549880347 DIA_Geblaese_Req_Data 0;
BA_ "GenSigSendType" SG_ 2550011419 DIA_Geblaese_Resp_Data 3;
BA_ "GenSigFuncType" SG_ 2550011419 DIA_Geblaese_Resp_Data 9;
BA_ "GenSigSwitchedByIgnition" SG_ 2550011419 DIA_Geblaese_Resp_Data 0;
BA_ "GenSigSendType" SG_ 2549880340 DIA_gLW_LM_L_Req_Data 3;
BA_ "GenSigFuncType" SG_ 2549880340 DIA_gLW_LM_L_Req_Data 9;
BA_ "GenSigSwitchedByIgnition" SG_ 2549880340 DIA_gLW_LM_L_Req_Data 0;
BA_ "GenSigSendType" SG_ 2550011412 DIA_gLW_LM_L_Resp_Data 3;
BA_ "GenSigFuncType" SG_ 2550011412 DIA_gLW_LM_L_Resp_Data 9;
BA_ "GenSigSwitchedByIgnition" SG_ 2550011412 DIA_gLW_LM_L_Resp_Data 0;
BA_ "GenSigSendType" SG_ 2549880341 DIA_gLW_LM_R_Req_Data 3;
BA_ "GenSigFuncType" SG_ 2549880341 DIA_gLW_LM_R_Req_Data 9;
BA_ "GenSigSwitchedByIgnition" SG_ 2549880341 DIA_gLW_LM_R_Req_Data 0;
BA_ "GenSigSendType" SG_ 2550011413 DIA_gLW_LM_R_Resp_Data 3;
BA_ "GenSigFuncType" SG_ 2550011413 DIA_gLW_LM_R_Resp_Data 9;
BA_ "GenSigSwitchedByIgnition" SG_ 2550011413 DIA_gLW_LM_R_Resp_Data 0;
BA_ "GenSigSendType" SG_ 2549880577 DIA_KBF_Req_Data 3;
BA_ "GenSigFuncType" SG_ 2549880577 DIA_KBF_Req_Data 9;
BA_ "GenSigSwitchedByIgnition" SG_ 2549880577 DIA_KBF_Req_Data 0;
BA_ "GenSigSendType" SG_ 2550011649 DIA_KBF_Resp_Data 3;
BA_ "GenSigFuncType" SG_ 2550011649 DIA_KBF_Resp_Data 9;
BA_ "GenSigSwitchedByIgnition" SG_ 2550011649 DIA_KBF_Resp_Data 0;
BA_ "GenSigSendType" SG_ 2549880639 DIA_KPV_Req_Data 3;
BA_ "GenSigSwitchedByIgnition" SG_ 2549880639 DIA_KPV_Req_Data 0;
BA_ "GenSigSendType" SG_ 2550011711 DIA_KPV_Resp_Data 3;
BA_ "GenSigSwitchedByIgnition" SG_ 2550011711 DIA_KPV_Resp_Data 0;
BA_ "GenSigSendType" SG_ 2549880330 DIA_LED_LM_L_Req_Data 3;
BA_ "GenSigFuncType" SG_ 2549880330 DIA_LED_LM_L_Req_Data 9;
BA_ "GenSigSwitchedByIgnition" SG_ 2549880330 DIA_LED_LM_L_Req_Data 0;
BA_ "GenSigSendType" SG_ 2550011402 DIA_LED_LM_L_Resp_Data 3;
BA_ "GenSigFuncType" SG_ 2550011402 DIA_LED_LM_L_Resp_Data 9;
BA_ "GenSigSwitchedByIgnition" SG_ 2550011402 DIA_LED_LM_L_Resp_Data 0;
BA_ "GenSigSendType" SG_ 2549880331 DIA_LED_LM_R_Req_Data 3;
BA_ "GenSigFuncType" SG_ 2549880331 DIA_LED_LM_R_Req_Data 9;
BA_ "GenSigSwitchedByIgnition" SG_ 2549880331 DIA_LED_LM_R_Req_Data 0;
BA_ "GenSigSendType" SG_ 2550011403 DIA_LED_LM_R_Resp_Data 3;
BA_ "GenSigFuncType" SG_ 2550011403 DIA_LED_LM_R_Resp_Data 9;
BA_ "GenSigSwitchedByIgnition" SG_ 2550011403 DIA_LED_LM_R_Resp_Data 0;
BA_ "GenSigSendType" SG_ 2549880633 DIA_LIM2_Req_Data 3;
BA_ "GenSigFuncType" SG_ 2549880633 DIA_LIM2_Req_Data 9;
BA_ "GenSigSwitchedByIgnition" SG_ 2549880633 DIA_LIM2_Req_Data 0;
BA_ "GenSigSendType" SG_ 2550011705 DIA_LIM2_Resp_Data 3;
BA_ "GenSigFuncType" SG_ 2550011705 DIA_LIM2_Resp_Data 9;
BA_ "GenSigSwitchedByIgnition" SG_ 2550011705 DIA_LIM2_Resp_Data 0;
BA_ "GenSigSendType" SG_ 2549880350 DIA_LIM_Req_Data 3;
BA_ "GenSigFuncType" SG_ 2549880350 DIA_LIM_Req_Data 9;
BA_ "GenSigSwitchedByIgnition" SG_ 2549880350 DIA_LIM_Req_Data 0;
BA_ "GenSigSendType" SG_ 2550011422 DIA_LIM_Resp_Data 3;
BA_ "GenSigFuncType" SG_ 2550011422 DIA_LIM_Resp_Data 9;
BA_ "GenSigSwitchedByIgnition" SG_ 2550011422 DIA_LIM_Resp_Data 0;
BA_ "GenSigSendType" SG_ 2549880427 DIA_MXB_LM_L_Req_Data 3;
BA_ "GenSigFuncType" SG_ 2549880427 DIA_MXB_LM_L_Req_Data 9;
BA_ "GenSigSwitchedByIgnition" SG_ 2549880427 DIA_MXB_LM_L_Req_Data 0;
BA_ "GenSigSendType" SG_ 2550011499 DIA_MXB_LM_L_Resp_Data 3;
BA_ "GenSigFuncType" SG_ 2550011499 DIA_MXB_LM_L_Resp_Data 9;
BA_ "GenSigSwitchedByIgnition" SG_ 2550011499 DIA_MXB_LM_L_Resp_Data 0;
BA_ "GenSigSendType" SG_ 2549880428 DIA_MXB_LM_R_Req_Data 3;
BA_ "GenSigFuncType" SG_ 2549880428 DIA_MXB_LM_R_Req_Data 9;
BA_ "GenSigSwitchedByIgnition" SG_ 2549880428 DIA_MXB_LM_R_Req_Data 0;
BA_ "GenSigSendType" SG_ 2550011500 DIA_MXB_LM_R_Resp_Data 3;
BA_ "GenSigFuncType" SG_ 2550011500 DIA_MXB_LM_R_Resp_Data 9;
BA_ "GenSigSwitchedByIgnition" SG_ 2550011500 DIA_MXB_LM_R_Resp_Data 0;
BA_ "GenSigSendType" SG_ 2549880612 DIA_SWP_Req_Data 3;
BA_ "GenSigFuncType" SG_ 2549880612 DIA_SWP_Req_Data 9;
BA_ "GenSigSwitchedByIgnition" SG_ 2549880612 DIA_SWP_Req_Data 0;
BA_ "GenSigSendType" SG_ 2550011684 DIA_SWP_Resp_Data 3;
BA_ "GenSigFuncType" SG_ 2550011684 DIA_SWP_Resp_Data 9;
BA_ "GenSigSwitchedByIgnition" SG_ 2550011684 DIA_SWP_Resp_Data 0;
BA_ "GenSigSendType" SG_ 2549880324 DIA_UGDO_S_Req_Data 3;
BA_ "GenSigFuncType" SG_ 2549880324 DIA_UGDO_S_Req_Data 9;
BA_ "GenSigSwitchedByIgnition" SG_ 2549880324 DIA_UGDO_S_Req_Data 0;
BA_ "GenSigSendType" SG_ 2550011396 DIA_UGDO_S_Resp_Data 3;
BA_ "GenSigFuncType" SG_ 2550011396 DIA_UGDO_S_Resp_Data 9;
BA_ "GenSigSwitchedByIgnition" SG_ 2550011396 DIA_UGDO_S_Resp_Data 0;
BA_ "GenSigSendType" SG_ 2549880321 DIA_WWS_Req_Data 3;
BA_ "GenSigFuncType" SG_ 2549880321 DIA_WWS_Req_Data 9;
BA_ "GenSigSwitchedByIgnition" SG_ 2549880321 DIA_WWS_Req_Data 0;
BA_ "GenSigSendType" SG_ 2550011393 DIA_WWS_Resp_Data 3;
BA_ "GenSigFuncType" SG_ 2550011393 DIA_WWS_Resp_Data 9;
BA_ "GenSigSwitchedByIgnition" SG_ 2550011393 DIA_WWS_Resp_Data 0;
BA_ "GenSigSendType" SG_ 1714 DGN_Verlernzaehler 0;
BA_ "GenSigSwitchedByIgnition" SG_ 1714 DGN_Verlernzaehler 0;
BA_ "GenSigSendType" SG_ 1714 KBI_Kilometerstand 0;
BA_ "GenSigStartValue" SG_ 1714 KBI_Kilometerstand 1048574;
BA_ "GenSigSwitchedByIgnition" SG_ 1714 KBI_Kilometerstand 0;
BA_ "Fehlerwert" SG_ 1714 KBI_Kilometerstand 1048575;
BA_ "GenSigSendType" SG_ 1714 Kombi_02_alt 0;
BA_ "GenSigStartValue" SG_ 1714 Kombi_02_alt 1;
BA_ "GenSigFuncType" SG_ 1714 Kombi_02_alt 5;
BA_ "GenSigSwitchedByIgnition" SG_ 1714 Kombi_02_alt 0;
BA_ "GenSigSendType" SG_ 1714 UH_Jahr 0;
BA_ "GenSigSwitchedByIgnition" SG_ 1714 UH_Jahr 0;
BA_ "GenSigSendType" SG_ 1714 UH_Minute 0;
BA_ "GenSigSwitchedByIgnition" SG_ 1714 UH_Minute 0;
BA_ "GenSigSendType" SG_ 1714 UH_Monat 0;
BA_ "GenSigSwitchedByIgnition" SG_ 1714 UH_Monat 0;
BA_ "Fehlerwert" SG_ 1714 UH_Monat 15;
BA_ "GenSigSendType" SG_ 1714 UH_Sekunde 0;
BA_ "GenSigSwitchedByIgnition" SG_ 1714 UH_Sekunde 0;
BA_ "GenSigSendType" SG_ 1714 UH_Stunde 0;
BA_ "GenSigSwitchedByIgnition" SG_ 1714 UH_Stunde 0;
BA_ "GenSigSendType" SG_ 1714 UH_Tag 0;
BA_ "GenSigSwitchedByIgnition" SG_ 1714 UH_Tag 0;
BA_ "GenSigSendType" SG_ 1714 Uhrzeit_01_alt 0;
BA_ "GenSigStartValue" SG_ 1714 Uhrzeit_01_alt 1;
BA_ "GenSigFuncType" SG_ 1714 Uhrzeit_01_alt 5;
BA_ "GenSigSwitchedByIgnition" SG_ 1714 Uhrzeit_01_alt 0;
BA_ "GenSigSendType" SG_ 1520 BCM1_Stellgroesse_Kl_58s 3;
BA_ "GenSigStartValue" SG_ 1520 BCM1_Stellgroesse_Kl_58s 126;
BA_ "GenSigSwitchedByIgnition" SG_ 1520 BCM1_Stellgroesse_Kl_58s 0;
BA_ "Fehlerwert" SG_ 1520 BCM1_Stellgroesse_Kl_58s 127;
BA_ "GenSigSendType" SG_ 1520 DI_Display_Nachtdesign 3;
BA_ "GenSigSwitchedByIgnition" SG_ 1520 DI_Display_Nachtdesign 0;
BA_ "GenSigSendType" SG_ 1520 DI_Fotosensor 3;
BA_ "GenSigSwitchedByIgnition" SG_ 1520 DI_Fotosensor 0;
BA_ "GenSigSendType" SG_ 1520 DI_KL_58xd 3;
BA_ "GenSigStartValue" SG_ 1520 DI_KL_58xd 254;
BA_ "GenSigSwitchedByIgnition" SG_ 1520 DI_KL_58xd 0;
BA_ "Fehlerwert" SG_ 1520 DI_KL_58xd 255;
BA_ "GenSigSendType" SG_ 1520 DI_KL_58xs 3;
BA_ "GenSigStartValue" SG_ 1520 DI_KL_58xs 126;
BA_ "GenSigSwitchedByIgnition" SG_ 1520 DI_KL_58xs 0;
BA_ "Fehlerwert" SG_ 1520 DI_KL_58xs 127;
BA_ "GenSigSendType" SG_ 1520 DI_KL_58xt 3;
BA_ "GenSigStartValue" SG_ 1520 DI_KL_58xt 126;
BA_ "GenSigSwitchedByIgnition" SG_ 1520 DI_KL_58xt 0;
BA_ "Fehlerwert" SG_ 1520 DI_KL_58xt 127;
BA_ "GenSigSendType" SG_ 420 EA_01_BZ 0;
BA_ "GenSigFuncType" SG_ 420 EA_01_BZ 1;
BA_ "GenSigSendType" SG_ 420 EA_01_CRC 0;
BA_ "GenSigFuncType" SG_ 420 EA_01_CRC 2;
BA_ "GenSigSendType" SG_ 420 EA_Anforderung_HMS 0;
BA_ "GenSigSendType" SG_ 420 EA_eCall_Anf 0;
BA_ "GenSigSwitchedByIgnition" SG_ 420 EA_eCall_Anf 0;
BA_ "GenSigSendType" SG_ 420 EA_Funktionsstatus 0;
BA_ "GenSigSendType" SG_ 420 EA_Gurtstraffer_Anf 0;
BA_ "GenSigSendType" SG_ 420 EA_Parken_beibehalten_HMS 0;
BA_ "GenSigStartValue" SG_ 420 EA_Parken_beibehalten_HMS 2;
BA_ "Fehlerwert" SG_ 420 EA_Parken_beibehalten_HMS 3;
BA_ "GenSigSendType" SG_ 420 EA_Sollbeschleunigung 0;
BA_ "GenSigStartValue" SG_ 420 EA_Sollbeschleunigung 2046;
BA_ "Fehlerwert" SG_ 420 EA_Sollbeschleunigung 2047;
BA_ "GenSigSendType" SG_ 420 EA_Warnruckprofil 0;
BA_ "GenSigSendType" SG_ 496 ACF_Lampe_Hands_Off 3;
BA_ "GenSigSwitchedByIgnition" SG_ 496 ACF_Lampe_Hands_Off 0;
BA_ "GenSigSendType" SG_ 496 EA_02_BZ 0;
BA_ "GenSigFuncType" SG_ 496 EA_02_BZ 1;
BA_ "GenSigSendType" SG_ 496 EA_02_CRC 0;
BA_ "GenSigFuncType" SG_ 496 EA_02_CRC 2;
BA_ "GenSigSendType" SG_ 496 EA_Blinken 3;
BA_ "GenSigSendType" SG_ 496 EA_Bremslichtblinken 3;
BA_ "GenSigSendType" SG_ 496 EA_Infotainment_Anf 3;
BA_ "GenSigSendType" SG_ 496 EA_Innenraumlicht_Anf 3;
BA_ "GenSigSendType" SG_ 496 EA_Texte 3;
BA_ "GenSigSendType" SG_ 496 EA_Tueren_Anf 3;
BA_ "GenSigSendType" SG_ 496 STP_Primaeranz 3;
BA_ "GenSigSendType" SG_ 496 zFAS_Warnblinken 3;
BA_ "GenSigSendType" SG_ 2527679980 bCall_active 3;
BA_ "GenSigSwitchedByIgnition" SG_ 2527679980 bCall_active 0;
BA_ "GenSigSendType" SG_ 2527679980 eCall_Funktionsstatus 3;
BA_ "GenSigSwitchedByIgnition" SG_ 2527679980 eCall_Funktionsstatus 0;
BA_ "GenSigSendType" SG_ 2527679980 eCall_Funktionsstatus_02 3;
BA_ "GenSigStartValue" SG_ 2527679980 eCall_Funktionsstatus_02 7;
BA_ "GenSigSwitchedByIgnition" SG_ 2527679980 eCall_Funktionsstatus_02 0;
BA_ "GenSigSendType" SG_ 2527679980 eCall_Statuslicht_Farbe1 3;
BA_ "GenSigSwitchedByIgnition" SG_ 2527679980 eCall_Statuslicht_Farbe1 0;
BA_ "GenSigSendType" SG_ 2527679980 eCall_Statuslicht_Farbe2 3;
BA_ "GenSigSwitchedByIgnition" SG_ 2527679980 eCall_Statuslicht_Farbe2 0;
BA_ "GenSigSendType" SG_ 2527679980 eCall_Subscription 3;
BA_ "GenSigSwitchedByIgnition" SG_ 2527679980 eCall_Subscription 0;
BA_ "GenSigSendType" SG_ 1603 KBI_Einheit_Datum 3;
BA_ "GenSigSwitchedByIgnition" SG_ 1603 KBI_Einheit_Datum 0;
BA_ "GenSigSendType" SG_ 1603 KBI_Einheit_Druck 3;
BA_ "GenSigSwitchedByIgnition" SG_ 1603 KBI_Einheit_Druck 0;
BA_ "GenSigSendType" SG_ 1603 KBI_Einheit_Masse 3;
BA_ "GenSigSwitchedByIgnition" SG_ 1603 KBI_Einheit_Masse 0;
BA_ "GenSigSendType" SG_ 1603 KBI_Einheit_Sprache 3;
BA_ "GenSigSwitchedByIgnition" SG_ 1603 KBI_Einheit_Sprache 0;
BA_ "GenSigSendType" SG_ 1603 KBI_Einheit_Streckenanz 3;
BA_ "GenSigSwitchedByIgnition" SG_ 1603 KBI_Einheit_Streckenanz 0;
BA_ "GenSigSendType" SG_ 1603 KBI_Einheit_Temp 3;
BA_ "GenSigSwitchedByIgnition" SG_ 1603 KBI_Einheit_Temp 0;
BA_ "GenSigSendType" SG_ 1603 KBI_Einheit_Uhrzeit 3;
BA_ "GenSigSwitchedByIgnition" SG_ 1603 KBI_Einheit_Uhrzeit 0;
BA_ "GenSigSendType" SG_ 1603 KBI_Einheit_Verbrauch 3;
BA_ "GenSigSwitchedByIgnition" SG_ 1603 KBI_Einheit_Verbrauch 0;
BA_ "GenSigSendType" SG_ 1603 KBI_Einheit_Verbrauch_elektr 3;
BA_ "GenSigSwitchedByIgnition" SG_ 1603 KBI_Einheit_Verbrauch_elektr 0;
BA_ "GenSigSendType" SG_ 1603 KBI_Einheit_Verbrauch_Gas 3;
BA_ "GenSigSwitchedByIgnition" SG_ 1603 KBI_Einheit_Verbrauch_Gas 0;
BA_ "GenSigSendType" SG_ 1603 KBI_Einheit_Volumen 3;
BA_ "GenSigSwitchedByIgnition" SG_ 1603 KBI_Einheit_Volumen 0;
BA_ "GenSigSendType" SG_ 1603 KBI_MFA_v_Einheit_02 3;
BA_ "GenSigSwitchedByIgnition" SG_ 1603 KBI_MFA_v_Einheit_02 0;
BA_ "GenSigSendType" SG_ 260 EPB_01_BZ 0;
BA_ "GenSigFuncType" SG_ 260 EPB_01_BZ 1;
BA_ "GenSigSwitchedByIgnition" SG_ 260 EPB_01_BZ 0;
BA_ "GenSigSendType" SG_ 260 EPB_01_CRC 0;
BA_ "GenSigFuncType" SG_ 260 EPB_01_CRC 2;
BA_ "GenSigSwitchedByIgnition" SG_ 260 EPB_01_CRC 0;
BA_ "GenSigSendType" SG_ 260 EPB_DAA_Randbed_erf 0;
BA_ "GenSigSwitchedByIgnition" SG_ 260 EPB_DAA_Randbed_erf 0;
BA_ "GenSigSendType" SG_ 260 EPB_Fehlerstatus_02 3;
BA_ "GenSigSwitchedByIgnition" SG_ 260 EPB_Fehlerstatus_02 0;
BA_ "GenSigSendType" SG_ 260 EPB_Freig_Verzoeg_Anf 0;
BA_ "GenSigSwitchedByIgnition" SG_ 260 EPB_Freig_Verzoeg_Anf 0;
BA_ "GenSigSendType" SG_ 260 EPB_Pedalweg_Kuppl 3;
BA_ "GenSigSwitchedByIgnition" SG_ 260 EPB_Pedalweg_Kuppl 0;
BA_ "Fehlerwert" SG_ 260 EPB_Pedalweg_Kuppl 255;
BA_ "GenSigSendType" SG_ 260 EPB_QBit_Pedalweg_Kuppl 3;
BA_ "GenSigStartValue" SG_ 260 EPB_QBit_Pedalweg_Kuppl 1;
BA_ "GenSigSwitchedByIgnition" SG_ 260 EPB_QBit_Pedalweg_Kuppl 0;
BA_ "GenSigSendType" SG_ 260 EPB_QBit_Schalterpos 0;
BA_ "GenSigStartValue" SG_ 260 EPB_QBit_Schalterpos 1;
BA_ "GenSigSwitchedByIgnition" SG_ 260 EPB_QBit_Schalterpos 0;
BA_ "GenSigSendType" SG_ 260 EPB_Schalterposition 0;
BA_ "GenSigSwitchedByIgnition" SG_ 260 EPB_Schalterposition 0;
BA_ "Fehlerwert" SG_ 260 EPB_Schalterposition 3;
BA_ "GenSigSendType" SG_ 260 EPB_Spannkraft 0;
BA_ "GenSigStartValue" SG_ 260 EPB_Spannkraft 30;
BA_ "GenSigSwitchedByIgnition" SG_ 260 EPB_Spannkraft 0;
BA_ "Fehlerwert" SG_ 260 EPB_Spannkraft 31;
BA_ "GenSigSendType" SG_ 260 EPB_Status_02 3;
BA_ "GenSigStartValue" SG_ 260 EPB_Status_02 6;
BA_ "GenSigSwitchedByIgnition" SG_ 260 EPB_Status_02 0;
BA_ "GenSigSendType" SG_ 260 EPB_Verzoeg_Anf 0;
BA_ "GenSigStartValue" SG_ 260 EPB_Verzoeg_Anf 166;
BA_ "GenSigSwitchedByIgnition" SG_ 260 EPB_Verzoeg_Anf 0;
BA_ "GenSigSendType" SG_ 259 ESP_03_BZ 0;
BA_ "GenSigFuncType" SG_ 259 ESP_03_BZ 1;
BA_ "GenSigSwitchedByIgnition" SG_ 259 ESP_03_BZ 0;
BA_ "GenSigSendType" SG_ 259 ESP_03_CRC 0;
BA_ "GenSigFuncType" SG_ 259 ESP_03_CRC 2;
BA_ "GenSigSwitchedByIgnition" SG_ 259 ESP_03_CRC 0;
BA_ "GenSigSendType" SG_ 259 ESP_HL_FR 0;
BA_ "GenSigSwitchedByIgnition" SG_ 259 ESP_HL_FR 0;
BA_ "GenSigSendType" SG_ 259 ESP_HL_Radgeschw 0;
BA_ "GenSigStartValue" SG_ 259 ESP_HL_Radgeschw 4094;
BA_ "GenSigSwitchedByIgnition" SG_ 259 ESP_HL_Radgeschw 0;
BA_ "Fehlerwert" SG_ 259 ESP_HL_Radgeschw 4095;
BA_ "GenSigSendType" SG_ 259 ESP_HR_FR 0;
BA_ "GenSigSwitchedByIgnition" SG_ 259 ESP_HR_FR 0;
BA_ "GenSigSendType" SG_ 259 ESP_HR_Radgeschw 0;
BA_ "GenSigStartValue" SG_ 259 ESP_HR_Radgeschw 4094;
BA_ "GenSigSwitchedByIgnition" SG_ 259 ESP_HR_Radgeschw 0;
BA_ "Fehlerwert" SG_ 259 ESP_HR_Radgeschw 4095;
BA_ "GenSigSendType" SG_ 259 ESP_VL_FR 0;
BA_ "GenSigSwitchedByIgnition" SG_ 259 ESP_VL_FR 0;
BA_ "GenSigSendType" SG_ 259 ESP_VL_Radgeschw 0;
BA_ "GenSigStartValue" SG_ 259 ESP_VL_Radgeschw 4094;
BA_ "GenSigSwitchedByIgnition" SG_ 259 ESP_VL_Radgeschw 0;
BA_ "Fehlerwert" SG_ 259 ESP_VL_Radgeschw 4095;
BA_ "GenSigSendType" SG_ 259 ESP_VR_FR 0;
BA_ "GenSigSwitchedByIgnition" SG_ 259 ESP_VR_FR 0;
BA_ "GenSigSendType" SG_ 259 ESP_VR_Radgeschw 0;
BA_ "GenSigStartValue" SG_ 259 ESP_VR_Radgeschw 4094;
BA_ "GenSigSwitchedByIgnition" SG_ 259 ESP_VR_Radgeschw 0;
BA_ "Fehlerwert" SG_ 259 ESP_VR_Radgeschw 4095;
BA_ "GenSigSendType" SG_ 914 ESC_cAQP_Trigger 0;
BA_ "GenSigSendType" SG_ 914 ESP_07_BZ 0;
BA_ "GenSigFuncType" SG_ 914 ESP_07_BZ 1;
BA_ "GenSigSwitchedByIgnition" SG_ 914 ESP_07_BZ 0;
BA_ "GenSigSendType" SG_ 914 ESP_07_CRC 0;
BA_ "GenSigFuncType" SG_ 914 ESP_07_CRC 2;
BA_ "GenSigSwitchedByIgnition" SG_ 914 ESP_07_CRC 0;
BA_ "GenSigSendType" SG_ 914 ESP_Allrad_Antrieb 0;
BA_ "GenSigFuncType" SG_ 914 ESP_Allrad_Antrieb 8;
BA_ "GenSigSwitchedByIgnition" SG_ 914 ESP_Allrad_Antrieb 0;
BA_ "GenSigSendType" SG_ 914 ESP_Codierung_ADS 0;
BA_ "GenSigFuncType" SG_ 914 ESP_Codierung_ADS 8;
BA_ "GenSigSwitchedByIgnition" SG_ 914 ESP_Codierung_ADS 0;
BA_ "GenSigSendType" SG_ 914 ESP_MKB_ausloesbar 0;
BA_ "GenSigSwitchedByIgnition" SG_ 914 ESP_MKB_ausloesbar 0;
BA_ "GenSigSendType" SG_ 914 ESP_nachtr_Stopp_Anf 0;
BA_ "GenSigSwitchedByIgnition" SG_ 914 ESP_nachtr_Stopp_Anf 0;
BA_ "GenSigSendType" SG_ 914 ESP_OBD_Status 0;
BA_ "GenSigSwitchedByIgnition" SG_ 914 ESP_OBD_Status 0;
BA_ "GenSigSendType" SG_ 914 ESP_Offroad_Modus 0;
BA_ "GenSigSwitchedByIgnition" SG_ 914 ESP_Offroad_Modus 0;
BA_ "GenSigSendType" SG_ 914 ESP_Qualifizierung_Antriebsart 0;
BA_ "GenSigFuncType" SG_ 914 ESP_Qualifizierung_Antriebsart 8;
BA_ "GenSigSwitchedByIgnition" SG_ 914 ESP_Qualifizierung_Antriebsart 0;
BA_ "GenSigSendType" SG_ 914 ESP_Rollenmodus_Deaktivieren 0;
BA_ "GenSigSwitchedByIgnition" SG_ 914 ESP_Rollenmodus_Deaktivieren 0;
BA_ "GenSigSendType" SG_ 914 ESP_RTA_HL 0;
BA_ "GenSigStartValue" SG_ 914 ESP_RTA_HL 254;
BA_ "GenSigSwitchedByIgnition" SG_ 914 ESP_RTA_HL 0;
BA_ "Fehlerwert" SG_ 914 ESP_RTA_HL 255;
BA_ "GenSigSendType" SG_ 914 ESP_RTA_HR 0;
BA_ "GenSigStartValue" SG_ 914 ESP_RTA_HR 254;
BA_ "GenSigSwitchedByIgnition" SG_ 914 ESP_RTA_HR 0;
BA_ "Fehlerwert" SG_ 914 ESP_RTA_HR 255;
BA_ "GenSigSendType" SG_ 914 ESP_RTA_VR 0;
BA_ "GenSigStartValue" SG_ 914 ESP_RTA_VR 254;
BA_ "GenSigSwitchedByIgnition" SG_ 914 ESP_RTA_VR 0;
BA_ "Fehlerwert" SG_ 914 ESP_RTA_VR 255;
BA_ "GenSigSendType" SG_ 914 ESP_Stat_FallBack_eBKV 0;
BA_ "GenSigSwitchedByIgnition" SG_ 914 ESP_Stat_FallBack_eBKV 0;
BA_ "GenSigSendType" SG_ 914 OBD_Fehler_Radsensor_HL 0;
BA_ "GenSigSwitchedByIgnition" SG_ 914 OBD_Fehler_Radsensor_HL 0;
BA_ "GenSigSendType" SG_ 914 OBD_Fehler_Radsensor_HR 0;
BA_ "GenSigSwitchedByIgnition" SG_ 914 OBD_Fehler_Radsensor_HR 0;
BA_ "GenSigSendType" SG_ 914 OBD_Fehler_Radsensor_VL 0;
BA_ "GenSigSwitchedByIgnition" SG_ 914 OBD_Fehler_Radsensor_VL 0;
BA_ "GenSigSendType" SG_ 914 OBD_Fehler_Radsensor_VR 0;
BA_ "GenSigSwitchedByIgnition" SG_ 914 OBD_Fehler_Radsensor_VR 0;
BA_ "GenSigSendType" SG_ 278 ESP_10_BZ 0;
BA_ "GenSigFuncType" SG_ 278 ESP_10_BZ 1;
BA_ "GenSigSwitchedByIgnition" SG_ 278 ESP_10_BZ 0;
BA_ "GenSigSendType" SG_ 278 ESP_10_CRC 0;
BA_ "GenSigFuncType" SG_ 278 ESP_10_CRC 2;
BA_ "GenSigSwitchedByIgnition" SG_ 278 ESP_10_CRC 0;
BA_ "GenSigSendType" SG_ 278 ESP_HL_Fahrtrichtung 0;
BA_ "GenSigStartValue" SG_ 278 ESP_HL_Fahrtrichtung 2;
BA_ "GenSigSwitchedByIgnition" SG_ 278 ESP_HL_Fahrtrichtung 0;
BA_ "GenSigSendType" SG_ 278 ESP_HR_Fahrtrichtung 0;
BA_ "GenSigStartValue" SG_ 278 ESP_HR_Fahrtrichtung 2;
BA_ "GenSigSwitchedByIgnition" SG_ 278 ESP_HR_Fahrtrichtung 0;
BA_ "GenSigSendType" SG_ 278 ESP_QBit_Wegimpuls_HL 0;
BA_ "GenSigStartValue" SG_ 278 ESP_QBit_Wegimpuls_HL 1;
BA_ "GenSigSwitchedByIgnition" SG_ 278 ESP_QBit_Wegimpuls_HL 0;
BA_ "GenSigSendType" SG_ 278 ESP_QBit_Wegimpuls_HR 0;
BA_ "GenSigStartValue" SG_ 278 ESP_QBit_Wegimpuls_HR 1;
BA_ "GenSigSwitchedByIgnition" SG_ 278 ESP_QBit_Wegimpuls_HR 0;
BA_ "GenSigSendType" SG_ 278 ESP_QBit_Wegimpuls_VL 0;
BA_ "GenSigStartValue" SG_ 278 ESP_QBit_Wegimpuls_VL 1;
BA_ "GenSigSwitchedByIgnition" SG_ 278 ESP_QBit_Wegimpuls_VL 0;
BA_ "GenSigSendType" SG_ 278 ESP_QBit_Wegimpuls_VR 0;
BA_ "GenSigStartValue" SG_ 278 ESP_QBit_Wegimpuls_VR 1;
BA_ "GenSigSwitchedByIgnition" SG_ 278 ESP_QBit_Wegimpuls_VR 0;
BA_ "GenSigSendType" SG_ 278 ESP_VL_Fahrtrichtung 0;
BA_ "GenSigStartValue" SG_ 278 ESP_VL_Fahrtrichtung 2;
BA_ "GenSigSwitchedByIgnition" SG_ 278 ESP_VL_Fahrtrichtung 0;
BA_ "GenSigSendType" SG_ 278 ESP_VR_Fahrtrichtung 0;
BA_ "GenSigStartValue" SG_ 278 ESP_VR_Fahrtrichtung 2;
BA_ "GenSigSwitchedByIgnition" SG_ 278 ESP_VR_Fahrtrichtung 0;
BA_ "GenSigSendType" SG_ 278 ESP_Wegimpuls_HL 0;
BA_ "GenSigStartValue" SG_ 278 ESP_Wegimpuls_HL 1021;
BA_ "GenSigSwitchedByIgnition" SG_ 278 ESP_Wegimpuls_HL 0;
BA_ "Fehlerwert" SG_ 278 ESP_Wegimpuls_HL 1023;
BA_ "GenSigSendType" SG_ 278 ESP_Wegimpuls_HR 0;
BA_ "GenSigStartValue" SG_ 278 ESP_Wegimpuls_HR 1021;
BA_ "GenSigSwitchedByIgnition" SG_ 278 ESP_Wegimpuls_HR 0;
BA_ "Fehlerwert" SG_ 278 ESP_Wegimpuls_HR 1023;
BA_ "GenSigSendType" SG_ 278 ESP_Wegimpuls_VL 0;
BA_ "GenSigStartValue" SG_ 278 ESP_Wegimpuls_VL 1021;
BA_ "GenSigSwitchedByIgnition" SG_ 278 ESP_Wegimpuls_VL 0;
BA_ "Fehlerwert" SG_ 278 ESP_Wegimpuls_VL 1023;
BA_ "GenSigSendType" SG_ 278 ESP_Wegimpuls_VR 0;
BA_ "GenSigStartValue" SG_ 278 ESP_Wegimpuls_VR 1021;
BA_ "GenSigSwitchedByIgnition" SG_ 278 ESP_Wegimpuls_VR 0;
BA_ "Fehlerwert" SG_ 278 ESP_Wegimpuls_VR 1023;
BA_ "GenSigSendType" SG_ 418 ESP_15_BZ 0;
BA_ "GenSigFuncType" SG_ 418 ESP_15_BZ 1;
BA_ "GenSigSwitchedByIgnition" SG_ 418 ESP_15_BZ 0;
BA_ "GenSigSendType" SG_ 418 ESP_15_CRC 0;
BA_ "GenSigFuncType" SG_ 418 ESP_15_CRC 2;
BA_ "GenSigSwitchedByIgnition" SG_ 418 ESP_15_CRC 0;
BA_ "GenSigSendType" SG_ 418 ESP_Haltemoment 0;
BA_ "GenSigStartValue" SG_ 418 ESP_Haltemoment 1022;
BA_ "GenSigSwitchedByIgnition" SG_ 418 ESP_Haltemoment 0;
BA_ "Fehlerwert" SG_ 418 ESP_Haltemoment 1023;
BA_ "GenSigSendType" SG_ 418 ESP_Index_Haltemoment 0;
BA_ "GenSigSwitchedByIgnition" SG_ 418 ESP_Index_Haltemoment 0;
BA_ "GenSigSendType" SG_ 418 HMS_aktives_System 3;
BA_ "GenSigSwitchedByIgnition" SG_ 418 HMS_aktives_System 0;
BA_ "GenSigSendType" SG_ 418 HMS_Anforderung_GE 0;
BA_ "GenSigSwitchedByIgnition" SG_ 418 HMS_Anforderung_GE 0;
BA_ "GenSigSendType" SG_ 418 HMS_Fehlerstatus 3;
BA_ "GenSigSwitchedByIgnition" SG_ 418 HMS_Fehlerstatus 0;
BA_ "GenSigSendType" SG_ 418 HMS_halten_nicht_verfuegbar 0;
BA_ "GenSigSwitchedByIgnition" SG_ 418 HMS_halten_nicht_verfuegbar 0;
BA_ "GenSigSendType" SG_ 418 HMS_Konsistenz_ACC 0;
BA_ "GenSigSwitchedByIgnition" SG_ 418 HMS_Konsistenz_ACC 0;
BA_ "GenSigSendType" SG_ 418 HMS_Konsistenz_GE 0;
BA_ "GenSigSwitchedByIgnition" SG_ 418 HMS_Konsistenz_GE 0;
BA_ "GenSigSendType" SG_ 418 HMS_Konsistenz_HVLM 3;
BA_ "GenSigSwitchedByIgnition" SG_ 418 HMS_Konsistenz_HVLM 0;
BA_ "GenSigSendType" SG_ 418 HMS_Konsistenz_IPA 3;
BA_ "GenSigSwitchedByIgnition" SG_ 418 HMS_Konsistenz_IPA 0;
BA_ "GenSigSendType" SG_ 418 HMS_Konsistenz_MO 0;
BA_ "GenSigSwitchedByIgnition" SG_ 418 HMS_Konsistenz_MO 0;
BA_ "GenSigSendType" SG_ 418 HMS_Konsistenz_STA 0;
BA_ "GenSigSwitchedByIgnition" SG_ 418 HMS_Konsistenz_STA 0;
BA_ "GenSigSendType" SG_ 418 HMS_Notstopp_Status 0;
BA_ "GenSigSwitchedByIgnition" SG_ 418 HMS_Notstopp_Status 0;
BA_ "GenSigSendType" SG_ 418 HMS_P_beibehalten_GE 0;
BA_ "GenSigStartValue" SG_ 418 HMS_P_beibehalten_GE 2;
BA_ "GenSigSwitchedByIgnition" SG_ 418 HMS_P_beibehalten_GE 0;
BA_ "Fehlerwert" SG_ 418 HMS_P_beibehalten_GE 3;
BA_ "GenSigSendType" SG_ 418 HMS_parken_nicht_verfuegbar 0;
BA_ "GenSigSwitchedByIgnition" SG_ 418 HMS_parken_nicht_verfuegbar 0;
BA_ "GenSigSendType" SG_ 418 HMS_Stillstand 3;
BA_ "GenSigStartValue" SG_ 418 HMS_Stillstand 6;
BA_ "GenSigSwitchedByIgnition" SG_ 418 HMS_Stillstand 0;
BA_ "Fehlerwert" SG_ 418 HMS_Stillstand 7;
BA_ "GenSigSendType" SG_ 418 HMS_Systemstatus 3;
BA_ "GenSigStartValue" SG_ 418 HMS_Systemstatus 14;
BA_ "GenSigSwitchedByIgnition" SG_ 418 HMS_Systemstatus 0;
BA_ "Fehlerwert" SG_ 418 HMS_Systemstatus 15;
BA_ "GenSigSendType" SG_ 418 NL_PRIM_STP_01_Status 0;
BA_ "GenSigSwitchedByIgnition" SG_ 418 NL_PRIM_STP_01_Status 0;
BA_ "GenSigSendType" SG_ 418 VMM_Warnblinken 3;
BA_ "GenSigSwitchedByIgnition" SG_ 418 VMM_Warnblinken 0;
BA_ "GenSigSendType" SG_ 418 VZM_Status 0;
BA_ "GenSigSwitchedByIgnition" SG_ 418 VZM_Status 0;
BA_ "Fehlerwert" SG_ 418 VZM_Status 4;
BA_ "GenSigSendType" SG_ 253 ABS_Bremsung 0;
BA_ "GenSigSwitchedByIgnition" SG_ 253 ABS_Bremsung 0;
BA_ "GenSigSendType" SG_ 253 ASR_Anf 0;
BA_ "GenSigSwitchedByIgnition" SG_ 253 ASR_Anf 0;
BA_ "GenSigSendType" SG_ 253 ASR_Schalteingriff 0;
BA_ "GenSigSwitchedByIgnition" SG_ 253 ASR_Schalteingriff 0;
BA_ "GenSigSendType" SG_ 253 ASR_Tastung_passiv 0;
BA_ "GenSigSwitchedByIgnition" SG_ 253 ASR_Tastung_passiv 0;
BA_ "GenSigSendType" SG_ 253 BR_Eingriffsmoment 0;
BA_ "GenSigStartValue" SG_ 253 BR_Eingriffsmoment 1022;
BA_ "GenSigSwitchedByIgnition" SG_ 253 BR_Eingriffsmoment 0;
BA_ "Fehlerwert" SG_ 253 BR_Eingriffsmoment 1023;
BA_ "GenSigSendType" SG_ 253 EBV_Eingriff 0;
BA_ "GenSigSwitchedByIgnition" SG_ 253 EBV_Eingriff 0;
BA_ "GenSigSendType" SG_ 253 EDS_Eingriff 0;
BA_ "GenSigSwitchedByIgnition" SG_ 253 EDS_Eingriff 0;
BA_ "GenSigSendType" SG_ 253 ESC_Neutralschaltung 0;
BA_ "GenSigSwitchedByIgnition" SG_ 253 ESC_Neutralschaltung 0;
BA_ "GenSigSendType" SG_ 253 ESC_v_Signal_Qualifier_High_Low 0;
BA_ "GenSigStartValue" SG_ 253 ESC_v_Signal_Qualifier_High_Low 6;
BA_ "GenSigSwitchedByIgnition" SG_ 253 ESC_v_Signal_Qualifier_High_Low 0;
BA_ "Fehlerwert" SG_ 253 ESC_v_Signal_Qualifier_High_Low 7;
BA_ "GenSigSendType" SG_ 253 ESP_21_BZ 0;
BA_ "GenSigFuncType" SG_ 253 ESP_21_BZ 1;
BA_ "GenSigSwitchedByIgnition" SG_ 253 ESP_21_BZ 0;
BA_ "GenSigSendType" SG_ 253 ESP_21_CRC 0;
BA_ "GenSigFuncType" SG_ 253 ESP_21_CRC 2;
BA_ "GenSigSwitchedByIgnition" SG_ 253 ESP_21_CRC 0;
BA_ "GenSigSendType" SG_ 253 ESP_ASP 0;
BA_ "GenSigSwitchedByIgnition" SG_ 253 ESP_ASP 0;
BA_ "GenSigSendType" SG_ 253 ESP_Diagnose 0;
BA_ "GenSigSwitchedByIgnition" SG_ 253 ESP_Diagnose 0;
BA_ "GenSigSendType" SG_ 253 ESP_Eingriff 0;
BA_ "GenSigSwitchedByIgnition" SG_ 253 ESP_Eingriff 0;
BA_ "GenSigSendType" SG_ 253 ESP_QBit_v_Signal 0;
BA_ "GenSigStartValue" SG_ 253 ESP_QBit_v_Signal 1;
BA_ "GenSigSwitchedByIgnition" SG_ 253 ESP_QBit_v_Signal 0;
BA_ "GenSigSendType" SG_ 253 ESP_Systemstatus 0;
BA_ "GenSigSwitchedByIgnition" SG_ 253 ESP_Systemstatus 0;
BA_ "GenSigSendType" SG_ 253 ESP_Tastung_passiv 0;
BA_ "GenSigSwitchedByIgnition" SG_ 253 ESP_Tastung_passiv 0;
BA_ "GenSigSendType" SG_ 253 ESP_v_Signal 0;
BA_ "GenSigStartValue" SG_ 253 ESP_v_Signal 65534;
BA_ "GenSigSwitchedByIgnition" SG_ 253 ESP_v_Signal 0;
BA_ "Fehlerwert" SG_ 253 ESP_v_Signal 65535;
BA_ "GenSigMissingSourceValue" SG_ 253 ESP_v_Signal 65534;
BA_ "GenSigSendType" SG_ 253 ESP_Vorsteuerung 0;
BA_ "GenSigSwitchedByIgnition" SG_ 253 ESP_Vorsteuerung 0;
BA_ "GenSigSendType" SG_ 253 MSR_Anf 0;
BA_ "GenSigSwitchedByIgnition" SG_ 253 MSR_Anf 0;
BA_ "GenSigSendType" SG_ 253 OBD_QBit_Schlechtweg 0;
BA_ "GenSigStartValue" SG_ 253 OBD_QBit_Schlechtweg 1;
BA_ "GenSigSwitchedByIgnition" SG_ 253 OBD_QBit_Schlechtweg 0;
BA_ "GenSigSendType" SG_ 253 OBD_Schlechtweg 0;
BA_ "GenSigSwitchedByIgnition" SG_ 253 OBD_Schlechtweg 0;
BA_ "GenSigSendType" SG_ 1470 BR_QBit_Reifenumfang_sekundaer 0;
BA_ "GenSigStartValue" SG_ 1470 BR_QBit_Reifenumfang_sekundaer 1;
BA_ "GenSigSwitchedByIgnition" SG_ 1470 BR_QBit_Reifenumfang_sekundaer 0;
BA_ "GenSigSendType" SG_ 1470 BR_Reifenumfang_sekundaer 0;
BA_ "GenSigSwitchedByIgnition" SG_ 1470 BR_Reifenumfang_sekundaer 0;
BA_ "GenSigSendType" SG_ 1470 ESP_23_BZ 0;
BA_ "GenSigFuncType" SG_ 1470 ESP_23_BZ 1;
BA_ "GenSigSwitchedByIgnition" SG_ 1470 ESP_23_BZ 0;
BA_ "GenSigSendType" SG_ 1470 ESP_23_CRC 0;
BA_ "GenSigFuncType" SG_ 1470 ESP_23_CRC 2;
BA_ "GenSigSwitchedByIgnition" SG_ 1470 ESP_23_CRC 0;
BA_ "GenSigSendType" SG_ 1470 ESP_Gierrate_Offset_2 0;
BA_ "GenSigStartValue" SG_ 1470 ESP_Gierrate_Offset_2 2046;
BA_ "GenSigSwitchedByIgnition" SG_ 1470 ESP_Gierrate_Offset_2 0;
BA_ "Fehlerwert" SG_ 1470 ESP_Gierrate_Offset_2 2047;
BA_ "GenSigSendType" SG_ 1470 ESP_Laengsbeschleunigung_Offset 0;
BA_ "GenSigStartValue" SG_ 1470 ESP_Laengsbeschleunigung_Offset 254;
BA_ "GenSigSwitchedByIgnition" SG_ 1470 ESP_Laengsbeschleunigung_Offset 0;
BA_ "Fehlerwert" SG_ 1470 ESP_Laengsbeschleunigung_Offset 255;
BA_ "GenSigSendType" SG_ 1470 ESP_Lenkwinkel_Offset 0;
BA_ "GenSigStartValue" SG_ 1470 ESP_Lenkwinkel_Offset 510;
BA_ "GenSigSwitchedByIgnition" SG_ 1470 ESP_Lenkwinkel_Offset 0;
BA_ "Fehlerwert" SG_ 1470 ESP_Lenkwinkel_Offset 511;
BA_ "GenSigSendType" SG_ 1470 ESP_Querbeschleunigung_Offset 0;
BA_ "GenSigStartValue" SG_ 1470 ESP_Querbeschleunigung_Offset 62;
BA_ "GenSigSwitchedByIgnition" SG_ 1470 ESP_Querbeschleunigung_Offset 0;
BA_ "Fehlerwert" SG_ 1470 ESP_Querbeschleunigung_Offset 63;
BA_ "GenSigSendType" SG_ 508 ESC_Anforderung_Airbrake 0;
BA_ "GenSigSwitchedByIgnition" SG_ 508 ESC_Anforderung_Airbrake 0;
BA_ "GenSigSendType" SG_ 508 ESC_FBA_Meldungen 0;
BA_ "GenSigSwitchedByIgnition" SG_ 508 ESC_FBA_Meldungen 0;
BA_ "GenSigSendType" SG_ 508 ESC_MBK_Meldungen 0;
BA_ "GenSigSwitchedByIgnition" SG_ 508 ESC_MBK_Meldungen 0;
BA_ "GenSigSendType" SG_ 508 ESC_Motorstartverzoegerung 0;
BA_ "GenSigSwitchedByIgnition" SG_ 508 ESC_Motorstartverzoegerung 0;
BA_ "GenSigSendType" SG_ 508 ESP_32_BZ 0;
BA_ "GenSigFuncType" SG_ 508 ESP_32_BZ 1;
BA_ "GenSigSwitchedByIgnition" SG_ 508 ESP_32_BZ 0;
BA_ "GenSigSendType" SG_ 508 ESP_32_CRC 0;
BA_ "GenSigFuncType" SG_ 508 ESP_32_CRC 2;
BA_ "GenSigSwitchedByIgnition" SG_ 508 ESP_32_CRC 0;
BA_ "GenSigSendType" SG_ 508 ESP_Aggregataktivitaet 0;
BA_ "GenSigSwitchedByIgnition" SG_ 508 ESP_Aggregataktivitaet 0;
BA_ "GenSigSendType" SG_ 508 ESP_AVH_LED 0;
BA_ "GenSigStartValue" SG_ 508 ESP_AVH_LED 6;
BA_ "GenSigSwitchedByIgnition" SG_ 508 ESP_AVH_LED 0;
BA_ "GenSigSendType" SG_ 508 ESP_EDS_Anzeige 0;
BA_ "GenSigSwitchedByIgnition" SG_ 508 ESP_EDS_Anzeige 0;
BA_ "GenSigSendType" SG_ 508 ESP_HDC_LED 0;
BA_ "GenSigStartValue" SG_ 508 ESP_HDC_LED 6;
BA_ "GenSigSwitchedByIgnition" SG_ 508 ESP_HDC_LED 0;
BA_ "GenSigSendType" SG_ 508 ESP_HDC_Textanzeigen 0;
BA_ "GenSigSwitchedByIgnition" SG_ 508 ESP_HDC_Textanzeigen 0;
BA_ "GenSigSendType" SG_ 508 ESP_HOLD_verf 0;
BA_ "GenSigSwitchedByIgnition" SG_ 508 ESP_HOLD_verf 0;
BA_ "GenSigSendType" SG_ 508 ESP_Notbremsanzeige 0;
BA_ "GenSigSwitchedByIgnition" SG_ 508 ESP_Notbremsanzeige 0;
BA_ "GenSigSendType" SG_ 508 ESP_Off_LED 0;
BA_ "GenSigStartValue" SG_ 508 ESP_Off_LED 6;
BA_ "GenSigSwitchedByIgnition" SG_ 508 ESP_Off_LED 0;
BA_ "GenSigSendType" SG_ 508 ESP_Offroad_Lampe 0;
BA_ "GenSigSwitchedByIgnition" SG_ 508 ESP_Offroad_Lampe 0;
BA_ "GenSigSendType" SG_ 508 ESP_Rollover_Status_dyn 0;
BA_ "GenSigSwitchedByIgnition" SG_ 508 ESP_Rollover_Status_dyn 0;
BA_ "GenSigSendType" SG_ 508 ESP_Rollover_Status_stat 0;
BA_ "GenSigSwitchedByIgnition" SG_ 508 ESP_Rollover_Status_stat 0;
BA_ "GenSigSendType" SG_ 508 ESP_Status_Bremsentemp_02 0;
BA_ "GenSigSwitchedByIgnition" SG_ 508 ESP_Status_Bremsentemp_02 0;
BA_ "GenSigSendType" SG_ 508 ESP_Stillstandsflag 0;
BA_ "GenSigSwitchedByIgnition" SG_ 508 ESP_Stillstandsflag 0;
BA_ "GenSigSendType" SG_ 508 ESP_Wiederstart_Anz_Std 0;
BA_ "GenSigSwitchedByIgnition" SG_ 508 ESP_Wiederstart_Anz_Std 0;
BA_ "GenSigSendType" SG_ 508 RLE_Anzeigen 0;
BA_ "GenSigSwitchedByIgnition" SG_ 508 RLE_Anzeigen 0;
BA_REL_ "GenSigTimeoutTime" BU_SG_REL_ BCM1 SG_ 1431 SoSe_SunInt_2D_Re_Dash 5000;
BA_REL_ "GenSigTimeoutTime" BU_SG_REL_ BCM1 SG_ 1431 SoSe_SunInt_2D_Li_Dash 5000;
BA_REL_ "GenSigTimeoutTime" BU_SG_REL_ BCM1 SG_ 870 BM_ZV_auf 5000;
BA_REL_ "GenSigTimeoutTime" BU_SG_REL_ BCM1 SG_ 870 BM_ZV_zu 5000;
BA_REL_ "GenSigTimeoutTime" BU_SG_REL_ BCM1 SG_ 870 BM_DWA_ein 5000;
BA_REL_ "GenSigTimeoutTime" BU_SG_REL_ BCM1 SG_ 870 BM_DWA_Alarm 5000;
BA_REL_ "GenSigTimeoutTime" BU_SG_REL_ BCM1 SG_ 870 BM_Crash 5000;
BA_REL_ "GenSigTimeoutTime" BU_SG_REL_ BCM1 SG_ 870 BM_Panik 5000;
BA_REL_ "GenSigTimeoutTime" BU_SG_REL_ BCM1 SG_ 870 BM_Not_Bremsung 5000;
BA_REL_ "GenSigTimeoutTime" BU_SG_REL_ BCM1 SG_ 870 BM_GDO 5000;
BA_REL_ "GenSigTimeoutTime" BU_SG_REL_ BCM1 SG_ 870 BM_Warnblinken 5000;
BA_REL_ "GenSigTimeoutTime" BU_SG_REL_ BCM1 SG_ 870 BM_Taxi_Notalarm 5000;
BA_REL_ "GenSigTimeoutTime" BU_SG_REL_ BCM1 SG_ 870 BM_Telematik 5000;
BA_REL_ "GenSigTimeoutTime" BU_SG_REL_ BCM1 SG_ 870 BM_links 5000;
BA_REL_ "GenSigTimeoutTime" BU_SG_REL_ BCM1 SG_ 870 BM_rechts 5000;
BA_REL_ "GenSigTimeoutTime" BU_SG_REL_ BCM1 SG_ 870 Blinken_li_Fzg_Takt 5000;
BA_REL_ "GenSigTimeoutTime" BU_SG_REL_ BCM1 SG_ 870 Blinken_re_Fzg_Takt 5000;
BA_REL_ "GenSigTimeoutTime" BU_SG_REL_ BCM1 SG_ 870 BM_WBT_Beleuchtung 5000;
BA_REL_ "GenSigTimeoutTime" BU_SG_REL_ BCM1 SG_ 870 BM_HD_Oeffnung_angelernt 5000;
BA_REL_ "GenSigTimeoutTime" BU_SG_REL_ BCM1 SG_ 870 BM_Autobahn 5000;
BA_REL_ "GenSigTimeoutTime" BU_SG_REL_ BCM1 SG_ 870 BM_Rollenmodus_Blinken 5000;
BA_REL_ "GenSigTimeoutTime" BU_SG_REL_ BCM1 SG_ 870 BM_Recas 5000;
BA_REL_ "GenSigTimeoutTime" BU_SG_REL_ BCM1 SG_ 870 BM_Wischblinken 5000;
BA_REL_ "GenSigTimeoutTime" BU_SG_REL_ BCM1 SG_ 870 BM_PiloPa 5000;
BA_REL_ "GenSigTimeoutTime" BU_SG_REL_ BCM1 SG_ 901 CHA_Ziel_FahrPr_MO_BZS 5000;
BA_REL_ "GenSigTimeoutTime" BU_SG_REL_ BCM1 SG_ 901 CHA_Ziel_FahrPr_AFS 5000;
BA_REL_ "GenSigTimeoutTime" BU_SG_REL_ BCM1 SG_ 902 CHA_Eco_Charisma_LED 5000;
BA_REL_ "GenSigTimeoutTime" BU_SG_REL_ BCM1 SG_ 902 CHA_Fahrer_Umschaltung 5000;
BA_REL_ "GenSigTimeoutTime" BU_SG_REL_ BCM1 SG_ 902 CHA_EV_LED 5000;
BA_REL_ "GenSigTimeoutTime" BU_SG_REL_ BCM1 SG_ 902 CHA_Ziel_FahrPr_AMB 5000;
BA_REL_ "GenSigTimeoutTime" BU_SG_REL_ BCM1 SG_ 902 CHA_Ziel_FahrPr_KL 5000;
BA_REL_ "GenSigTimeoutTime" BU_SG_REL_ BCM1 SG_ 902 CHA_Drehschalter_Istmodus 5000;
BA_REL_ "GenSigTimeoutTime" BU_SG_REL_ BCM1 SG_ 1000 CHA_Ziel_FahrPr_AV 5000;
BA_REL_ "GenSigTimeoutTime" BU_SG_REL_ BCM1 SG_ 1022 CHA_Ziel_FahrPr_PDC 5000;
BA_REL_ "GenSigTimeoutTime" BU_SG_REL_ BCM1 SG_ 1714 DGN_Verlernzaehler 5000;
BA_REL_ "GenSigTimeoutTime" BU_SG_REL_ BCM1 SG_ 1714 KBI_Kilometerstand 5000;
BA_REL_ "GenSigTimeoutTime" BU_SG_REL_ BCM1 SG_ 1714 UH_Jahr 5000;
BA_REL_ "GenSigTimeoutTime" BU_SG_REL_ BCM1 SG_ 1714 UH_Monat 5000;
BA_REL_ "GenSigTimeoutTime" BU_SG_REL_ BCM1 SG_ 1714 UH_Tag 5000;
BA_REL_ "GenSigTimeoutTime" BU_SG_REL_ BCM1 SG_ 1714 UH_Stunde 5000;
BA_REL_ "GenSigTimeoutTime" BU_SG_REL_ BCM1 SG_ 1714 UH_Minute 5000;
BA_REL_ "GenSigTimeoutTime" BU_SG_REL_ BCM1 SG_ 1714 UH_Sekunde 5000;
BA_REL_ "GenSigTimeoutTime" BU_SG_REL_ BCM1 SG_ 1714 Uhrzeit_01_alt 5000;
BA_REL_ "GenSigTimeoutTime" BU_SG_REL_ BCM1 SG_ 420 EA_Funktionsstatus 5000;
BA_REL_ "GenSigTimeoutTime" BU_SG_REL_ BCM1 SG_ 496 EA_Innenraumlicht_Anf 500;
BA_REL_ "GenSigTimeoutTime" BU_SG_REL_ BCM1 SG_ 2527679980 eCall_Statuslicht_Farbe2 5000;
BA_REL_ "GenSigTimeoutTime" BU_SG_REL_ BCM1 SG_ 2527679980 eCall_Statuslicht_Farbe1 5000;
BA_REL_ "GenSigTimeoutTime" BU_SG_REL_ BCM1 SG_ 2527679980 bCall_active 5000;
BA_REL_ "GenSigTimeoutTime" BU_SG_REL_ BCM1 SG_ 1603 KBI_Einheit_Temp 5000;
BA_REL_ "GenSigTimeoutTime" BU_SG_REL_ BCM1 SG_ 260 EPB_Fehlerstatus_02 5000;
BA_REL_ "GenSigTimeoutTime" BU_SG_REL_ BCM1 SG_ 260 EPB_Status_02 5000;
BA_REL_ "GenSigTimeoutTime" BU_SG_REL_ BCM1 SG_ 259 ESP_VL_FR 500;
BA_REL_ "GenSigTimeoutTime" BU_SG_REL_ BCM1 SG_ 259 ESP_VR_FR 500;
BA_REL_ "GenSigTimeoutTime" BU_SG_REL_ BCM1 SG_ 259 ESP_HL_FR 500;
BA_REL_ "GenSigTimeoutTime" BU_SG_REL_ BCM1 SG_ 259 ESP_HR_FR 500;
BA_REL_ "GenSigTimeoutTime" BU_SG_REL_ BCM1 SG_ 259 ESP_VL_Radgeschw 500;
BA_REL_ "GenSigTimeoutTime" BU_SG_REL_ BCM1 SG_ 259 ESP_VR_Radgeschw 500;
BA_REL_ "GenSigTimeoutTime" BU_SG_REL_ BCM1 SG_ 259 ESP_HL_Radgeschw 500;
BA_REL_ "GenSigTimeoutTime" BU_SG_REL_ BCM1 SG_ 259 ESP_HR_Radgeschw 500;
BA_REL_ "GenSigTimeoutTime" BU_SG_REL_ BCM1 SG_ 914 ESP_Codierung_ADS 800;
BA_REL_ "GenSigTimeoutTime" BU_SG_REL_ BCM1 SG_ 914 ESP_Rollenmodus_Deaktivieren 800;
BA_REL_ "GenSigTimeoutTime" BU_SG_REL_ BCM1 SG_ 278 ESP_10_CRC 500;
BA_REL_ "GenSigTimeoutTime" BU_SG_REL_ BCM1 SG_ 278 ESP_10_BZ 500;
BA_REL_ "GenSigTimeoutTime" BU_SG_REL_ BCM1 SG_ 278 ESP_QBit_Wegimpuls_VL 500;
BA_REL_ "GenSigTimeoutTime" BU_SG_REL_ BCM1 SG_ 278 ESP_QBit_Wegimpuls_VR 500;
BA_REL_ "GenSigTimeoutTime" BU_SG_REL_ BCM1 SG_ 278 ESP_QBit_Wegimpuls_HL 500;
BA_REL_ "GenSigTimeoutTime" BU_SG_REL_ BCM1 SG_ 278 ESP_QBit_Wegimpuls_HR 500;
BA_REL_ "GenSigTimeoutTime" BU_SG_REL_ BCM1 SG_ 278 ESP_Wegimpuls_VL 500;
BA_REL_ "GenSigTimeoutTime" BU_SG_REL_ BCM1 SG_ 278 ESP_Wegimpuls_VR 500;
BA_REL_ "GenSigTimeoutTime" BU_SG_REL_ BCM1 SG_ 278 ESP_Wegimpuls_HL 500;
BA_REL_ "GenSigTimeoutTime" BU_SG_REL_ BCM1 SG_ 278 ESP_Wegimpuls_HR 500;
BA_REL_ "GenSigTimeoutTime" BU_SG_REL_ BCM1 SG_ 278 ESP_VL_Fahrtrichtung 500;
BA_REL_ "GenSigTimeoutTime" BU_SG_REL_ BCM1 SG_ 278 ESP_VR_Fahrtrichtung 500;
BA_REL_ "GenSigTimeoutTime" BU_SG_REL_ BCM1 SG_ 278 ESP_HL_Fahrtrichtung 500;
BA_REL_ "GenSigTimeoutTime" BU_SG_REL_ BCM1 SG_ 278 ESP_HR_Fahrtrichtung 500;
BA_REL_ "GenSigTimeoutTime" BU_SG_REL_ BCM1 SG_ 418 HMS_Konsistenz_IPA 2000;
BA_REL_ "GenSigTimeoutTime" BU_SG_REL_ BCM1 SG_ 418 VZM_Status 2000;
BA_REL_ "GenSigTimeoutTime" BU_SG_REL_ BCM1 SG_ 418 HMS_Systemstatus 2000;
BA_REL_ "GenSigTimeoutTime" BU_SG_REL_ BCM1 SG_ 418 HMS_Stillstand 2000;
BA_REL_ "GenSigTimeoutTime" BU_SG_REL_ BCM1 SG_ 418 HMS_aktives_System 2000;
BA_REL_ "GenSigTimeoutTime" BU_SG_REL_ BCM1 SG_ 418 HMS_Fehlerstatus 2000;
BA_REL_ "GenSigTimeoutTime" BU_SG_REL_ BCM1 SG_ 253 ESP_21_CRC 500;
BA_REL_ "GenSigTimeoutTime" BU_SG_REL_ BCM1 SG_ 253 ESP_21_BZ 500;
BA_REL_ "GenSigTimeoutTime" BU_SG_REL_ BCM1 SG_ 253 BR_Eingriffsmoment 500;
BA_REL_ "GenSigTimeoutTime" BU_SG_REL_ BCM1 SG_ 253 ESP_Diagnose 500;
BA_REL_ "GenSigTimeoutTime" BU_SG_REL_ BCM1 SG_ 253 ESC_v_Signal_Qualifier_High_Low 500;
BA_REL_ "GenSigTimeoutTime" BU_SG_REL_ BCM1 SG_ 253 ESP_Vorsteuerung 500;
BA_REL_ "GenSigTimeoutTime" BU_SG_REL_ BCM1 SG_ 253 OBD_Schlechtweg 500;
BA_REL_ "GenSigTimeoutTime" BU_SG_REL_ BCM1 SG_ 253 OBD_QBit_Schlechtweg 500;
BA_REL_ "GenSigTimeoutTime" BU_SG_REL_ BCM1 SG_ 253 ESP_v_Signal 500;
BA_REL_ "GenSigTimeoutTime" BU_SG_REL_ BCM1 SG_ 253 ASR_Tastung_passiv 500;
BA_REL_ "GenSigTimeoutTime" BU_SG_REL_ BCM1 SG_ 253 ESP_Tastung_passiv 500;
BA_REL_ "GenSigTimeoutTime" BU_SG_REL_ BCM1 SG_ 253 ESP_Systemstatus 500;
BA_REL_ "GenSigTimeoutTime" BU_SG_REL_ BCM1 SG_ 253 ASR_Schalteingriff 500;
BA_REL_ "GenSigTimeoutTime" BU_SG_REL_ BCM1 SG_ 253 ESP_QBit_v_Signal 500;
BA_REL_ "GenSigTimeoutTime" BU_SG_REL_ BCM1 SG_ 253 ABS_Bremsung 500;
BA_REL_ "GenSigTimeoutTime" BU_SG_REL_ BCM1 SG_ 253 ASR_Anf 500;
BA_REL_ "GenSigTimeoutTime" BU_SG_REL_ BCM1 SG_ 253 MSR_Anf 500;
BA_REL_ "GenSigTimeoutTime" BU_SG_REL_ BCM1 SG_ 253 EBV_Eingriff 500;
BA_REL_ "GenSigTimeoutTime" BU_SG_REL_ BCM1 SG_ 253 EDS_Eingriff 500;
BA_REL_ "GenSigTimeoutTime" BU_SG_REL_ BCM1 SG_ 253 ESP_Eingriff 500;
BA_REL_ "GenSigTimeoutTime" BU_SG_REL_ BCM1 SG_ 253 ESP_ASP 500;
BA_REL_ "GenSigTimeoutTime" BU_SG_REL_ BCM1 SG_ 508 ESP_Stillstandsflag 1000;
BA_REL_ "GenSigTimeoutTime" BU_SG_REL_ BCM1 SG_ 508 ESP_AVH_LED 1000;
BA_REL_ "GenSigTimeoutTime" BU_SG_REL_ BCM1 SG_ 508 ESP_HDC_LED 1000;
BA_REL_ "GenSigTimeoutTime" BU_SG_REL_ BCM1 SG_ 508 ESP_Off_LED 1000;
BA_REL_ "GenSigTimeoutTime" BU_SG_REL_ Gateway SG_ 1432 BCM_BFS_Fernsteuerung_aktiv 5000;
BA_REL_ "GenSigTimeoutTime" BU_SG_REL_ Gateway SG_ 1432 BCM_FS_Programmwippe 5000;
BA_REL_ "GenSigTimeoutTime" BU_SG_REL_ Gateway SG_ 1432 BCM_BFS_Programmwippe 5000;
BA_REL_ "GenSigTimeoutTime" BU_SG_REL_ Gateway SG_ 1432 BCM_FS_Multif_Taster 5000;
BA_REL_ "GenSigTimeoutTime" BU_SG_REL_ Gateway SG_ 1432 BCM_BFS_Multif_Taster 5000;
BA_REL_ "GenSigTimeoutTime" BU_SG_REL_ Gateway SG_ 1432 BCM_FS_Massage_Taster 5000;
BA_REL_ "GenSigTimeoutTime" BU_SG_REL_ Gateway SG_ 1432 BCM_BFS_Massage_Taster 5000;
BA_REL_ "GenSigTimeoutTime" BU_SG_REL_ Gateway SG_ 1432 BCM_FS_Pneumatik_Verstellung 5000;
BA_REL_ "GenSigTimeoutTime" BU_SG_REL_ Gateway SG_ 1432 BCM_BFS_Pneumatik_Verstellung 5000;
BA_REL_ "GenSigTimeoutTime" BU_SG_REL_ Gateway SG_ 1520 DI_KL_58xd 2000;
BA_REL_ "GenSigTimeoutTime" BU_SG_REL_ Gateway SG_ 1520 DI_KL_58xs 2000;
BA_REL_ "GenSigTimeoutTime" BU_SG_REL_ Klima_MSB SG_ 902 CHA_Fahrer_Umschaltung 5000;
BA_REL_ "GenSigTimeoutTime" BU_SG_REL_ Klima_MSB SG_ 902 CHA_Ziel_FahrPr_KL 5000;
BA_REL_ "GenSigTimeoutTime" BU_SG_REL_ Klima_MSB SG_ 1714 DGN_Verlernzaehler 5000;
BA_REL_ "GenSigTimeoutTime" BU_SG_REL_ Klima_MSB SG_ 1714 KBI_Kilometerstand 5000;
BA_REL_ "GenSigTimeoutTime" BU_SG_REL_ Klima_MSB SG_ 1714 UH_Jahr 5000;
BA_REL_ "GenSigTimeoutTime" BU_SG_REL_ Klima_MSB SG_ 1714 UH_Monat 5000;
BA_REL_ "GenSigTimeoutTime" BU_SG_REL_ Klima_MSB SG_ 1714 UH_Tag 5000;
BA_REL_ "GenSigTimeoutTime" BU_SG_REL_ Klima_MSB SG_ 1714 UH_Stunde 5000;
BA_REL_ "GenSigTimeoutTime" BU_SG_REL_ Klima_MSB SG_ 1714 UH_Minute 5000;
BA_REL_ "GenSigTimeoutTime" BU_SG_REL_ Klima_MSB SG_ 1714 UH_Sekunde 5000;
BA_REL_ "GenSigTimeoutTime" BU_SG_REL_ Klima_MSB SG_ 1603 KBI_Einheit_Temp 5000;
BA_REL_ "GenSigTimeoutTime" BU_SG_REL_ Klima_MSB SG_ 914 ESP_Rollenmodus_Deaktivieren 800;
BA_REL_ "GenSigTimeoutTime" BU_SG_REL_ Klima_MSB SG_ 253 ESP_v_Signal 500;
BA_REL_ "GenSigTimeoutTime" BU_SG_REL_ Klima_MSB SG_ 253 ESP_QBit_v_Signal 500;
BA_REL_ "GenSigTimeoutTime" BU_SG_REL_ Lift_VA SG_ 1431 BED_Taster_Lift 5000;
BA_REL_ "GenSigTimeoutTime" BU_SG_REL_ Lift_VA SG_ 1714 DGN_Verlernzaehler 5000;
BA_REL_ "GenSigTimeoutTime" BU_SG_REL_ Lift_VA SG_ 1714 KBI_Kilometerstand 5000;
BA_REL_ "GenSigTimeoutTime" BU_SG_REL_ Lift_VA SG_ 1714 UH_Jahr 5000;
BA_REL_ "GenSigTimeoutTime" BU_SG_REL_ Lift_VA SG_ 1714 UH_Monat 5000;
BA_REL_ "GenSigTimeoutTime" BU_SG_REL_ Lift_VA SG_ 1714 UH_Tag 5000;
BA_REL_ "GenSigTimeoutTime" BU_SG_REL_ Lift_VA SG_ 1714 UH_Stunde 5000;
BA_REL_ "GenSigTimeoutTime" BU_SG_REL_ Lift_VA SG_ 1714 UH_Minute 5000;
BA_REL_ "GenSigTimeoutTime" BU_SG_REL_ Lift_VA SG_ 1714 UH_Sekunde 5000;
BA_REL_ "GenSigTimeoutTime" BU_SG_REL_ Lift_VA SG_ 253 ESP_v_Signal 500;
BA_REL_ "GenSigTimeoutTime" BU_SG_REL_ VAS_L SG_ 870 Blinken_li_Fzg_Takt 5000;
BA_REL_ "GenSigTimeoutTime" BU_SG_REL_ VAS_L SG_ 1714 DGN_Verlernzaehler 5000;
BA_REL_ "GenSigTimeoutTime" BU_SG_REL_ VAS_L SG_ 1714 KBI_Kilometerstand 5000;
BA_REL_ "GenSigTimeoutTime" BU_SG_REL_ VAS_L SG_ 1714 UH_Jahr 5000;
BA_REL_ "GenSigTimeoutTime" BU_SG_REL_ VAS_L SG_ 1714 UH_Monat 5000;
BA_REL_ "GenSigTimeoutTime" BU_SG_REL_ VAS_L SG_ 1714 UH_Tag 5000;
BA_REL_ "GenSigTimeoutTime" BU_SG_REL_ VAS_L SG_ 1714 UH_Stunde 5000;
BA_REL_ "GenSigTimeoutTime" BU_SG_REL_ VAS_L SG_ 1714 UH_Minute 5000;
BA_REL_ "GenSigTimeoutTime" BU_SG_REL_ VAS_L SG_ 1714 UH_Sekunde 5000;
BA_REL_ "GenSigTimeoutTime" BU_SG_REL_ VAS_L SG_ 1714 Uhrzeit_01_alt 5000;
BA_REL_ "GenSigTimeoutTime" BU_SG_REL_ VAS_L SG_ 1520 DI_KL_58xd 2000;
BA_REL_ "GenSigTimeoutTime" BU_SG_REL_ VAS_L SG_ 1520 DI_KL_58xs 2000;
BA_REL_ "GenSigTimeoutTime" BU_SG_REL_ VAS_L SG_ 1520 DI_Display_Nachtdesign 2000;
BA_REL_ "GenSigTimeoutTime" BU_SG_REL_ VAS_L SG_ 1520 DI_KL_58xt 2000;
BA_REL_ "GenSigTimeoutTime" BU_SG_REL_ VAS_L SG_ 1520 DI_Fotosensor 2000;
BA_REL_ "GenSigTimeoutTime" BU_SG_REL_ VAS_L SG_ 259 ESP_VL_FR 500;
BA_REL_ "GenSigTimeoutTime" BU_SG_REL_ VAS_L SG_ 259 ESP_VR_FR 500;
BA_REL_ "GenSigTimeoutTime" BU_SG_REL_ VAS_L SG_ 259 ESP_HL_FR 500;
BA_REL_ "GenSigTimeoutTime" BU_SG_REL_ VAS_L SG_ 259 ESP_HR_FR 500;
BA_REL_ "GenSigTimeoutTime" BU_SG_REL_ VAS_L SG_ 259 ESP_VL_Radgeschw 500;
BA_REL_ "GenSigTimeoutTime" BU_SG_REL_ VAS_L SG_ 259 ESP_VR_Radgeschw 500;
BA_REL_ "GenSigTimeoutTime" BU_SG_REL_ VAS_L SG_ 259 ESP_HL_Radgeschw 500;
BA_REL_ "GenSigTimeoutTime" BU_SG_REL_ VAS_L SG_ 259 ESP_HR_Radgeschw 500;
BA_REL_ "GenSigTimeoutTime" BU_SG_REL_ VAS_L SG_ 253 ESP_v_Signal 500;
BA_REL_ "GenSigTimeoutTime" BU_SG_REL_ VAS_L SG_ 253 ESP_QBit_v_Signal 500;
BA_REL_ "GenSigTimeoutTime" BU_SG_REL_ VAS_L SG_ 1470 ESP_Gierrate_Offset_2 3200;
BA_REL_ "GenSigTimeoutTime" BU_SG_REL_ VAS_R SG_ 870 Blinken_re_Fzg_Takt 5000;
BA_REL_ "GenSigTimeoutTime" BU_SG_REL_ VAS_R SG_ 1714 DGN_Verlernzaehler 5000;
BA_REL_ "GenSigTimeoutTime" BU_SG_REL_ VAS_R SG_ 1714 UH_Jahr 5000;
BA_REL_ "GenSigTimeoutTime" BU_SG_REL_ VAS_R SG_ 1714 UH_Monat 5000;
BA_REL_ "GenSigTimeoutTime" BU_SG_REL_ VAS_R SG_ 1714 UH_Tag 5000;
BA_REL_ "GenSigTimeoutTime" BU_SG_REL_ VAS_R SG_ 1714 UH_Stunde 5000;
BA_REL_ "GenSigTimeoutTime" BU_SG_REL_ VAS_R SG_ 1714 UH_Minute 5000;
BA_REL_ "GenSigTimeoutTime" BU_SG_REL_ VAS_R SG_ 1714 UH_Sekunde 5000;
BA_REL_ "GenSigTimeoutTime" BU_SG_REL_ VAS_R SG_ 1714 Uhrzeit_01_alt 5000;
BA_REL_ "GenSigTimeoutTime" BU_SG_REL_ VAS_R SG_ 1520 DI_KL_58xd 2000;
BA_REL_ "GenSigTimeoutTime" BU_SG_REL_ VAS_R SG_ 1520 DI_KL_58xs 2000;
BA_REL_ "GenSigTimeoutTime" BU_SG_REL_ VAS_R SG_ 1520 DI_Display_Nachtdesign 2000;
BA_REL_ "GenSigTimeoutTime" BU_SG_REL_ VAS_R SG_ 1520 DI_KL_58xt 2000;
BA_REL_ "GenSigTimeoutTime" BU_SG_REL_ VAS_R SG_ 1520 DI_Fotosensor 2000;
BA_REL_ "GenSigTimeoutTime" BU_SG_REL_ VAS_R SG_ 259 ESP_VL_FR 500;
BA_REL_ "GenSigTimeoutTime" BU_SG_REL_ VAS_R SG_ 259 ESP_VR_FR 500;
BA_REL_ "GenSigTimeoutTime" BU_SG_REL_ VAS_R SG_ 259 ESP_HL_FR 500;
BA_REL_ "GenSigTimeoutTime" BU_SG_REL_ VAS_R SG_ 259 ESP_HR_FR 500;
BA_REL_ "GenSigTimeoutTime" BU_SG_REL_ VAS_R SG_ 259 ESP_VL_Radgeschw 500;
BA_REL_ "GenSigTimeoutTime" BU_SG_REL_ VAS_R SG_ 259 ESP_VR_Radgeschw 500;
BA_REL_ "GenSigTimeoutTime" BU_SG_REL_ VAS_R SG_ 259 ESP_HL_Radgeschw 500;
BA_REL_ "GenSigTimeoutTime" BU_SG_REL_ VAS_R SG_ 259 ESP_HR_Radgeschw 500;
BA_REL_ "GenSigTimeoutTime" BU_SG_REL_ VAS_R SG_ 253 ESP_v_Signal 500;
BA_REL_ "GenSigTimeoutTime" BU_SG_REL_ VAS_R SG_ 253 ESP_QBit_v_Signal 500;
BA_REL_ "GenSigTimeoutTime" BU_SG_REL_ VAS_R SG_ 1470 ESP_Gierrate_Offset_2 3200;
VAL_ 1432 BCM_BFS_Fernsteuerung_aktiv 0 "inaktiv" 1 "aktiv" ;
VAL_ 1432 BCM_Soundklappe_Taster 0 "Taster_nicht_Betaetigt" 1 "Taster_Betaetigt" ;
VAL_ 1432 E_Sound_LED_Status 0 "LED_aus" 1 "LED_ein" 2 "LED_blinken" 3 "Fehler" ;
VAL_ 1432 Pilot_Taster 0 "Taste_nicht_betaetigt" 1 "Taste_entprellt_betaetigt" 2 "Init_oder_nicht_verbaut" 3 "Fehler" ;
VAL_ 1432 BCM1_eSound_Taster 0 "Taste_nicht_betaetigt" 1 "Taste_entprellt_betaetigt" 2 "Init_oder_nicht_verbaut" 3 "Fehler" ;
VAL_ 1432 BCM_FS_Programmwippe 0 "Taster_unbetaetigt" 1 "Taster_betaetigt" ;
VAL_ 1432 BCM_BFS_Programmwippe 0 "Taster_unbetaetigt" 1 "Taster_betaetigt" ;
VAL_ 1432 BCM_FS_Multif_Taster 0 "Taster_unbetaetigt" 1 "Taster_betaetigt" ;
VAL_ 1432 BCM_BFS_Multif_Taster 0 "Taster_unbetaetigt" 1 "Taster_betaetigt" ;
VAL_ 1432 BCM_FS_Massage_Taster 0 "Taster_unbetaetigt" 1 "Taster_betaetigt" ;
VAL_ 1432 BCM_BFS_Massage_Taster 0 "Taster_unbetaetigt" 1 "Taster_betaetigt" ;
VAL_ 1432 BCM_FS_Pneumatik_Verstellung 0 "keine_Verstellung" 1 "Pneumatikverstellung_aktiv" ;
VAL_ 1432 BCM_BFS_Pneumatik_Verstellung 0 "keine_Verstellung" 1 "Pneumatikverstellung_aktiv" ;
VAL_ 1432 LIM_Rear_Mode 0 "inaktiv" 1 "aktiv" ;
VAL_ 1432 BCM1_NR_Ride_Height_Up_Taster 0 "Taste_nicht_betaetigt" 1 "Taste_entprellt_betaetigt" 2 "Init_oder_nicht_verbaut" 3 "Fehler" ;
VAL_ 1432 BCM1_NR_Ride_Height_Down_Taster 0 "Taste_nicht_betaetigt" 1 "Taste_entprellt_betaetigt" 2 "Init_oder_nicht_verbaut" 3 "Fehler" ;
VAL_ 1432 LIM_S_Rollo_vo 0 "nicht_betaetigt" 1 "man_zu" 2 "auto_zu" 3 "man_auf" 4 "auto_auf" 6 "fehler_schalter_haengt" 7 "fehler_schalter_unplausibel" ;
VAL_ 1432 LIM_S_Rollo_hi 0 "nicht_betaetigt" 1 "man_zu" 2 "auto_zu" 3 "man_auf" 4 "auto_auf" 6 "fehler_schalter_haengt" 7 "fehler_schalter_unplausibel" ;
VAL_ 1432 LIM_S_SAD_Vo 0 "nicht_betaetigt" 1 "man_sl_zu" 2 "auto_sl_zu" 3 "man_sl_auf" 4 "auto_sl_auf" 5 "man_al_auf" 6 "auto_al_auf" 7 "man_al_zu" 8 "auto_al_zu" 14 "fehler_schalter_haengt" 15 "fehler_schalter_unplausibel" ;
VAL_ 1432 LIM_S_SAD_hi 0 "nicht_betaetigt" 1 "man_sl_zu" 2 "auto_sl_zu" 3 "man_sl_auf" 4 "auto_sl_auf" 5 "man_al_auf" 6 "auto_al_auf" 7 "man_al_zu" 8 "auto_al_zu" 14 "fehler_schalter_haengt" 15 "fehler_schalter_unplausibel" ;
VAL_ 1431 BED_Taster_VD_Oeffnen 0 "Taste_nicht_betaetigt" 1 "Taste_entprellt_betaetigt" 2 "Init_oder_nicht_verbaut" 3 "Fehler" ;
VAL_ 1431 BED_Taster_VD_Schliessen 0 "Taste_nicht_betaetigt" 1 "Taste_entprellt_betaetigt" 2 "Init_oder_nicht_verbaut" 3 "Fehler" ;
VAL_ 1431 BED_Taster_Windschott 0 "Taste_nicht_betaetigt" 1 "Taste_entprellt_betaetigt" 2 "Init_oder_nicht_verbaut" 3 "Fehler" ;
VAL_ 1431 BED_SAD_vo 0 "nicht_betaetigt" 1 "man_sl_zu" 2 "auto_sl_zu" 3 "man_sl_auf" 4 "auto_sl_auf" 5 "man_al_auf" 6 "auto_al_auf" 7 "man_al_zu" 8 "auto_al_zu" 14 "fehler_schalter_haengt" 15 "fehler_schalter_unplausibel" ;
VAL_ 1431 BED_Rollo_vo 0 "nicht_betaetigt" 1 "man_zu" 2 "auto_zu" 3 "man_auf" 4 "auto_auf" 6 "fehler_schalter_haengt" 7 "fehler_schalter_unplausibel" ;
VAL_ 1431 BED_Taster_Lift 0 "Taste_nicht_betaetigt" 1 "Taste_entprellt_betaetigt" 2 "Init_oder_nicht_verbaut" 3 "Fehler" ;
VAL_ 1431 SoSe_SunInt_2D_Re_Dash 254 "Init" 255 "Fehler" ;
VAL_ 1431 SoSe_SunInt_2D_Li_Dash 254 "Init" 255 "Fehler" ;
VAL_ 1431 BED_Taster_Fahrwerk 0 "Taste_nicht_betaetigt" 1 "Taste_entprellt_betaetigt" ;
VAL_ 870 BM_ZV_auf 0 "inaktiv" 1 "aktiv" ;
VAL_ 870 BM_ZV_zu 0 "inaktiv" 1 "aktiv" ;
VAL_ 870 BM_DWA_ein 0 "inaktiv" 1 "aktiv" ;
VAL_ 870 BM_DWA_Alarm 0 "inaktiv" 1 "aktiv" ;
VAL_ 870 BM_Crash 0 "inaktiv" 1 "aktiv" ;
VAL_ 870 BM_Panik 0 "inaktiv" 1 "aktiv" ;
VAL_ 870 BM_Not_Bremsung 0 "inaktiv" 1 "aktiv" ;
VAL_ 870 BM_GDO 0 "inaktiv" 1 "aktiv" ;
VAL_ 870 BM_Warnblinken 0 "inaktiv" 1 "aktiv" ;
VAL_ 870 BM_Taxi_Notalarm 0 "inaktiv" 1 "aktiv" ;
VAL_ 870 BM_Telematik 0 "inaktiv" 1 "aktiv" ;
VAL_ 870 BM_links 0 "inaktiv" 1 "aktiv" ;
VAL_ 870 BM_rechts 0 "inaktiv" 1 "aktiv" ;
VAL_ 870 Blinken_li_Fzg_Takt 0 "Blinker_links_ausgeschaltet" 1 "Blinker_links_eingeschaltet" ;
VAL_ 870 Blinken_re_Fzg_Takt 0 "Blinker_rechts_ausgeschaltet" 1 "Blinker_rechts_eingeschaltet" ;
VAL_ 870 Blinken_li_Kombi_Takt 0 "Blinkerkontrolllampe_links_ausgeschaltet" 1 "Blinkerkontrolllampe_links_eingeschaltet" ;
VAL_ 870 Blinken_re_Kombi_Takt 0 "Blinkerkontrolllampe_rechts_ausgeschaltet" 1 "Blinkerkontrolllampe_rechts_eingeschaltet" ;
VAL_ 870 BM_NBA_n_codiert_n_aktiv 0 "codiert_AND_kein_Fehler" 1 "nicht_codiert_OR_Fehler_erkannt" ;
VAL_ 870 BM_NBA_Status 0 "NBA_nicht_aktiv" 1 "BRL_Dunkelphase" 3 "BRL_Hellphase" ;
VAL_ 870 BM_WBT_Beleuchtung 0 "inaktiv" 1 "aktiv" ;
VAL_ 870 BM_HD_Oeffnung_angelernt 0 "keine_Quittierung" 1 "Quittierung" ;
VAL_ 870 BM_Autobahn 0 "inaktiv" 1 "aktiv" ;
VAL_ 870 BM_Rollenmodus_Blinken 0 "inaktiv" 1 "aktiv" ;
VAL_ 870 BM_Recas 0 "inaktiv" 1 "aktiv" ;
VAL_ 870 BM_Wischblinken 0 "inaktiv" 1 "aktiv" ;
VAL_ 870 BM_Telematik_Abbruchgrund 0 "Init" 1 "speed_out_of_range" 2 "defect" 3 "clamp_s_on" 4 "clamp_15_on" 5 "door_open" 6 "engine_hood_open" 7 "trunk_open" 8 "convertible_top_not_locked" 9 "horn_activated_by_user" 10 "Higher_Prioritiy_Function_active" 11 "Central_Lock_status_changed" 12 "Request_Dropped_by_Requester" 13 "Service_Duration_Expired" 14 "not_possible_due_to_coding" 15 "no_reason_or_unknown_timeout" ;
VAL_ 870 BM_PiloPa 0 "PiloPa_Blinkerquittierung_inaktiv" 1 "PiloPa_Blinkerquittierung_aktiv" ;
VAL_ 870 DWA_Alarmquelle 0 "kein_Ausloesegrund" 1 "Tuerkontakt_Fahrertuer" 2 "Tuerkontakt_Beifahrertuer" 3 "Tuerkontakt_hinten_links" 4 "Tuerkontakt_hinten_rechts" 5 "Motorhaubenkontakt_vorne" 6 "Kofferraum_hinten" 7 "Masseschleife_der_Heckscheibe" 8 "Innenraumueberwachung" 9 "Alarm_durch_Noteinstieg" 10 "Sounder" 11 "Neigungssensor" 12 "TSG_FT_am_CAN_Bus" 13 "TSG_BT_am_CAN_Bus" 14 "TSG_HFS_am_CAN_Bus" 15 "TSG_HBFS_am_CAN_Bus" 16 "Klemme_15" 17 "Klemme_15sig" 18 "frei" 19 "Anhaengerueberwachung" 20 "Scheinwerferueberwachung_links" 21 "Scheinwerferueberwachung_rechts" 22 "Handschuhkasten" 23 "Verdeckueberwachung" 24 "OBD_Alarm" 30 "Init" 31 "Fehler" ;
VAL_ 868 NBlinken_li_Fzg_Takt 0 "Blinker_links_ausgeschaltet" 1 "Blinker links eingeschaltet" ;
VAL_ 868 NBlinken_re_Fzg_Takt 0 "Blinker rechts ausgeschaltet" 1 "Blinker rechts eingeschaltet" ;
VAL_ 868 NBlinken_li_Kombi_Takt 0 "Blinkerkontrolllampe_links_ausgeschaltet" 1 "Blinkerkontrolllampe_links_eingeschaltet" ;
VAL_ 868 NBlinken_re_Kombi_Takt 0 "Blinkerkontrolllampe rechts ausgeschaltet" 1 "Blinkerkontrolllampe rechts eingeschaltet" ;
VAL_ 901 CHA_Ziel_FahrPr_AGA 0 "keine_Funktion" 1 "Programm_1" 2 "Programm_2" 3 "Programm_3" 4 "Programm_4" 5 "Programm_5" 6 "Programm_6" 7 "Programm_7" 8 "Programm_8" 9 "Programm_9" 10 "Programm_10" 11 "Programm_11" 12 "Programm_12" 13 "Programm_13" 14 "Programm_14" 15 "Programm_15" ;
VAL_ 901 CHA_Ziel_FahrPr_ESP 0 "keine_Funktion" 1 "Programm_1" 2 "Programm_2" 3 "Programm_3" 4 "Programm_4" 5 "Programm_5" 6 "Programm_6" 7 "Programm_7" 8 "Programm_8" 9 "Programm_9" 10 "Programm_10" 11 "Programm_11" 12 "Programm_12" 13 "Programm_13" 14 "Programm_14" 15 "Programm_15" ;
VAL_ 901 CHA_Ziel_FahrPr_Freilauf 0 "keine_Funktion" 1 "Programm_1" 2 "Programm_2" 3 "Programm_3" 4 "Programm_4" 5 "Programm_5" 6 "Programm_6" 7 "Programm_7" 8 "Programm_8" 9 "Programm_9" 10 "Programm_10" 11 "Programm_11" 12 "Programm_12" 13 "Programm_13" 14 "Programm_14" 15 "Programm_15" ;
VAL_ 901 CHA_Fahrer_Umschaltung 0 "keine_oder_automatische_Umschaltung" 1 "manuelle_Umschaltung" ;
VAL_ 901 CHA_Fahrer_Umschaltung_BMA 0 "keine_oder_autom_Umschaltung" 1 "manuelle_Umschaltung" ;
VAL_ 901 CHA_Ziel_FahrPr_MO 0 "keine_Funktion" 1 "Programm_1" 2 "Programm_2" 3 "Programm_3" 4 "Programm_4" 5 "Programm_5" 6 "Programm_6" 7 "Programm_7" 8 "Programm_8" 9 "Programm_9" 10 "Programm_10" 11 "Programm_11" 12 "Programm_12" 13 "Programm_13" 14 "Programm_14" 15 "Programm_15" ;
VAL_ 901 CHA_Ziel_FahrPr_GE 0 "keine_Funktion" 1 "Programm_1" 2 "Programm_2" 3 "Programm_3" 4 "Programm_4" 5 "Programm_5" 6 "Programm_6" 7 "Programm_7" 8 "Programm_8" 9 "Programm_9" 10 "Programm_10" 11 "Programm_11" 12 "Programm_12" 13 "Programm_13" 14 "Programm_14" 15 "Programm_15" ;
VAL_ 901 CHA_Ziel_FahrPr_ALR 0 "keine_Funktion" 1 "Programm_1" 2 "Programm_2" 3 "Programm_3" 4 "Programm_4" 5 "Programm_5" 6 "Programm_6" 7 "Programm_7" 8 "Programm_8" 9 "Programm_9" 10 "Programm_10" 11 "Programm_11" 12 "Programm_12" 13 "Programm_13" 14 "Programm_14" 15 "Programm_15" ;
VAL_ 901 CHA_Ziel_FahrPr_MO_BZS 0 "keine_Funktion" 1 "Programm_1" 2 "Programm_2" 3 "Programm_3" 4 "Programm_4" 5 "Programm_5" 6 "Programm_6" 7 "Programm_7" 8 "Programm_8" 9 "Programm_9" 10 "Programm_10" 11 "Programm_11" 12 "Programm_12" 13 "Programm_13" 14 "Programm_14" 15 "Programm_15" ;
VAL_ 901 CHA_Ziel_FahrPr_DR 0 "keine_Funktion" 1 "Programm_1" 2 "Programm_2" 3 "Programm_3" 4 "Programm_4" 5 "Programm_5" 6 "Programm_6" 7 "Programm_7" 8 "Programm_8" 9 "Programm_9" 10 "Programm_10" 11 "Programm_11" 12 "Programm_12" 13 "Programm_13" 14 "Programm_14" 15 "Programm_15" ;
VAL_ 901 CHA_Ziel_FahrPr_VAQ 0 "keine_Funktion" 1 "Programm_1" 2 "Programm_2" 3 "Programm_3" 4 "Programm_4" 5 "Programm_5" 6 "Programm_6" 7 "Programm_7" 8 "Programm_8" 9 "Programm_9" 10 "Programm_10" 11 "Programm_11" 12 "Programm_12" 13 "Programm_13" 14 "Programm_14" 15 "Programm_15" ;
VAL_ 901 CHA_Ziel_FahrPr_AFS 0 "keine_Funktion" 1 "Programm_1" 2 "Programm_2" 3 "Programm_3" 4 "Programm_4" 5 "Programm_5" 6 "Programm_6" 7 "Programm_7" 8 "Programm_8" 9 "Programm_9" 10 "Programm_10" 11 "Programm_11" 12 "Programm_12" 13 "Programm_13" 14 "Programm_14" 15 "Programm_15" ;
VAL_ 901 CHA_Ziel_FahrPr_PreCrash 0 "keine_Funktion" 1 "Programm_1" 2 "Programm_2" 3 "Programm_3" 4 "Programm_4" 5 "Programm_5" 6 "Programm_6" 7 "Programm_7" 8 "Programm_8" 9 "Programm_9" 10 "Programm_10" 11 "Programm_11" 12 "Programm_12" 13 "Programm_13" 14 "Programm_14" 15 "Programm_15" ;
VAL_ 901 CHA_Ziel_FahrPr_EPS 0 "keine_Funktion" 1 "Programm_1" 2 "Programm_2" 3 "Programm_3" 4 "Programm_4" 5 "Programm_5" 6 "Programm_6" 7 "Programm_7" 8 "Programm_8" 9 "Programm_9" 10 "Programm_10" 11 "Programm_11" 12 "Programm_12" 13 "Programm_13" 14 "Programm_14" 15 "Programm_15" ;
VAL_ 901 CHA_Ziel_FahrPr_ACC 0 "keine_Funktion" 1 "Programm_1" 2 "Programm_2" 3 "Programm_3" 4 "Programm_4" 5 "Programm_5" 6 "Programm_6" 7 "Programm_7" 8 "Programm_8" 9 "Programm_9" 10 "Programm_10" 11 "Programm_11" 12 "Programm_12" 13 "Programm_13" 14 "Programm_14" 15 "Programm_15" ;
VAL_ 901 CHA_Ziel_FahrPr_SAK 0 "keine_Funktion" 1 "Programm_1" 2 "Programm_2" 3 "Programm_3" 4 "Programm_4" 5 "Programm_5" 6 "Programm_6" 7 "Programm_7" 8 "Programm_8" 9 "Programm_9" 10 "Programm_10" 11 "Programm_11" 12 "Programm_12" 13 "Programm_13" 14 "Programm_14" 15 "Programm_15" ;
VAL_ 901 CHA_Ziel_FahrPr_MO_StSt 0 "keine_Funktion" 1 "Programm_1" 2 "Programm_2" 3 "Programm_3" 4 "Programm_4" 5 "Programm_5" 6 "Programm_6" 7 "Programm_7" 8 "Programm_8" 9 "Programm_9" 10 "Programm_10" 11 "Programm_11" 12 "Programm_12" 13 "Programm_13" 14 "Programm_14" 15 "Programm_15" ;
VAL_ 902 CHA_Eco_Charisma_LED 0 "LED_aus_und_Blinken_aus" 1 "LED_ein_und_Blinken_aus" 2 "LED_ein_und_Blinken_ein_50_percent" 3 "reserviert" ;
VAL_ 902 CHA_Fahrer_Umschaltung 0 "keine_oder_automatische_Umschaltung" 1 "manuelle_Umschaltung" ;
VAL_ 902 CHA_EV_LED 0 "LED_aus" 1 "LED_an" ;
VAL_ 902 CHA_Ziel_FahrPr_AMB 0 "keine_Funktion" 1 "Programm_1" 2 "Programm_2" 3 "Programm_3" 4 "Programm_4" 5 "Programm_5" 6 "Programm_6" 7 "Programm_7" 8 "Programm_8" 9 "Programm_9" 10 "Programm_10" 11 "Programm_11" 12 "Programm_12" 13 "Programm_13" 14 "Programm_14" 15 "Programm_15" ;
VAL_ 902 CHA_Ziel_FahrPr_IVB 0 "keine_Funktion" 1 "Programm_1" 2 "Programm_2" 3 "Programm_3" 4 "Programm_4" 5 "Programm_5" 6 "Programm_6" 7 "Programm_7" 8 "Programm_8" 9 "Programm_9" 10 "Programm_10" 11 "Programm_11" 12 "Programm_12" 13 "Programm_13" 14 "Programm_14" 15 "Programm_15" ;
VAL_ 902 CHA_Kombi_Texte 0 "keine_Anzeige" 1 "Text_1" 2 "Text_2" 3 "Text_3" 4 "Text_4" 5 "Text_5" 6 "Text_6" 7 "Text_7" 8 "Text_8" 9 "Text_9" 10 "Text_10" 11 "Text_11" 12 "Text_12" 13 "Text_13" 14 "Text_14" 15 "Text_15" ;
VAL_ 902 CHA_Ziel_FahrPr_KL 0 "keine_Funktion" 1 "Programm_1" 2 "Programm_2" 3 "Programm_3" 4 "Programm_4" 5 "Programm_5" 6 "Programm_6" 7 "Programm_7" 8 "Programm_8" 9 "Programm_9" 10 "Programm_10" 11 "Programm_11" 12 "Programm_12" 13 "Programm_13" 14 "Programm_14" 15 "Programm_15" ;
VAL_ 902 CHA_Ziel_FahrPr_HSP 0 "keine_Funktion" 1 "Programm_1" 2 "Programm_2" 3 "Programm_3" 4 "Programm_4" 5 "Programm_5" 6 "Programm_6" 7 "Programm_7" 8 "Programm_8" 9 "Programm_9" 10 "Programm_10" 11 "Programm_11" 12 "Programm_12" 13 "Programm_13" 14 "Programm_14" 15 "Programm_15" ;
VAL_ 902 CHA_Drehschalter_Istmodus 0 "keine_Schalterstellung" 1 "Schalterstellung_1" 2 "Schalterstellung_2" 3 "Schalterstellung_3" 4 "Schalterstellung_4" 5 "Schalterstellung_5" 6 "Schalterstellung_6" 7 "Schalterstellung_7" 8 "Schalterstellung_8" 9 "Schalterstellung_9" 10 "Schalterstellung_10" 11 "Schalterstellung_11" 12 "Schalterstellung_12" 13 "Schalterstellung_13" 14 "Schalterstellung_14" 15 "Schalterstellung_15" ;
VAL_ 902 CHA_Ziel_FahrPr_RWB 0 "keine_Funktion" 1 "Programm_1" 2 "Programm_2" 3 "Programm_3" 4 "Programm_4" 5 "Programm_5" 6 "Programm_6" 7 "Programm_7" 8 "Programm_8" 9 "Programm_9" 10 "Programm_10" 11 "Programm_11" 12 "Programm_12" 13 "Programm_13" 14 "Programm_14" 15 "Programm_15" ;
VAL_ 902 CHA_Ziel_FahrPr_03_01 0 "keine_Funktion" 1 "Programm_1" 2 "Programm_2" 3 "Programm_3" 4 "Programm_4" 5 "Programm_5" 6 "Programm_6" 7 "Programm_7" 8 "Programm_8" 9 "Programm_9" 10 "Programm_10" 11 "Programm_11" 12 "Programm_12" 13 "Programm_13" 14 "Programm_14" 15 "Programm_15" ;
VAL_ 902 CHA_Ziel_FahrPr_03_02 0 "keine_Funktion" 1 "Programm_1" 2 "Programm_2" 3 "Programm_3" 4 "Programm_4" 5 "Programm_5" 6 "Programm_6" 7 "Programm_7" 8 "Programm_8" 9 "Programm_9" 10 "Programm_10" 11 "Programm_11" 12 "Programm_12" 13 "Programm_13" 14 "Programm_14" 15 "Programm_15" ;
VAL_ 902 CHA_Current_Mode 0 "keine_Funktion" 1 "Programm_1" 2 "Programm_2" 3 "Programm_3" 4 "Programm_4" 5 "Programm_5" 6 "Programm_6" 7 "Programm_7" 8 "Programm_8" 9 "Programm_9" 10 "Programm_10" 11 "Programm_11" 12 "Programm_12" 13 "Programm_13" 14 "Programm_14" 15 "Programm_15" ;
VAL_ 902 CHA_Charge_LED 0 "LED_aus" 1 "LED_ein" ;
VAL_ 902 CHA_Offroad_LED 0 "LED_aus" 1 "LED_ein" 2 "LED_blinken" 3 "Fehler" ;
VAL_ 902 CHA_Kombi_Texte_02 0 "Init" 1 "Text_1" 2 "Text_2" 3 "Text_3" 4 "Text_4" 5 "Text_5" 6 "Text_6" 7 "Text_7" 8 "Text_8" 9 "Text_9" 10 "Text_10" 11 "Text_11" 12 "Text_12" 13 "Text_13" 14 "Text_14" 15 "Text_15" ;
VAL_ 1000 CHA_Ziel_FahrPr_EBKV 0 "keine_Funktion" 1 "Programm_1" 2 "Programm_2" 3 "Programm_3" 4 "Programm_4" 5 "Programm_5" 6 "Programm_6" 7 "Programm_7" 8 "Programm_8" 9 "Programm_9" 10 "Programm_10" 11 "Programm_11" 12 "Programm_12" 13 "Programm_13" 14 "Programm_14" 15 "Programm_15" ;
VAL_ 1000 CHA_Ziel_FahrPr_IL 0 "keine_Funktion" 1 "Programm_1" 2 "Programm_2" 3 "Programm_3" 4 "Programm_4" 5 "Programm_5" 6 "Programm_6" 7 "Programm_7" 8 "Programm_8" 9 "Programm_9" 10 "Programm_10" 11 "Programm_11" 12 "Programm_12" 13 "Programm_13" 14 "Programm_14" 15 "Programm_15" ;
VAL_ 1000 CHA_Ziel_FahrPr_WarnBrems 0 "keine_Funktion" 1 "Programm_1" 2 "Programm_2" 3 "Programm_3" 4 "Programm_4" 5 "Programm_5" 6 "Programm_6" 7 "Programm_7" 8 "Programm_8" 9 "Programm_9" 10 "Programm_10" 11 "Programm_11" 12 "Programm_12" 13 "Programm_13" 14 "Programm_14" 15 "Programm_15" ;
VAL_ 1000 CHA_Fahrer_Umschaltung 0 "keine_oder_automatische_Umschaltung" 1 "manuelle_Umschaltung" ;
VAL_ 1000 CHA_Ziel_FahrPr_QS 0 "keine_Funktion" 1 "Programm_1" 2 "Programm_2" 3 "Programm_3" 4 "Programm_4" 5 "Programm_5" 6 "Programm_6" 7 "Programm_7" 8 "Programm_8" 9 "Programm_9" 10 "Programm_10" 11 "Programm_11" 12 "Programm_12" 13 "Programm_13" 14 "Programm_14" 15 "Programm_15" ;
VAL_ 1000 CHA_Ziel_FahrPr_SCU 0 "keine_Funktion" 1 "Programm_1" 2 "Programm_2" 3 "Programm_3" 4 "Programm_4" 5 "Programm_5" 6 "Programm_6" 7 "Programm_7" 8 "Programm_8" 9 "Programm_9" 10 "Programm_10" 11 "Programm_11" 12 "Programm_12" 13 "Programm_13" 14 "Programm_14" 15 "Programm_15" ;
VAL_ 1000 CHA_Ziel_FahrPr_HAL 0 "keine_Funktion" 1 "Programm_1" 2 "Programm_2" 3 "Programm_3" 4 "Programm_4" 5 "Programm_5" 6 "Programm_6" 7 "Programm_7" 8 "Programm_8" 9 "Programm_9" 10 "Programm_10" 11 "Programm_11" 12 "Programm_12" 13 "Programm_13" 14 "Programm_14" 15 "Programm_15" ;
VAL_ 1000 CHA_Ziel_FahrPr_NR 0 "keine_Funktion" 1 "Programm_1" 2 "Programm_2" 3 "Programm_3" 4 "Programm_4" 5 "Programm_5" 6 "Programm_6" 7 "Programm_7" 8 "Programm_8" 9 "Programm_9" 10 "Programm_10" 11 "Programm_11" 12 "Programm_12" 13 "Programm_13" 14 "Programm_14" 15 "Programm_15" ;
VAL_ 1000 CHA_Ziel_FahrPr_AV 0 "keine_Funktion" 1 "Programm_1" 2 "Programm_2" 3 "Programm_3" 4 "Programm_4" 5 "Programm_5" 6 "Programm_6" 7 "Programm_7" 8 "Programm_8" 9 "Programm_9" 10 "Programm_10" 11 "Programm_11" 12 "Programm_12" 13 "Programm_13" 14 "Programm_14" 15 "Programm_15" ;
VAL_ 1000 CHA_Ziel_FahrPr_MXB 0 "keine_Funktion" 1 "Programm_1" 2 "Programm_2" 3 "Programm_3" 4 "Programm_4" 5 "Programm_5" 6 "Programm_6" 7 "Programm_7" 8 "Programm_8" 9 "Programm_9" 10 "Programm_10" 11 "Programm_11" 12 "Programm_12" 13 "Programm_13" 14 "Programm_14" 15 "Programm_15" ;
VAL_ 1000 CHA_Ziel_FahrPr_AFR 0 "keine_Funktion" 1 "Programm_1" 2 "Programm_2" 3 "Programm_3" 4 "Programm_4" 5 "Programm_5" 6 "Programm_6" 7 "Programm_7" 8 "Programm_8" 9 "Programm_9" 10 "Programm_10" 11 "Programm_11" 12 "Programm_12" 13 "Programm_13" 14 "Programm_14" 15 "Programm_15" ;
VAL_ 1000 CHA_Ziel_FahrPr_HDC 0 "keine_Funktion" 1 "Programm_1" 2 "Programm_2" 3 "Programm_3" 4 "Programm_4" 5 "Programm_5" 6 "Programm_6" 7 "Programm_7" 8 "Programm_8" 9 "Programm_9" 10 "Programm_10" 11 "Programm_11" 12 "Programm_12" 13 "Programm_13" 14 "Programm_14" 15 "Programm_15" ;
VAL_ 1000 CHA_Ziel_FahrPr_EAR 0 "keine_Funktion" 1 "Programm_1" 2 "Programm_2" 3 "Programm_3" 4 "Programm_4" 5 "Programm_5" 6 "Programm_6" 7 "Programm_7" 8 "Programm_8" 9 "Programm_9" 10 "Programm_10" 11 "Programm_11" 12 "Programm_12" 13 "Programm_13" 14 "Programm_14" 15 "Programm_15" ;
VAL_ 1000 CHA_Ziel_FahrPr_FCWO 0 "keine_Funktion" 1 "Programm_1" 2 "Programm_2" 3 "Programm_3" 4 "Programm_4" 5 "Programm_5" 6 "Programm_6" 7 "Programm_7" 8 "Programm_8" 9 "Programm_9" 10 "Programm_10" 11 "Programm_11" 12 "Programm_12" 13 "Programm_13" 14 "Programm_14" 15 "Programm_15" ;
VAL_ 1000 CHA_Ziel_FahrPr_FCWP 0 "keine_Funktion" 1 "Programm_1" 2 "Programm_2" 3 "Programm_3" 4 "Programm_4" 5 "Programm_5" 6 "Programm_6" 7 "Programm_7" 8 "Programm_8" 9 "Programm_9" 10 "Programm_10" 11 "Programm_11" 12 "Programm_12" 13 "Programm_13" 14 "Programm_14" 15 "Programm_15" ;
VAL_ 1022 CHA_Fahrer_Umschaltung 0 "keine_oder_automatische_Umschaltung" 1 "manuelle_Umschaltung" ;
VAL_ 1022 CHA_Fahrer_Umschaltung_BMA 0 "keine_oder_autom_Umschaltung" 1 "manuelle_Umschaltung" ;
VAL_ 1022 CHA_Ziel_FahrPr_MO_Freilauf 0 "keine_Funktion" 1 "Programm_1" 2 "Programm_2" 3 "Programm_3" 4 "Programm_4" 5 "Programm_5" 6 "Programm_6" 7 "Programm_7" 8 "Programm_8" 9 "Programm_9" 10 "Programm_10" 11 "Programm_11" 12 "Programm_12" 13 "Programm_13" 14 "Programm_14" 15 "Programm_15" ;
VAL_ 1022 CHA_Ziel_FahrPr_BMS 0 "keine_Funktion" 1 "Programm_1" 2 "Programm_2" 3 "Programm_3" 4 "Programm_4" 5 "Programm_5" 6 "Programm_6" 7 "Programm_7" 8 "Programm_8" 9 "Programm_9" 10 "Programm_10" 11 "Programm_11" 12 "Programm_12" 13 "Programm_13" 14 "Programm_14" 15 "Programm_15" ;
VAL_ 1022 CHA_Current_Mode_BMA 0 "keine_Funktion" 1 "Programm_1" 2 "Programm_2" 3 "Programm_3" 4 "Programm_4" 5 "Programm_5" 6 "Programm_6" 7 "Programm_7" 8 "Programm_8" 9 "Programm_9" 10 "Programm_10" 11 "Programm_11" 12 "Programm_12" 13 "Programm_13" 14 "Programm_14" 15 "Programm_15" ;
VAL_ 1022 CHA_Ziel_FahrPr_PDC 0 "keine_Funktion" 1 "Programm_1" 2 "Programm_2" 3 "Programm_3" 4 "Programm_4" 5 "Programm_5" 6 "Programm_6" 7 "Programm_7" 8 "Programm_8" 9 "Programm_9" 10 "Programm_10" 11 "Programm_11" 12 "Programm_12" 13 "Programm_13" 14 "Programm_14" 15 "Programm_15" ;
VAL_ 1022 CHA_Ziel_FahrPr_HHC 0 "keine_Funktion" 1 "Programm_1" 2 "Programm_2" 3 "Programm_3" 4 "Programm_4" 5 "Programm_5" 6 "Programm_6" 7 "Programm_7" 8 "Programm_8" 9 "Programm_9" 10 "Programm_10" 11 "Programm_11" 12 "Programm_12" 13 "Programm_13" 14 "Programm_14" 15 "Programm_15" ;
VAL_ 1022 CHA_Ziel_FahrPr_EDS 0 "keine_Funktion" 1 "Programm_1" 2 "Programm_2" 3 "Programm_3" 4 "Programm_4" 5 "Programm_5" 6 "Programm_6" 7 "Programm_7" 8 "Programm_8" 9 "Programm_9" 10 "Programm_10" 11 "Programm_11" 12 "Programm_12" 13 "Programm_13" 14 "Programm_14" 15 "Programm_15" ;
VAL_ 1022 CHA_Ziel_FahrPr_PACC 0 "keine_Funktion" 1 "Programm_1" 2 "Programm_2" 3 "Programm_3" 4 "Programm_4" 5 "Programm_5" 6 "Programm_6" 7 "Programm_7" 8 "Programm_8" 9 "Programm_9" 10 "Programm_10" 11 "Programm_11" 12 "Programm_12" 13 "Programm_13" 14 "Programm_14" 15 "Programm_15" ;
VAL_ 1022 CHA_Ziel_FahrPr_AGK 0 "keine_Funktion" 1 "Programm_1" 2 "Programm_2" 3 "Programm_3" 4 "Programm_4" 5 "Programm_5" 6 "Programm_6" 7 "Programm_7" 8 "Programm_8" 9 "Programm_9" 10 "Programm_10" 11 "Programm_11" 12 "Programm_12" 13 "Programm_13" 14 "Programm_14" 15 "Programm_15" ;
VAL_ 1714 DGN_Verlernzaehler 255 "ungültiger Zählerstand oder kein gültiger Fahrzyklus" ;
VAL_ 1714 KBI_Kilometerstand 1048574 "Init" 1048575 "Fehler" ;
VAL_ 1714 UH_Monat 0 "Init" 14 "reserviert" 15 "Fehler" ;
VAL_ 1714 UH_Tag 0 "Init" ;
VAL_ 1714 Kombi_02_alt 0 "aktuell" 1 "veraltet" ;
VAL_ 1714 Uhrzeit_01_alt 0 "aktuell" 1 "veraltet" ;
VAL_ 1520 DI_KL_58xd 254 "Init" 255 "Fehler" ;
VAL_ 1520 DI_KL_58xs 126 "Init" 127 "Fehler" ;
VAL_ 1520 DI_KL_58xt 126 "Init" 127 "Fehler" ;
VAL_ 1520 BCM1_Stellgroesse_Kl_58s 125 "Nicht_verbaut" 126 "Init" 127 "Fehler" ;
VAL_ 420 EA_Parken_beibehalten_HMS 0 "Parken_nicht_beibehalten" 1 "Parken_beibehalten" 2 "Init" 3 "Fehler" ;
VAL_ 420 EA_Warnruckprofil 0 "keine_Ruckanforderung" 1 "Profil_1" 2 "Profil_2" 3 "Profil_3" 4 "Profil_4" 5 "Profil_5" 6 "Profil_6" 7 "Profil_7" ;
VAL_ 420 EA_eCall_Anf 0 "Keine_Anforderung" 1 "Ausloesen_eCall" ;
VAL_ 420 EA_Funktionsstatus 0 "EA_INIT" 1 "EA_OFF" 2 "EA_STANDBY" 3 "EA_PHASE0_AKTIV" 4 "EA_PHASE1_AKTIV" 5 "EA_PHASE2_AKTIV" 6 "EA_PHASE3_AKTIV" 7 "EA_REVERSIBLER_FEHLER" 8 "EA_IRREVERSIBLER_FEHLER" ;
VAL_ 420 EA_Gurtstraffer_Anf 0 "Keine_Anforderung" 1 "Haptik_1" 2 "Haptik_2" 3 "Haptik_3" ;
VAL_ 420 EA_Anforderung_HMS 0 "keine_Anforderung" 1 "halten" 2 "parken" 3 "halten_Standby" 4 "anfahren" 5 "Loesen_ueber_Rampe" 6 "Parken_mit_P" ;
VAL_ 420 EA_Sollbeschleunigung 2046 "Neutralwert" 2047 "Fehler" ;
VAL_ 496 EA_Texte 0 "keine_Anzeige" 1 "Nothalteassistent_fehlende_Fahreraktivitaet" 2 "Nothalteassistent_aktiv_Fahrzeugfuehrung_uebernehmen" 3 "Nothalteassistent_automatischer_Nothalt_wird_durchgefuehrt" 4 "Nothalteassistent_automatischer_Nothalt_durchgefuehrt" 5 "Nothalteassistent_Verbindung_zum_Notruf_wird_aufgebaut" 6 "Nothalteassistent_deaktiviert" 7 "Nothalteassistent_Eingriff_abgebrochen" 8 "Nothalteassistent_fehlende_Fahreraktivitaet_2" 9 "Sekundenschlaf_erkannt" 10 "LaneAssist_Lenkung_uebernehmen" 11 "ACA_Fahrzeugfuehrung_uebernehmen" 14 "Nothalteassistent_nicht_verfuegbar_reversibel" 15 "Nothalteassistent_Stoerung_irreversibel" ;
VAL_ 496 ACF_Lampe_Hands_Off 0 "keine_Anzeige" 1 "Hands_Off_erkannt" ;
VAL_ 496 EA_Infotainment_Anf 0 "Init" 1 "Keine_Absenkung" 2 "Absenkung" 3 "Mute" ;
VAL_ 496 EA_Tueren_Anf 0 "Keine_Anforderung" 1 "Tueren_entriegeln" ;
VAL_ 496 EA_Innenraumlicht_Anf 0 "Innenraumbeleuchtung_ausschalten" 1 "Innenraumbeleuchtung_einschalten" ;
VAL_ 496 zFAS_Warnblinken 0 "Aus" 1 "Statisch" 2 "Taster" 3 "Statisch_ohne_WBT" ;
VAL_ 496 STP_Primaeranz 0 "keine_Anzeige" 1 "Verfuegbar" 2 "Aktiv" 3 "Uebernahme" 4 "Aktiv_Warnung" 5 "Nicht_Verfuegbar" ;
VAL_ 496 EA_Bremslichtblinken 0 "kein_Blinken" 1 "Anforderung_Bremslichtblinken" ;
VAL_ 496 EA_Blinken 0 "Kein_Blinken" 1 "Wechselblinken_links" 2 "Wechselblinken_rechts" 3 "Warnblinken" 4 "Warnblinken_Taster" ;
VAL_ 2527679980 eCall_Statuslicht_Farbe2 0 "Aus" 1 "Blinken_1" 2 "Blinken_2" 3 "An" ;
VAL_ 2527679980 eCall_Statuslicht_Farbe1 0 "Aus" 1 "Blinken_1" 2 "Blinken_2" 3 "An" ;
VAL_ 2527679980 bCall_active 0 "bcall inactive" 1 "bcall active" ;
VAL_ 2527679980 eCall_Funktionsstatus 0 "kein_Fehler" 1 "Fkt_eingeschraenkt" 2 "Fkt_eingeschraenkt_service" 3 "Fkt_nicht_verfuegbar" 4 "Fkt_Service" 5 "Fkt_deaktiviert" 6 "Fkt_aktiviert" 7 "init" ;
VAL_ 2527679980 eCall_Subscription 0 "Init" 1 "unsubscribed" 2 "subscribed" ;
VAL_ 2527679980 eCall_Funktionsstatus_02 0 "kein_Fehler" 1 "Manueller_Notruf_aktiv" 2 "Automatischer_Notruf_aktiv" 7 "Init" ;
VAL_ 1603 KBI_Einheit_Datum 0 "Tag/Monat/Jahr" 1 "Monat/Tag/Jahr" 2 "Jahr/Monat/Tag" 3 "reserviert" ;
VAL_ 1603 KBI_Einheit_Druck 0 "Druckangabe in bar" 1 "Druckangabe in psi" 2 "Druckangabe in kPa" 3 "tbd." ;
VAL_ 1603 KBI_Einheit_Streckenanz 0 "Kilometer" 1 "Meilen" ;
VAL_ 1603 KBI_MFA_v_Einheit_02 0 "kmh" 1 "mph" ;
VAL_ 1603 KBI_Einheit_Temp 0 "Grad Celsius °C" 1 "Grad Fahrenheit °F" ;
VAL_ 1603 KBI_Einheit_Uhrzeit 0 "24h" 1 " 12h AM/PM" ;
VAL_ 1603 KBI_Einheit_Verbrauch 0 "mpg UK" 1 "mpg USA" 2 "Liter/100km" 3 "km/Liter" ;
VAL_ 1603 KBI_Einheit_Volumen 0 "Liter" 1 "Gallonen UK" 2 "Gallonen USA" 3 "reserviert" ;
VAL_ 1603 KBI_Einheit_Verbrauch_elektr 0 "kWh_pro_100km" 1 "km_pro_kWh" 2 "kWh_pro_100mls" 3 "mls_pro_kWh" 4 "MPGe" ;
VAL_ 1603 KBI_Einheit_Verbrauch_Gas 0 "kg_per_100km" 1 "km_per_kg" 2 "m3_per_100km" 3 "km_per_m3" 4 "miles_per_lbs" 5 "miles_per_yard3" 6 "miles_per_kg" 7 "miles_per_m3" 8 "miles_per_gallon_equivalent_US" ;
VAL_ 1603 KBI_Einheit_Masse 0 "kg" 1 "lbs" 2 "reserviert" ;
VAL_ 260 EPB_QBit_Pedalweg_Kuppl 0 "gültiger Wert" 1 "Ersatz-, Init- oder Fehlerwert" ;
VAL_ 260 EPB_Freig_Verzoeg_Anf 0 "nicht freigegeben" 1 "freigegeben" ;
VAL_ 260 EPB_Pedalweg_Kuppl 0 "Init" 255 "Fehler" ;
VAL_ 260 EPB_DAA_Randbed_erf 0 "Randbed_nicht_erfuellt" 1 "Randbed_erfuellt" ;
VAL_ 260 EPB_Fehlerstatus_02 0 "kein_Fehler" 1 "Fehler_ausserhalb_apply_release" 2 "Fehler_einseitig_apply_release" 3 "Fehler_beidseitig_apply_release" ;
VAL_ 260 EPB_Schalterposition 0 "keine Fahreranforderung" 1 "Fahreranforderung Öffnen" 2 "Fahreranforderung Schließen" 3 "Fehler" ;
VAL_ 260 EPB_QBit_Schalterpos 0 "gültiger Wert (volle Funktion)" 1 " Ersatz-, Init- oder Fehlerwert (Schalter ausser Funktion)" ;
VAL_ 260 EPB_Spannkraft 30 "Init" 31 "Fehler" ;
VAL_ 260 EPB_Status_02 0 "offen" 1 "geschlossen_Parken" 2 "teilgespannt_Halten" 3 "im_Lauf_oeffnen" 4 "im_Lauf_schliessen" 5 "tbd" 6 "Init" 7 "unbekannt" ;
VAL_ 259 ESP_VL_FR 0 "Vorwaerts" 1 "Rueckwaerts" ;
VAL_ 259 ESP_VR_FR 0 "Vorwaerts" 1 "Rueckwaerts" ;
VAL_ 259 ESP_HL_FR 0 "Vorwaerts" 1 "Rueckwaerts" ;
VAL_ 259 ESP_HR_FR 0 "Vorwaerts" 1 "Rueckwaerts" ;
VAL_ 259 ESP_VL_Radgeschw 4093 "Unterspannung" 4094 "Init" 4095 "Fehler" ;
VAL_ 259 ESP_VR_Radgeschw 4093 "Unterspannung" 4094 "Init" 4095 "Fehler" ;
VAL_ 259 ESP_HL_Radgeschw 4093 "Unterspannung" 4094 "Init" 4095 "Fehler" ;
VAL_ 259 ESP_HR_Radgeschw 4093 "Unterspannung" 4094 "Init" 4095 "Fehler" ;
VAL_ 914 ESP_Allrad_Antrieb 0 "Front" 1 "Allrad" ;
VAL_ 914 ESP_Codierung_ADS 0 "Init" 1 "ESP_nicht_ADS_codiert" 2 "ADS_codiert" 3 "tbd" ;
VAL_ 914 ESP_RTA_HL 254 "Abgleich_nocht_nicht_genuegend_konvergent" 255 "Fehler" ;
VAL_ 914 ESP_RTA_HR 254 "Abgleich_nocht_nicht_genuegend_konvergent" 255 "Fehler" ;
VAL_ 914 ESP_RTA_VR 254 "Abgleich_nocht_nicht_genuegend_konvergent" 255 "Fehler" ;
VAL_ 914 OBD_Fehler_Radsensor_HL 0 "kein Fehler / Init / nicht verbaut" 1 "KS- (Kurzschluss nach minus)" 2 "KS+ (Kurzschluss nach plus)" 3 "OC (Leitungsunterbrechung)" 4 "OOR+ (Signal zu gross)" 5 "OOR- (Signal zu klein)" 6 "RC+ (Signal unplausibel zu gross)" 7 "RC- (Signal unplausibel zu klein)" 8 "KS+/OC (Kurzschluss nach plus/Unterbrechung)" 9 "KS-/OC  (Kurzschluss nach minus/Unterbrechung)" 10 "KS-/KS+  (Kurzschluss nach minus/plus)" 11 "KS-/KS+/OC (Kurzschluss nach minus/plus/Unterbrechung)" 12 "frei" 13 "frei" 14 "frei" 15 "frei" ;
VAL_ 914 OBD_Fehler_Radsensor_HR 0 "kein Fehler / Init / nicht verbaut" 1 "KS- (Kurzschluss nach minus)" 2 "KS+ (Kurzschluss nach plus)" 3 "OC (Leitungsunterbrechung)" 4 "OOR+ (Signal zu gross)" 5 "OOR- (Signal zu klein)" 6 "RC+ (Signal unplausibel zu gross)" 7 "RC- (Signal unplausibel zu klein)" 8 "KS+/OC (Kurzschluss nach plus/Unterbrechung)" 9 "KS-/OC  (Kurzschluss nach minus/Unterbrechung)" 10 "KS-/KS+  (Kurzschluss nach minus/plus)" 11 "KS-/KS+/OC (Kurzschluss nach minus/plus/Unterbrechung)" 12 "frei" 13 "frei" 14 "frei" 15 "frei" ;
VAL_ 914 OBD_Fehler_Radsensor_VL 0 "kein Fehler / Init / nicht verbaut" 1 "KS- (Kurzschluss nach minus)" 2 "KS+ (Kurzschluss nach plus)" 3 "OC (Leitungsunterbrechung)" 4 "OOR+ (Signal zu gross)" 5 "OOR- (Signal zu klein)" 6 "RC+ (Signal unplausibel zu gross)" 7 "RC- (Signal unplausibel zu klein)" 8 "KS+/OC (Kurzschluss nach plus/Unterbrechung)" 9 "KS-/OC  (Kurzschluss nach minus/Unterbrechung)" 10 "KS-/KS+  (Kurzschluss nach minus/plus)" 11 "KS-/KS+/OC (Kurzschluss nach minus/plus/Unterbrechung)" 12 "frei" 13 "frei" 14 "frei" 15 "frei" ;
VAL_ 914 OBD_Fehler_Radsensor_VR 0 "kein Fehler / Init / nicht verbaut" 1 "KS- (Kurzschluss nach minus)" 2 "KS+ (Kurzschluss nach plus)" 3 "OC (Leitungsunterbrechung)" 4 "OOR+ (Signal zu gross)" 5 "OOR- (Signal zu klein)" 6 "RC+ (Signal unplausibel zu gross)" 7 "RC- (Signal unplausibel zu klein)" 8 "KS+/OC (Kurzschluss nach plus/Unterbrechung)" 9 "KS-/OC  (Kurzschluss nach minus/Unterbrechung)" 10 "KS-/KS+  (Kurzschluss nach minus/plus)" 11 "KS-/KS+/OC (Kurzschluss nach minus/plus/Unterbrechung)" 12 "frei" 13 "frei" 14 "frei" 15 "frei" ;
VAL_ 914 ESP_Qualifizierung_Antriebsart 0 "alte_Bedeutung_Bit_ESP_Allrad_Antrieb" 1 "neue_Bedeutung_Bit_ESP_Allrad_Antrieb" ;
VAL_ 914 ESP_Offroad_Modus 0 "kein_ESP_Offroadmodus" 1 "ESP_Offroadmodus" ;
VAL_ 914 ESP_MKB_ausloesbar 0 "Multikollisionsbremsung_nicht_freigeschaltet" 1 "Multikollisionsbremsung_freigeschaltet" ;
VAL_ 914 ESP_Stat_FallBack_eBKV 0 "Rueckfallebene_nicht_vorhanden" 1 "Rueckfallebene_vorhanden" ;
VAL_ 914 ESC_cAQP_Trigger 0 "AQP_Trigger_nicht_aktiv" 1 "AQP_Trigger_aktiv" ;
VAL_ 914 ESP_OBD_Status 0 "MIL_aus" 1 "MIL_ein" ;
VAL_ 914 ESP_Rollenmodus_Deaktivieren 0 "keine_Aenderung" 1 "Abbruch" ;
VAL_ 914 ESP_nachtr_Stopp_Anf 0 "nicht_angefordert" 1 "angefordert" ;
VAL_ 278 ESP_QBit_Wegimpuls_VL 0 "gueltiger_Wert" 1 "Ersatz_Init_oder_Fehlerwert" ;
VAL_ 278 ESP_QBit_Wegimpuls_VR 0 "gueltiger_Wert" 1 "Ersatz_Init_oder_Fehlerwert" ;
VAL_ 278 ESP_QBit_Wegimpuls_HL 0 "gueltiger_Wert" 1 "Ersatz_Init_oder_Fehlerwert" ;
VAL_ 278 ESP_QBit_Wegimpuls_HR 0 "gueltiger_Wert" 1 "Ersatz_Init_oder_Fehlerwert" ;
VAL_ 278 ESP_Wegimpuls_VL 1021 "Init" 1022 "Unterspannung" 1023 "Fehler" ;
VAL_ 278 ESP_Wegimpuls_VR 1021 "Init" 1022 "Unterspannung" 1023 "Fehler" ;
VAL_ 278 ESP_Wegimpuls_HL 1021 "Init" 1022 "Unterspannung" 1023 "Fehler" ;
VAL_ 278 ESP_Wegimpuls_HR 1021 "Init" 1022 "Unterspannung" 1023 "Fehler" ;
VAL_ 278 ESP_VL_Fahrtrichtung 0 "Vorwaerts" 1 "Rueckwaerts" 2 "Init" 3 "ungueltig_oder_nicht_verbaut" ;
VAL_ 278 ESP_VR_Fahrtrichtung 0 "Vorwaerts" 1 "Rueckwaerts" 2 "Init" 3 "ungueltig_oder_nicht_verbaut" ;
VAL_ 278 ESP_HL_Fahrtrichtung 0 "Vorwaerts" 1 "Rueckwaerts" 2 "Init" 3 "ungueltig_oder_nicht_verbaut" ;
VAL_ 278 ESP_HR_Fahrtrichtung 0 "Vorwaerts" 1 "Rueckwaerts" 2 "Init" 3 "ungueltig_oder_nicht_verbaut" ;
VAL_ 418 HMS_P_beibehalten_GE 0 "P_nicht_beibehalten" 1 "P_beibehalten" 2 "Init" 3 "Fehler" ;
VAL_ 418 HMS_Konsistenz_GE 0 "kein_Fehler_erkannt" 1 "Fehler_erkannt" ;
VAL_ 418 HMS_Konsistenz_IPA 0 "kein_Fehler_erkannt" 1 "Fehler_erkannt" ;
VAL_ 418 HMS_Konsistenz_STA 0 "kein_Fehler_erkannt" 1 "Fehler_erkannt" ;
VAL_ 418 HMS_Konsistenz_MO 0 "kein_Fehler_erkannt" 1 "Fehler_erkannt" ;
VAL_ 418 HMS_halten_nicht_verfuegbar 0 "verfuegbar" 1 "nicht_verfuegbar" ;
VAL_ 418 NL_PRIM_STP_01_Status 0 "Notlauf_inaktiv" 1 "Notlauf_bereit" 2 "Notlauf_aktiv" 3 "Notlauf_nicht_verfuegbar" ;
VAL_ 418 VMM_Warnblinken 0 "Aus" 1 "An" ;
VAL_ 418 VZM_Status 0 "Initialisierung" 1 "Verfuegbar" 2 "Verfuegbar_mit_eingeschraenkter_Performance" 3 "Nicht_Verfuegbar" 4 "Fehler" ;
VAL_ 418 HMS_Notstopp_Status 0 "Off_Init" 1 "Inaktiv" 2 "Ready" 3 "Aktiv" 4 "Pending" 7 "nicht_Verfuegbar" ;
VAL_ 418 HMS_parken_nicht_verfuegbar 0 "verfuegbar" 1 "nicht_verfuegbar" ;
VAL_ 418 HMS_Anforderung_GE 0 "keine_Anforderung" 1 "P_einlegen" ;
VAL_ 418 HMS_Systemstatus 0 "keine_Funktion_aktiv" 1 "Halten_aktiv" 2 "Parken_angefordert" 3 "Parken_aktiv" 4 "Parken_beibehalten_aktiv" 5 "Anfahren_aktiv" 6 "Loeseanforderung_aktiv" 7 "Loeseanforderung_durch_Fahrer" 8 "Abrutschen_erkannt" 9 "Halten_Standby_aktiv" 10 "Anfahren_Standby_aktiv" 14 "Init" 15 "Fehler" ;
VAL_ 418 HMS_Stillstand 0 "kein_Stillstand" 1 "Stillstand_frueh" 2 "Stillstand" 6 "Init" 7 "Fehler" ;
VAL_ 418 HMS_aktives_System 0 "kein_System__Init_Fehler" 1 "Fahreranforderung_aktiv" 2 "HMS_intern_aktiv" 3 "ACC_aktiv" 4 "Autohold_aktiv" 5 "HHC_aktiv" 6 "HVLM_aktiv" 7 "Getriebe_aktiv" 8 "EBKV_aktiv" 9 "IPA_aktiv" 10 "ARA_aktiv" 12 "autonomous_Hold_aktiv" 13 "STA_aktiv" 14 "Motor_aktiv" 15 "EA_aktiv" ;
VAL_ 418 HMS_Konsistenz_HVLM 0 "kein_Fehler_erkannt" 1 "Fehler_erkannt" ;
VAL_ 418 HMS_Konsistenz_ACC 0 "kein_Fehler_erkannt" 1 "Fehler_erkannt" ;
VAL_ 418 HMS_Fehlerstatus 0 "kein_Fehler" 1 "Halten_nicht_moeglich" 2 "Sonderbetriebsmodus_aktiv" 3 "Systemeinschraenkung" 4 "Systemstoerung" ;
VAL_ 418 ESP_Index_Haltemoment 0 "Bremsmoment" 1 "Antriebsmoment" ;
VAL_ 418 ESP_Haltemoment 1022 "Init" 1023 "Fehler" ;
VAL_ 253 BR_Eingriffsmoment 1022 "Init" 1023 "Fehler" ;
VAL_ 253 ESP_Diagnose 0 "ESP_nicht_in_Diagnose" 1 "ESP_in_Diagnose" ;
VAL_ 253 ESC_v_Signal_Qualifier_High_Low 0 "Gueteschwelle_kleiner_1kmh" 1 "Gueteschwelle_kleiner_3kmh" 2 "Gueteschwelle_kleiner_5kmh" 3 "Gueteschwelle_kleiner_10kmh" 4 "Gueteschwelle_kleiner_20kmh" 5 "Gueteschwelle_groessergleich_20kmh" 6 "Init" 7 "Fehler" ;
VAL_ 253 ESP_Vorsteuerung 0 "keine_Vorsteuerung_aktiv" 1 "Vorsteuerung_aktiv" ;
VAL_ 253 OBD_Schlechtweg 0 "kein_Schlechtweg_erkannt" 1 "Schlechtweg_erkannt" ;
VAL_ 253 OBD_QBit_Schlechtweg 0 "gueltiger_Wert" 1 "Ersatz_Init_oder_Fehlerwert" ;
VAL_ 253 ESP_v_Signal 65533 "Unterspannung" 65534 "Init" 65535 "Fehler" ;
VAL_ 253 ASR_Tastung_passiv 0 "ASR_aktiviert" 1 "ASR_passiv_getastet_oder_Schwellen_geaendert" ;
VAL_ 253 ESP_Tastung_passiv 0 "ESP_aktiviert" 1 "ESP_passiv_getastet_oder_Schwellen_geaendert" ;
VAL_ 253 ESP_Systemstatus 0 "iO" 1 "Fehler" ;
VAL_ 253 ASR_Schalteingriff 0 "keine_Anforderung" 1 "ASR_Schaltkennfeld" 2 "Rueckschaltung" 3 "Schaltverbot" ;
VAL_ 253 ESP_QBit_v_Signal 0 "gueltiger_Wert" 1 "Ersatz_Init_oder_Fehlerwert" ;
VAL_ 253 ABS_Bremsung 0 "keine_ABS_Regelung" 1 "ABS_Regelung_aktiv" ;
VAL_ 253 ASR_Anf 0 "keine_Anforderung" 1 "ASR_Anforderung" ;
VAL_ 253 MSR_Anf 0 "keine Anfoderung" 1 "MSR-Anforderung" ;
VAL_ 253 EBV_Eingriff 0 "kein_EBV_Eingriff" 1 "EBV_Eingriff" ;
VAL_ 253 EDS_Eingriff 0 "kein_EDS_Eingriff" 1 "EDS_Eingriff" ;
VAL_ 253 ESP_Eingriff 0 "kein_ESP_Eingriff" 1 "ESP_Eingriff_aktiv" ;
VAL_ 253 ESP_ASP 0 "inaktiv" 1 "aktiv" ;
VAL_ 253 ESC_Neutralschaltung 0 "keine_Anforderung" 1 "Neutralschaltung_angefordert" ;
VAL_ 1470 ESP_Gierrate_Offset_2 2046 "Init" 2047 "Fehler" ;
VAL_ 1470 ESP_Lenkwinkel_Offset 510 "Init" 511 "Fehler" ;
VAL_ 1470 BR_QBit_Reifenumfang_sekundaer 0 "gueltiger_Wert" 1 "Ersatz_Init_oder_Fehlerwert" ;
VAL_ 1470 ESP_Querbeschleunigung_Offset 62 "Init" 63 "Fehler" ;
VAL_ 1470 ESP_Laengsbeschleunigung_Offset 254 "Init" 255 "Fehler" ;
VAL_ 508 ESP_Status_Bremsentemp_02 0 "nicht_erhoeht" 1 "Schwelle_1" 2 "Schwelle_2" ;
VAL_ 508 ESP_Aggregataktivitaet 0 "inaktiv" 1 "aktiv" ;
VAL_ 508 ESP_Stillstandsflag 0 "kein_Stillstand_erkannt" 1 "Stillstand_erkannt" ;
VAL_ 508 ESC_MBK_Meldungen 0 "kein_Text" 1 "MBK_Hinweis_aktiv" 2 "MBK_Eskalation1_aktiv" ;
VAL_ 508 ESP_EDS_Anzeige 0 "Keine_Anzeige_aktiv" 1 "EDS_nicht_aktiv" 2 "EDS_aktiv_an_VA" 3 "EDS_aktiv_an_HA" 4 "EDS_aktiv_an_VA_und_HA" 5 "EDS_Uebertemperatur" 6 "EDS_Fehler" ;
VAL_ 508 RLE_Anzeigen 0 "keine_Anzeige" 1 "Rad_lose_allgemein" 2 "Rad_VL_lose" 3 "Rad_VR_lose" 4 "Rad_HL_lose" 5 "Rad_HR_lose" 6 "RLE_Pruefphase" 7 "RLE_Systemstoerung" ;
VAL_ 508 ESP_Wiederstart_Anz_Std 0 "keine_Anzeige" 1 "Standard_Wiederstartgrund" ;
VAL_ 508 ESC_Anforderung_Airbrake 0 "keine_Anforderung" 1 "Anf_Bremsperformancestellung" ;
VAL_ 508 ESC_FBA_Meldungen 0 "kein_Text" 1 "FBA_Warnung_aktiv_MT" 2 "FBA_Warnung_aktiv_AT" ;
VAL_ 508 ESP_Rollover_Status_dyn 0 "Auspraegung1" 1 "Auspraegung2" 2 "Auspraegung3" 3 "Auspraegung4" ;
VAL_ 508 ESP_Rollover_Status_stat 0 "Auspraegung1" 1 "Auspraegung2" 2 "Auspraegung3" 3 "Auspraegung4" ;
VAL_ 508 ESP_AVH_LED 0 "LED_aus" 1 "LED_ein" 2 "LED_blinken" 3 "Funktion_gesperrt__LED_aus" 6 "Init" ;
VAL_ 508 ESP_HDC_LED 0 "LED_aus" 1 "LED_ein" 2 "LED_blinken" 3 "Funktion_gesperrt__LED_aus" 6 "Init" ;
VAL_ 508 ESP_Off_LED 0 "LED_aus" 1 "LED_ein" 2 "LED_blinken" 3 "Funktion_gesperrt__LED_aus" 6 "Init" ;
VAL_ 508 ESP_Notbremsanzeige 0 "keine_Notbremsung_erkannt" 1 "Notbremsung_erkannt" ;
VAL_ 508 ESC_Motorstartverzoegerung 0 "Startfreigabe" 1 "Anforderung_Startverzoegerung" ;
VAL_ 508 ESP_Offroad_Lampe 0 "Aus" 1 "Ein" ;
VAL_ 508 ESP_HDC_Textanzeigen 0 "kein_Text" 1 "HDC_ein" 2 "HDC_aus" 3 "HDC_nicht_verfuegbar_in_FahrPr" 4 "HDC_nicht_verfuegbar_Uebertemp" 5 "HDC_verfuegbar_keine_Uebertemp" 6 "HDC_nicht_verfuegbar_ACC_aktiv" 7 "HDC_nicht_verfuegbar_GRA_aktiv" 8 "HDC_nicht_verfuegbar_LIM_aktiv" 9 "HDC_nicht_verfuegbar_IPA_aktiv" 10 "HDC_nicht_verfuegbar_PLA_aktiv" 11 "HDC_nicht_verf_anderes_Syst_akt" 12 "HDC_nicht_verfuegbar_Fehler" 13 "GRA_Hebel_einschalten" 14 "Funk_nicht_verfuegbar_bei_HDC" 15 "Funk_verfuegbar_wenn_HDC_aktiv" 16 "Deaktivierung_ESP_Eingriff" 17 "HDC_nicht_verfuegbar_ABS_solo" 18 "HDC_nicht_verfuegbar_Gaspedal" ;
VAL_ 508 ESP_HOLD_verf 0 "nicht_verfuegbar" 1 "verfuegbar" ;
